VERSION "HIPBNNNYNNNNNNNNNNNNNNNNNNNNNNNNNNYYNNNNNN/4>%%%/4/'%**4NNN///"

NS_ :

BS_:

BU_: ADC CDC DDM VNC Vector_XXX

BO_ 417 AVN1SD6: 32 CDC
 SG_ FRMSID1 : 7|5@0+ (1,0) [0|0] "-"  ADC
 SG_ MAPCNTR : 2|2@0+ (1,0) [0|0] "-"  ADC
 SG_ NAVTYP : 0|3@0+ (1,0) [0|0] "-"  ADC
 SG_ MNAVOPST : 13|3@0+ (1,0) [0|0] "-"  ADC
 SG_ MNAVRGST : 10|2@0+ (1,0) [0|0] "-"  ADC
 SG_ DAYLOCUP : 8|16@0+ (1,0) [0|0] "-"  ADC
 SG_ DAYCENUP : 24|16@0+ (1,0) [0|0] "-"  ADC
 SG_ SUBDIVCD : 40|6@0+ (1,0) [0|0] "-"  ADC
 SG_ SNBINF3 : 50|3@0+ (1,0) [0|0] "-"  ADC
 SG_ SNBINF4 : 63|3@0+ (1,0) [0|0] "-"  ADC
 SG_ SNBUNT3 : 60|1@0+ (1,0) [0|0] "-"  ADC
 SG_ SNBUNT4 : 59|1@0+ (1,0) [0|0] "-"  ADC
 SG_ SNBDIST3 : 58|8@0+ (1,0) [0|0] "m"  ADC
 SG_ SNBDIST4 : 66|8@0+ (1,0) [0|0] "m"  ADC
 SG_ SPLUNT3 : 74|1@0+ (1,0) [0|0] "-"  ADC
 SG_ SPLUNT4 : 73|1@0+ (1,0) [0|0] "-"  ADC
 SG_ SPLDIST3 : 72|8@0+ (1,0) [0|0] "m"  ADC
 SG_ SPLDIST4 : 80|8@0+ (1,0) [0|0] "m"  ADC
 SG_ STINF : 88|2@0+ (1,0) [0|0] "-"  ADC
 SG_ STDU : 102|1@0+ (1,0) [0|0] "-"  ADC
 SG_ STDIST : 101|8@0+ (1,0) [0|0] "m"  ADC
 SG_ TRLUNT3 : 109|1@0+ (1,0) [0|0] "-"  ADC
 SG_ TRLUNT4 : 108|1@0+ (1,0) [0|0] "-"  ADC
 SG_ TRLUNT5 : 107|1@0+ (1,0) [0|0] "-"  ADC
 SG_ TRLUNT6 : 106|1@0+ (1,0) [0|0] "-"  ADC
 SG_ TRLDIST3 : 105|8@0+ (1,0) [0|0] "m"  ADC
 SG_ TRLDIST4 : 113|8@0+ (1,0) [0|0] "m"  ADC
 SG_ TRLDIST5 : 121|8@0+ (1,0) [0|0] "m"  ADC
 SG_ TRLDIST6 : 129|8@0+ (1,0) [0|0] "m"  ADC
 SG_ TRLUNT1 : 137|1@0+ (1,0) [0|0] "-"  ADC
 SG_ TRLUNT2 : 136|1@0+ (1,0) [0|0] "-"  ADC
 SG_ TRLDIST1 : 151|8@0+ (1,0) [0|0] "m"  ADC
 SG_ TRLDIST2 : 159|8@0+ (1,0) [0|0] "m"  ADC
 SG_ SNBINF1 : 167|3@0+ (1,0) [0|0] "-"  ADC
 SG_ SNBUNT1 : 164|1@0+ (1,0) [0|0] "-"  ADC
 SG_ SNBDIST1 : 163|8@0+ (1,0) [0|0] "m"  ADC
 SG_ SNBINF2 : 171|3@0+ (1,0) [0|0] "-"  ADC
 SG_ SNBUNT2 : 168|1@0+ (1,0) [0|0] "-"  ADC
 SG_ SNBDIST2 : 183|8@0+ (1,0) [0|0] "m"  ADC
 SG_ SPLUNT1 : 191|1@0+ (1,0) [0|0] "-"  ADC
 SG_ SPLDIST1 : 190|8@0+ (1,0) [0|0] "m"  ADC
 SG_ SPLUNT2 : 198|1@0+ (1,0) [0|0] "-"  ADC
 SG_ SPLDIST2 : 197|8@0+ (1,0) [0|0] "m"  ADC
 SG_ SENSST : 205|3@0+ (1,0) [0|0] "-"  ADC
 SG_ SENSORF : 202|3@0+ (1,0) [0|0] "-"  ADC
 SG_ RTGUIDST : 215|2@0+ (1,0) [0|0] "-"  ADC
 SG_ MAPMCNFD : 213|8@0+ (1,0) [0|0] "-"  ADC
 SG_ MLTMDST : 221|2@0+ (1,0) [0|0] "-"  ADC
 SG_ MAPCVR : 219|2@0+ (1,0) [0|0] "-"  ADC
 SG_ MAPCNFLG : 217|2@0+ (1,0) [0|0] "-"  ADC
 SG_ MAPTYRO : 231|2@0+ (1,0) [0|0] "-"  ADC
 SG_ RERTCNTR : 229|4@0+ (1,0) [0|0] "-"  ADC
 SG_ CNTRYCD : 225|10@0+ (1,0) [0|0] "-"  ADC

BO_ 418 AVN1SD7: 32 CDC
 SG_ FRMSID2 : 7|5@0+ (1,0) [0|0] "-"  ADC
 SG_ TOLDU2 : 2|1@0+ (1,0) [0|0] "-"  ADC
 SG_ TOLDU3 : 1|1@0+ (1,0) [0|0] "-"  ADC
 SG_ TOLDIST2 : 0|8@0+ (1,0) [0|0] "m"  ADC
 SG_ TOLDIST3 : 8|8@0+ (1,0) [0|0] "m"  ADC
 SG_ TOLSTY2 : 16|8@0+ (1,0) [0|0] "-"  ADC
 SG_ TOLSTY3 : 24|8@0+ (1,0) [0|0] "-"  ADC
 SG_ PAYMT1 : 32|10@0+ (1,0) [0|0] "-"  ADC
 SG_ PAYMT2 : 54|10@0+ (1,0) [0|0] "-"  ADC
 SG_ PAYMT3 : 60|10@0+ (1,0) [0|0] "-"  ADC
 SG_ RLDXUNT3 : 66|1@0+ (1,0) [0|0] "-"  ADC
 SG_ RLDXUNT4 : 65|1@0+ (1,0) [0|0] "-"  ADC
 SG_ RLDXDST3 : 64|8@0+ (1,0) [0|0] "m"  ADC
 SG_ RLDXDST4 : 72|8@0+ (1,0) [0|0] "m"  ADC
 SG_ FWMED1 : 80|2@0+ (1,0) [0|0] "-"  ADC
 SG_ FWMED2 : 94|2@0+ (1,0) [0|0] "-"  ADC
 SG_ FWMED3 : 92|2@0+ (1,0) [0|0] "-"  ADC
 SG_ FWMED4 : 90|2@0+ (1,0) [0|0] "-"  ADC
 SG_ FWMED5 : 88|2@0+ (1,0) [0|0] "-"  ADC
 SG_ MEDDU1 : 102|1@0+ (1,0) [0|0] "-"  ADC
 SG_ MEDDU2 : 101|1@0+ (1,0) [0|0] "-"  ADC
 SG_ MEDDU3 : 100|1@0+ (1,0) [0|0] "-"  ADC
 SG_ MEDDU4 : 99|1@0+ (1,0) [0|0] "-"  ADC
 SG_ MEDDU5 : 98|1@0+ (1,0) [0|0] "-"  ADC
 SG_ MEDDIST1 : 97|8@0+ (1,0) [0|0] "m"  ADC
 SG_ MEDDIST2 : 105|8@0+ (1,0) [0|0] "m"  ADC
 SG_ MEDDIST3 : 113|8@0+ (1,0) [0|0] "m"  ADC
 SG_ MEDDIST4 : 121|8@0+ (1,0) [0|0] "m"  ADC
 SG_ MEDDIST5 : 129|8@0+ (1,0) [0|0] "m"  ADC
 SG_ MPMEDFLG : 137|2@0+ (1,0) [0|0] "-"  ADC
 SG_ MPLNNUM : 151|4@0+ (1,0) [0|0] "-"  ADC
 SG_ LNNUMDU1 : 147|1@0+ (1,0) [0|0] "-"  ADC
 SG_ LNNUMDU2 : 146|1@0+ (1,0) [0|0] "-"  ADC
 SG_ LNNUMDU3 : 145|1@0+ (1,0) [0|0] "-"  ADC
 SG_ LNNUM1 : 144|4@0+ (1,0) [0|0] "-"  ADC
 SG_ LNNUM2 : 156|4@0+ (1,0) [0|0] "-"  ADC
 SG_ LNNUM3 : 152|4@0+ (1,0) [0|0] "-"  ADC
 SG_ LNNUMD1 : 164|8@0+ (1,0) [0|0] "m"  ADC
 SG_ LNNUMD2 : 172|8@0+ (1,0) [0|0] "m"  ADC
 SG_ LNNUMD3 : 180|8@0+ (1,0) [0|0] "m"  ADC
 SG_ DFLGDU1 : 188|1@0+ (1,0) [0|0] "-"  ADC
 SG_ DFLGD1 : 187|8@0+ (1,0) [0|0] "m"  ADC
 SG_ DFLGD2 : 195|8@0+ (1,0) [0|0] "m"  ADC
 SG_ MPOSDFLG : 203|2@0+ (1,0) [0|0] "-"  ADC
 SG_ DWAYFLG1 : 201|2@0+ (1,0) [0|0] "-"  ADC
 SG_ DWAYFLG2 : 215|2@0+ (1,0) [0|0] "-"  ADC
 SG_ DFLGDU2 : 213|1@0+ (1,0) [0|0] "-"  ADC
 SG_ TOLDU1 : 212|1@0+ (1,0) [0|0] "-"  ADC
 SG_ TOLDIST1 : 211|8@0+ (1,0) [0|0] "m"  ADC
 SG_ TOLSTY1 : 219|8@0+ (1,0) [0|0] "-"  ADC
 SG_ RLDXUNT1 : 227|1@0+ (1,0) [0|0] "-"  ADC
 SG_ RLDXUNT2 : 226|1@0+ (1,0) [0|0] "-"  ADC
 SG_ RLDXDST1 : 225|8@0+ (1,0) [0|0] "m"  ADC
 SG_ RLDXDST2 : 233|8@0+ (1,0) [0|0] "m"  ADC

BO_ 440 AVN1SD8: 32 CDC
 SG_ FRMSID3 : 7|5@0+ (1,0) [0|0] "-"  ADC
 SG_ LNKTYP1 : 2|10@0+ (1,0) [0|0] "-"  ADC
 SG_ LNKTYP2 : 8|10@0+ (1,0) [0|0] "-"  ADC
 SG_ LNKTYP3 : 30|10@0+ (1,0) [0|0] "-"  ADC
 SG_ LNKTYP4 : 36|10@0+ (1,0) [0|0] "-"  ADC
 SG_ LNKTYP5 : 42|10@0+ (1,0) [0|0] "-"  ADC
 SG_ LNKTYP6 : 48|10@0+ (1,0) [0|0] "-"  ADC
 SG_ LNKTYP7 : 70|10@0+ (1,0) [0|0] "-"  ADC
 SG_ LNKTYP8 : 76|10@0+ (1,0) [0|0] "-"  ADC
 SG_ LNKTYP9 : 82|10@0+ (1,0) [0|0] "-"  ADC
 SG_ LNKTYP10 : 88|10@0+ (1,0) [0|0] "-"  ADC
 SG_ LNKDU1 : 110|1@0+ (1,0) [0|0] "-"  ADC
 SG_ LNKDU2 : 109|1@0+ (1,0) [0|0] "-"  ADC
 SG_ LNKDU3 : 108|1@0+ (1,0) [0|0] "-"  ADC
 SG_ LNKDU4 : 107|1@0+ (1,0) [0|0] "-"  ADC
 SG_ LNKDU5 : 106|1@0+ (1,0) [0|0] "-"  ADC
 SG_ LNKDU6 : 105|1@0+ (1,0) [0|0] "-"  ADC
 SG_ LNKDU7 : 104|1@0+ (1,0) [0|0] "-"  ADC
 SG_ LNKDU8 : 119|1@0+ (1,0) [0|0] "-"  ADC
 SG_ LNKDU9 : 118|1@0+ (1,0) [0|0] "-"  ADC
 SG_ LNKDU10 : 117|1@0+ (1,0) [0|0] "-"  ADC
 SG_ LNKD1 : 116|8@0+ (1,0) [0|0] "m"  ADC
 SG_ LNKD2 : 124|8@0+ (1,0) [0|0] "m"  ADC
 SG_ LNKD3 : 132|8@0+ (1,0) [0|0] "m"  ADC
 SG_ LNKD4 : 140|8@0+ (1,0) [0|0] "m"  ADC
 SG_ LNKD5 : 148|8@0+ (1,0) [0|0] "m"  ADC
 SG_ LNKD6 : 156|8@0+ (1,0) [0|0] "m"  ADC
 SG_ LNKD7 : 164|8@0+ (1,0) [0|0] "m"  ADC
 SG_ LNKD8 : 172|8@0+ (1,0) [0|0] "m"  ADC
 SG_ LNKD9 : 180|8@0+ (1,0) [0|0] "m"  ADC
 SG_ LNKD10 : 188|8@0+ (1,0) [0|0] "m"  ADC
 SG_ MPLNKTYP : 196|10@0+ (1,0) [0|0] "-"  ADC

BO_ 441 AVN1SD9: 32 CDC
 SG_ FRMSID4 : 7|5@0+ (1,0) [0|0] "-"  ADC
 SG_ MPSPLU : 2|2@0+ (1,0) [0|0] "-"  ADC
 SG_ FWSPD3 : 0|5@0+ (1,0) [0|0] "-"  ADC
 SG_ FWSPD4 : 11|5@0+ (1,0) [0|0] "-"  ADC
 SG_ FWSPD5 : 22|5@0+ (1,0) [0|0] "-"  ADC
 SG_ FWSPD6 : 17|5@0+ (1,0) [0|0] "-"  ADC
 SG_ FWSPD7 : 28|5@0+ (1,0) [0|0] "-"  ADC
 SG_ FWSPTY3 : 39|3@0+ (1,0) [0|0] "-"  ADC
 SG_ FWSPTY4 : 36|3@0+ (1,0) [0|0] "-"  ADC
 SG_ FWSPTY5 : 33|3@0+ (1,0) [0|0] "-"  ADC
 SG_ FWSPTY6 : 46|3@0+ (1,0) [0|0] "-"  ADC
 SG_ FWSPTY7 : 43|3@0+ (1,0) [0|0] "-"  ADC
 SG_ FWSPAU3 : 40|6@0+ (1,0) [0|0] "-"  ADC
 SG_ FWSPAU4 : 50|6@0+ (1,0) [0|0] "-"  ADC
 SG_ FWSPAU5 : 60|6@0+ (1,0) [0|0] "-"  ADC
 SG_ FWSPAU6 : 70|6@0+ (1,0) [0|0] "-"  ADC
 SG_ FWSPAU7 : 64|6@0+ (1,0) [0|0] "-"  ADC
 SG_ FWSPLU1 : 74|2@0+ (1,0) [0|0] "-"  ADC
 SG_ FWSPLU2 : 72|2@0+ (1,0) [0|0] "-"  ADC
 SG_ FWSPLU3 : 86|2@0+ (1,0) [0|0] "-"  ADC
 SG_ FWSPLU4 : 84|2@0+ (1,0) [0|0] "-"  ADC
 SG_ FWSPLU5 : 82|2@0+ (1,0) [0|0] "-"  ADC
 SG_ FWSPLU6 : 80|2@0+ (1,0) [0|0] "-"  ADC
 SG_ FWSPLU7 : 94|2@0+ (1,0) [0|0] "-"  ADC
 SG_ SPDISTU3 : 92|1@0+ (1,0) [0|0] "-"  ADC
 SG_ SPDISTU4 : 91|1@0+ (1,0) [0|0] "-"  ADC
 SG_ SPDISTU5 : 90|1@0+ (1,0) [0|0] "-"  ADC
 SG_ SPDISTU6 : 89|1@0+ (1,0) [0|0] "-"  ADC
 SG_ SPDISTU7 : 88|1@0+ (1,0) [0|0] "-"  ADC
 SG_ SPDIST3 : 103|8@0+ (1,0) [0|0] "m"  ADC
 SG_ SPDIST4 : 111|8@0+ (1,0) [0|0] "m"  ADC
 SG_ SPDIST5 : 119|8@0+ (1,0) [0|0] "m"  ADC
 SG_ SPDIST6 : 127|8@0+ (1,0) [0|0] "m"  ADC
 SG_ SPDIST7 : 135|8@0+ (1,0) [0|0] "m"  ADC
 SG_ MPOWFLG : 143|3@0+ (1,0) [0|0] "-"  ADC
 SG_ FWOWFLG1 : 140|3@0+ (1,0) [0|0] "-"  ADC
 SG_ OWDU1 : 137|1@0+ (1,0) [0|0] "-"  ADC
 SG_ OWDIST1 : 136|8@0+ (1,0) [0|0] "m"  ADC
 SG_ MPRDTYP : 144|5@0+ (1,0) [0|0] "-"  ADC
 SG_ FWRDTYP1 : 155|5@0+ (1,0) [0|0] "-"  ADC
 SG_ RDTYPDU1 : 166|1@0+ (1,0) [0|0] "-"  ADC
 SG_ RDTYPD1 : 165|8@0+ (1,0) [0|0] "m"  ADC
 SG_ FWRDTYP2 : 173|5@0+ (1,0) [0|0] "-"  ADC
 SG_ RDTYPDU2 : 168|1@0+ (1,0) [0|0] "-"  ADC
 SG_ RDTYPD2 : 183|8@0+ (1,0) [0|0] "m"  ADC
 SG_ MPSP1 : 191|5@0+ (1,0) [0|0] "-"  ADC
 SG_ MPSPTY1 : 186|3@0+ (1,0) [0|0] "-"  ADC
 SG_ MPSPAU1 : 199|6@0+ (1,0) [0|0] "-"  ADC
 SG_ FWSPD1 : 193|5@0+ (1,0) [0|0] "-"  ADC
 SG_ FWSPTY1 : 204|3@0+ (1,0) [0|0] "-"  ADC
 SG_ FWSPAU1 : 201|6@0+ (1,0) [0|0] "-"  ADC
 SG_ SPDISTU1 : 211|1@0+ (1,0) [0|0] "-"  ADC
 SG_ SPDIST1 : 210|8@0+ (1,0) [0|0] "m"  ADC
 SG_ FWSPD2 : 218|5@0+ (1,0) [0|0] "-"  ADC
 SG_ FWSPTY2 : 229|3@0+ (1,0) [0|0] "-"  ADC
 SG_ FWSPAU2 : 226|6@0+ (1,0) [0|0] "-"  ADC
 SG_ SPDISTU2 : 236|1@0+ (1,0) [0|0] "-"  ADC
 SG_ SPDIST2 : 235|8@0+ (1,0) [0|0] "m"  ADC

BO_ 439 AVN1SE1: 32 CDC
 SG_ FRMSID5 : 7|5@0+ (1,0) [0|0] "-"  ADC
 SG_ TNENTDU1 : 2|1@0+ (1,0) [0|0] "-"  ADC
 SG_ TNENTDU2 : 1|1@0+ (1,0) [0|0] "-"  ADC
 SG_ TNENTDU3 : 0|1@0+ (1,0) [0|0] "-"  ADC
 SG_ TNENTDU4 : 15|1@0+ (1,0) [0|0] "-"  ADC
 SG_ TNENTDU5 : 14|1@0+ (1,0) [0|0] "-"  ADC
 SG_ TNENTD1 : 13|8@0+ (1,0) [0|0] "m"  ADC
 SG_ TNENTD2 : 21|8@0+ (1,0) [0|0] "m"  ADC
 SG_ TNENTD3 : 29|8@0+ (1,0) [0|0] "m"  ADC
 SG_ TNENTD4 : 37|8@0+ (1,0) [0|0] "m"  ADC
 SG_ TNENTD5 : 45|8@0+ (1,0) [0|0] "m"  ADC
 SG_ TNVFLG1 : 53|1@0+ (1,0) [0|0] "-"  ADC
 SG_ TNVFLG2 : 52|1@0+ (1,0) [0|0] "-"  ADC
 SG_ TNVFLG3 : 51|1@0+ (1,0) [0|0] "-"  ADC
 SG_ TNVFLG4 : 50|1@0+ (1,0) [0|0] "-"  ADC
 SG_ TNVFLG5 : 49|1@0+ (1,0) [0|0] "-"  ADC
 SG_ TNLEN1 : 48|8@0+ (1,0) [0|0] "m"  ADC
 SG_ TNLEN2 : 56|8@0+ (1,0) [0|0] "m"  ADC
 SG_ TNLEN3 : 64|8@0+ (1,0) [0|0] "m"  ADC
 SG_ TNLEN4 : 72|8@0+ (1,0) [0|0] "m"  ADC
 SG_ TNLEN5 : 80|8@0+ (1,0) [0|0] "m"  ADC
 SG_ BRGDU1 : 88|1@0+ (1,0) [0|0] "-"  ADC
 SG_ BRGDU2 : 103|1@0+ (1,0) [0|0] "-"  ADC
 SG_ BRGDU3 : 102|1@0+ (1,0) [0|0] "-"  ADC
 SG_ BRGDIST1 : 101|8@0+ (1,0) [0|0] "m"  ADC
 SG_ BRGDIST2 : 109|8@0+ (1,0) [0|0] "m"  ADC
 SG_ BRGDIST3 : 117|8@0+ (1,0) [0|0] "m"  ADC
 SG_ BRGVFLG1 : 125|1@0+ (1,0) [0|0] "-"  ADC
 SG_ BRGVFLG2 : 124|1@0+ (1,0) [0|0] "-"  ADC
 SG_ BRGVFLG3 : 123|1@0+ (1,0) [0|0] "-"  ADC
 SG_ BRGLEN1 : 122|8@0+ (1,0) [0|0] "m"  ADC
 SG_ BRGLEN2 : 130|8@0+ (1,0) [0|0] "m"  ADC
 SG_ BRGLEN3 : 138|8@0+ (1,0) [0|0] "m"  ADC

BO_ 437 AVN1SE2: 32 CDC
 SG_ FRMSID6 : 7|5@0+ (1,0) [0|0] "-"  ADC
 SG_ MPOSCURV : 2|10@0- (1,0) [0|0] "-"  ADC
 SG_ CURINFO1 : 8|10@0- (1,0) [0|0] "-"  ADC
 SG_ CURINFO3 : 30|10@0- (1,0) [0|0] "-"  ADC
 SG_ CURINFO4 : 36|10@0- (1,0) [0|0] "-"  ADC
 SG_ MPCURACR : 42|2@0+ (1,0) [0|0] "-"  ADC
 SG_ PCURACR1 : 40|2@0+ (1,0) [0|0] "-"  ADC
 SG_ PCURACR2 : 54|2@0+ (1,0) [0|0] "-"  ADC
 SG_ PCURACR3 : 52|2@0+ (1,0) [0|0] "-"  ADC
 SG_ PCURACR4 : 50|2@0+ (1,0) [0|0] "-"  ADC
 SG_ SCURAC1 : 48|2@0+ (1,0) [0|0] "-"  ADC
 SG_ SCURAC2 : 62|2@0+ (1,0) [0|0] "-"  ADC
 SG_ SCURAC3 : 60|2@0+ (1,0) [0|0] "-"  ADC
 SG_ SCURAC4 : 58|2@0+ (1,0) [0|0] "-"  ADC
 SG_ SCURAC5 : 56|2@0+ (1,0) [0|0] "-"  ADC
 SG_ SCURAC6 : 70|2@0+ (1,0) [0|0] "-"  ADC
 SG_ SCURAC7 : 68|2@0+ (1,0) [0|0] "-"  ADC
 SG_ SCURAC8 : 66|2@0+ (1,0) [0|0] "-"  ADC
 SG_ SCURAC9 : 64|2@0+ (1,0) [0|0] "-"  ADC
 SG_ SCURAC10 : 78|2@0+ (1,0) [0|0] "-"  ADC
 SG_ SCURAC11 : 76|2@0+ (1,0) [0|0] "-"  ADC
 SG_ CURD1 : 74|10@0+ (1,0) [0|0] "-"  ADC
 SG_ CURD2 : 80|10@0+ (1,0) [0|0] "-"  ADC
 SG_ CURVAL11 : 102|10@0- (1,0) [0|0] "-"  ADC
 SG_ CURINF11 : 108|3@0+ (1,0) [0|0] "-"  ADC
 SG_ CURVAL9 : 105|10@0- (1,0) [0|0] "-"  ADC
 SG_ CURINF9 : 127|3@0+ (1,0) [0|0] "-"  ADC
 SG_ CURVAL10 : 124|10@0- (1,0) [0|0] "-"  ADC
 SG_ CURINF10 : 130|3@0+ (1,0) [0|0] "-"  ADC
 SG_ CURINFO2 : 143|10@0- (1,0) [0|0] "-"  ADC
 SG_ CURVAL1 : 149|10@0- (1,0) [0|0] "-"  ADC
 SG_ CURINF1 : 155|3@0+ (1,0) [0|0] "-"  ADC
 SG_ CURVAL2 : 152|10@0- (1,0) [0|0] "-"  ADC
 SG_ CURINF2 : 174|3@0+ (1,0) [0|0] "-"  ADC
 SG_ CURVAL3 : 171|10@0- (1,0) [0|0] "-"  ADC
 SG_ CURINF3 : 177|3@0+ (1,0) [0|0] "-"  ADC
 SG_ CURVAL4 : 190|10@0- (1,0) [0|0] "-"  ADC
 SG_ CURINF4 : 196|3@0+ (1,0) [0|0] "-"  ADC
 SG_ CURVAL5 : 193|10@0- (1,0) [0|0] "-"  ADC
 SG_ CURINF5 : 215|3@0+ (1,0) [0|0] "-"  ADC
 SG_ CURVAL6 : 212|10@0- (1,0) [0|0] "-"  ADC
 SG_ CURINF6 : 218|3@0+ (1,0) [0|0] "-"  ADC
 SG_ CURVAL7 : 231|10@0- (1,0) [0|0] "-"  ADC
 SG_ CURINF7 : 237|3@0+ (1,0) [0|0] "-"  ADC
 SG_ CURVAL8 : 234|10@0- (1,0) [0|0] "-"  ADC
 SG_ CURINF8 : 240|3@0+ (1,0) [0|0] "-"  ADC

BO_ 429 AVN1SE3: 32 CDC
 SG_ FRMSID7 : 7|5@0+ (1,0) [0|0] "-"  ADC
 SG_ CURD3 : 2|10@0+ (1,0) [0|0] "-"  ADC
 SG_ CURD4 : 8|10@0+ (1,0) [0|0] "-"  ADC
 SG_ CURD5 : 30|10@0+ (1,0) [0|0] "-"  ADC
 SG_ CURD6 : 36|10@0+ (1,0) [0|0] "-"  ADC
 SG_ CURD7 : 42|10@0+ (1,0) [0|0] "-"  ADC
 SG_ CURD8 : 48|10@0+ (1,0) [0|0] "-"  ADC
 SG_ CURD9 : 70|10@0+ (1,0) [0|0] "-"  ADC
 SG_ CURD10 : 76|10@0+ (1,0) [0|0] "-"  ADC
 SG_ CURD11 : 82|10@0+ (1,0) [0|0] "-"  ADC
 SG_ MPOSLOPE : 88|7@0- (1,0) [0|0] "-"  ADC
 SG_ SLPINF1 : 97|7@0- (1,0) [0|0] "-"  ADC
 SG_ SLPINF2 : 106|7@0- (1,0) [0|0] "-"  ADC
 SG_ SLPINF3 : 115|7@0- (1,0) [0|0] "-"  ADC
 SG_ SLPINF4 : 124|7@0- (1,0) [0|0] "-"  ADC
 SG_ SLPINF5 : 133|7@0- (1,0) [0|0] "-"  ADC
 SG_ MPSLPAC : 142|2@0+ (1,0) [0|0] "-"  ADC
 SG_ PSLPAC1 : 140|2@0+ (1,0) [0|0] "-"  ADC
 SG_ PSLPAC2 : 138|2@0+ (1,0) [0|0] "-"  ADC
 SG_ PSLPAC3 : 136|2@0+ (1,0) [0|0] "-"  ADC
 SG_ PSLPAC4 : 150|2@0+ (1,0) [0|0] "-"  ADC
 SG_ PSLPAC5 : 148|2@0+ (1,0) [0|0] "-"  ADC
 SG_ AVESLP1 : 146|7@0- (1,0) [0|0] "-"  ADC
 SG_ AVESLP2 : 155|7@0- (1,0) [0|0] "-"  ADC
 SG_ AVESLP3 : 164|7@0- (1,0) [0|0] "-"  ADC
 SG_ AVESLP4 : 173|7@0- (1,0) [0|0] "-"  ADC
 SG_ AVESLP5 : 182|7@0- (1,0) [0|0] "-"  ADC
 SG_ AVESLP6 : 191|7@0- (1,0) [0|0] "-"  ADC
 SG_ AVESLP7 : 184|7@0- (1,0) [0|0] "-"  ADC
 SG_ AVESLP8 : 193|7@0- (1,0) [0|0] "-"  ADC
 SG_ AVSLPAC1 : 202|2@0+ (1,0) [0|0] "-"  ADC
 SG_ AVSLPAC2 : 200|2@0+ (1,0) [0|0] "-"  ADC
 SG_ AVSLPAC3 : 214|2@0+ (1,0) [0|0] "-"  ADC
 SG_ AVSLPAC4 : 212|2@0+ (1,0) [0|0] "-"  ADC
 SG_ AVSLPAC5 : 210|2@0+ (1,0) [0|0] "-"  ADC
 SG_ AVSLPAC6 : 208|2@0+ (1,0) [0|0] "-"  ADC
 SG_ AVSLPAC7 : 222|2@0+ (1,0) [0|0] "-"  ADC
 SG_ AVSLPAC8 : 220|2@0+ (1,0) [0|0] "-"  ADC

BO_ 431 AVN1SE4: 32 CDC
 SG_ FRMSID8 : 7|5@0+ (1,0) [0|0] "-"  ADC
 SG_ INTID4 : 2|5@0+ (1,0) [0|0] "-"  ADC
 SG_ INTID5 : 13|5@0+ (1,0) [0|0] "-"  ADC
 SG_ INTID6 : 8|5@0+ (1,0) [0|0] "-"  ADC
 SG_ INTID7 : 19|5@0+ (1,0) [0|0] "-"  ADC
 SG_ INTID8 : 30|5@0+ (1,0) [0|0] "-"  ADC
 SG_ INTID9 : 25|5@0+ (1,0) [0|0] "-"  ADC
 SG_ INTID10 : 36|5@0+ (1,0) [0|0] "-"  ADC
 SG_ INTID11 : 47|5@0+ (1,0) [0|0] "-"  ADC
 SG_ INTID12 : 42|5@0+ (1,0) [0|0] "-"  ADC
 SG_ INTDU1 : 53|1@0+ (1,0) [0|0] "-"  ADC
 SG_ INTDU2 : 52|1@0+ (1,0) [0|0] "-"  ADC
 SG_ INTDU3 : 51|1@0+ (1,0) [0|0] "-"  ADC
 SG_ INTDU4 : 50|1@0+ (1,0) [0|0] "-"  ADC
 SG_ INTDU5 : 49|1@0+ (1,0) [0|0] "-"  ADC
 SG_ INTDU6 : 48|1@0+ (1,0) [0|0] "-"  ADC
 SG_ INTDU7 : 63|1@0+ (1,0) [0|0] "-"  ADC
 SG_ INTDU8 : 62|1@0+ (1,0) [0|0] "-"  ADC
 SG_ INTDU9 : 61|1@0+ (1,0) [0|0] "-"  ADC
 SG_ INTDU10 : 60|1@0+ (1,0) [0|0] "-"  ADC
 SG_ INTDU11 : 59|1@0+ (1,0) [0|0] "-"  ADC
 SG_ INTDU12 : 58|1@0+ (1,0) [0|0] "-"  ADC
 SG_ INTDIS4 : 57|8@0+ (1,0) [0|0] "m"  ADC
 SG_ INTDIS5 : 65|8@0+ (1,0) [0|0] "m"  ADC
 SG_ INTDIS6 : 73|8@0+ (1,0) [0|0] "m"  ADC
 SG_ INTDIS7 : 81|8@0+ (1,0) [0|0] "m"  ADC
 SG_ INTDIS8 : 89|8@0+ (1,0) [0|0] "m"  ADC
 SG_ INTDIS9 : 97|8@0+ (1,0) [0|0] "m"  ADC
 SG_ INTDIS10 : 105|8@0+ (1,0) [0|0] "m"  ADC
 SG_ INTDIS11 : 113|8@0+ (1,0) [0|0] "m"  ADC
 SG_ INTDIS12 : 121|8@0+ (1,0) [0|0] "m"  ADC
 SG_ INTNLN4 : 129|5@0+ (1,0) [0|0] "-"  ADC
 SG_ INTNLN5 : 140|5@0+ (1,0) [0|0] "-"  ADC
 SG_ INTNLN6 : 151|5@0+ (1,0) [0|0] "-"  ADC
 SG_ INTNLN7 : 146|5@0+ (1,0) [0|0] "-"  ADC
 SG_ INTNLN8 : 157|5@0+ (1,0) [0|0] "-"  ADC
 SG_ INTNLN9 : 152|5@0+ (1,0) [0|0] "-"  ADC
 SG_ INTNLN10 : 163|5@0+ (1,0) [0|0] "-"  ADC
 SG_ INTNLN11 : 174|5@0+ (1,0) [0|0] "-"  ADC
 SG_ INTNLN12 : 169|5@0+ (1,0) [0|0] "-"  ADC
 SG_ INTDIS3 : 180|8@0+ (1,0) [0|0] "m"  ADC
 SG_ INTNLN3 : 188|5@0+ (1,0) [0|0] "-"  ADC
 SG_ INTID3 : 199|5@0+ (1,0) [0|0] "-"  ADC
 SG_ INTDIS1 : 194|8@0+ (1,0) [0|0] "m"  ADC
 SG_ INTDIS2 : 202|8@0+ (1,0) [0|0] "m"  ADC
 SG_ INTNLN1 : 210|5@0+ (1,0) [0|0] "-"  ADC
 SG_ INTNLN2 : 221|5@0+ (1,0) [0|0] "-"  ADC
 SG_ INTID1 : 216|5@0+ (1,0) [0|0] "-"  ADC
 SG_ INTID2 : 227|5@0+ (1,0) [0|0] "-"  ADC

BO_ 432 AVN1SE5: 32 CDC
 SG_ FRMSID9 : 7|5@0+ (1,0) [0|0] "-"  ADC
 SG_ ENRDTY4 : 2|5@0+ (1,0) [0|0] "-"  ADC
 SG_ ENRDTY5 : 13|5@0+ (1,0) [0|0] "-"  ADC
 SG_ ENRDTY6 : 8|5@0+ (1,0) [0|0] "-"  ADC
 SG_ ENRDTY7 : 19|5@0+ (1,0) [0|0] "-"  ADC
 SG_ ENRDTY8 : 30|5@0+ (1,0) [0|0] "-"  ADC
 SG_ ENRDTY9 : 25|5@0+ (1,0) [0|0] "-"  ADC
 SG_ ENRDTY10 : 36|5@0+ (1,0) [0|0] "-"  ADC
 SG_ ENRDTY11 : 47|5@0+ (1,0) [0|0] "-"  ADC
 SG_ ENRDTY12 : 42|5@0+ (1,0) [0|0] "-"  ADC
 SG_ ENLNTY4 : 53|10@0+ (1,0) [0|0] "-"  ADC
 SG_ ENLNTY5 : 59|10@0+ (1,0) [0|0] "-"  ADC
 SG_ ENLNTY6 : 65|10@0+ (1,0) [0|0] "-"  ADC
 SG_ ENLNTY7 : 87|10@0+ (1,0) [0|0] "-"  ADC
 SG_ ENLNTY8 : 93|10@0+ (1,0) [0|0] "-"  ADC
 SG_ ENLNTY9 : 99|10@0+ (1,0) [0|0] "-"  ADC
 SG_ ENLNTY10 : 105|10@0+ (1,0) [0|0] "-"  ADC
 SG_ ENLNTY11 : 127|10@0+ (1,0) [0|0] "-"  ADC
 SG_ ENLNTY12 : 133|10@0+ (1,0) [0|0] "-"  ADC
 SG_ ENNMLN1 : 139|4@0+ (1,0) [0|0] "-"  ADC
 SG_ ENNMLN2 : 151|4@0+ (1,0) [0|0] "-"  ADC
 SG_ ENNMLN3 : 147|4@0+ (1,0) [0|0] "-"  ADC
 SG_ ENNMLN4 : 159|4@0+ (1,0) [0|0] "-"  ADC
 SG_ ENNMLN5 : 155|4@0+ (1,0) [0|0] "-"  ADC
 SG_ ENNMLN6 : 167|4@0+ (1,0) [0|0] "-"  ADC
 SG_ ENNMLN7 : 163|4@0+ (1,0) [0|0] "-"  ADC
 SG_ ENNMLN8 : 175|4@0+ (1,0) [0|0] "-"  ADC
 SG_ ENNMLN9 : 171|4@0+ (1,0) [0|0] "-"  ADC
 SG_ ENNMLN10 : 183|4@0+ (1,0) [0|0] "-"  ADC
 SG_ ENNMLN11 : 179|4@0+ (1,0) [0|0] "-"  ADC
 SG_ ENNMLN12 : 191|4@0+ (1,0) [0|0] "-"  ADC
 SG_ ENLNTY3 : 187|10@0+ (1,0) [0|0] "-"  ADC
 SG_ ENRDTY3 : 193|5@0+ (1,0) [0|0] "-"  ADC
 SG_ ENRDTY1 : 204|5@0+ (1,0) [0|0] "-"  ADC
 SG_ ENRDTY2 : 215|5@0+ (1,0) [0|0] "-"  ADC
 SG_ ENLNTY1 : 210|10@0+ (1,0) [0|0] "-"  ADC
 SG_ ENLNTY2 : 216|10@0+ (1,0) [0|0] "-"  ADC

BO_ 435 AVN1SE6: 32 CDC
 SG_ FRMSID10 : 7|5@0+ (1,0) [0|0] "-"  ADC
 SG_ ENSIG4 : 2|2@0+ (1,0) [0|0] "-"  ADC
 SG_ ENSIG5 : 0|2@0+ (1,0) [0|0] "-"  ADC
 SG_ ENSIG6 : 14|2@0+ (1,0) [0|0] "-"  ADC
 SG_ ENSIG7 : 12|2@0+ (1,0) [0|0] "-"  ADC
 SG_ ENSIG8 : 10|2@0+ (1,0) [0|0] "-"  ADC
 SG_ ENSIG9 : 8|2@0+ (1,0) [0|0] "-"  ADC
 SG_ ENSIG10 : 22|2@0+ (1,0) [0|0] "-"  ADC
 SG_ ENSIG11 : 20|2@0+ (1,0) [0|0] "-"  ADC
 SG_ ENSIG12 : 18|2@0+ (1,0) [0|0] "-"  ADC
 SG_ ENSIBD4 : 16|3@0+ (1,0) [0|0] "-"  ADC
 SG_ ENSIBD5 : 29|3@0+ (1,0) [0|0] "-"  ADC
 SG_ ENSIBD6 : 26|3@0+ (1,0) [0|0] "-"  ADC
 SG_ ENSIBD7 : 39|3@0+ (1,0) [0|0] "-"  ADC
 SG_ ENSIBD8 : 36|3@0+ (1,0) [0|0] "-"  ADC
 SG_ ENSIBD9 : 33|3@0+ (1,0) [0|0] "-"  ADC
 SG_ ENSIBD10 : 46|3@0+ (1,0) [0|0] "-"  ADC
 SG_ ENSIBD11 : 43|3@0+ (1,0) [0|0] "-"  ADC
 SG_ ENSIBD12 : 40|3@0+ (1,0) [0|0] "-"  ADC
 SG_ ALRDTY4 : 53|5@0+ (1,0) [0|0] "-"  ADC
 SG_ ALRDTY5 : 48|5@0+ (1,0) [0|0] "-"  ADC
 SG_ ALRDTY6 : 59|5@0+ (1,0) [0|0] "-"  ADC
 SG_ ALRDTY7 : 70|5@0+ (1,0) [0|0] "-"  ADC
 SG_ ALRDTY8 : 65|5@0+ (1,0) [0|0] "-"  ADC
 SG_ ALRDTY9 : 76|5@0+ (1,0) [0|0] "-"  ADC
 SG_ ALRDTY10 : 87|5@0+ (1,0) [0|0] "-"  ADC
 SG_ ALRDTY11 : 82|5@0+ (1,0) [0|0] "-"  ADC
 SG_ ALRDTY12 : 93|5@0+ (1,0) [0|0] "-"  ADC
 SG_ ALTYP4 : 88|10@0+ (1,0) [0|0] "-"  ADC
 SG_ ALTYP5 : 110|10@0+ (1,0) [0|0] "-"  ADC
 SG_ ALTYP6 : 116|10@0+ (1,0) [0|0] "-"  ADC
 SG_ ALTYP7 : 122|10@0+ (1,0) [0|0] "-"  ADC
 SG_ ALTYP8 : 128|10@0+ (1,0) [0|0] "-"  ADC
 SG_ ALTYP9 : 150|10@0+ (1,0) [0|0] "-"  ADC
 SG_ ALTYP10 : 156|10@0+ (1,0) [0|0] "-"  ADC
 SG_ ENPRI1 : 162|2@0+ (1,0) [0|0] "-"  ADC
 SG_ ENPRI2 : 160|2@0+ (1,0) [0|0] "-"  ADC
 SG_ ENPRI3 : 174|2@0+ (1,0) [0|0] "-"  ADC
 SG_ ENPRI4 : 172|2@0+ (1,0) [0|0] "-"  ADC
 SG_ ENPRI5 : 170|2@0+ (1,0) [0|0] "-"  ADC
 SG_ ENPRI6 : 168|2@0+ (1,0) [0|0] "-"  ADC
 SG_ ENPRI7 : 182|2@0+ (1,0) [0|0] "-"  ADC
 SG_ ENPRI8 : 180|2@0+ (1,0) [0|0] "-"  ADC
 SG_ ENPRI9 : 178|2@0+ (1,0) [0|0] "-"  ADC
 SG_ ENPRI10 : 176|2@0+ (1,0) [0|0] "-"  ADC
 SG_ ENPRI11 : 190|2@0+ (1,0) [0|0] "-"  ADC
 SG_ ENPRI12 : 188|2@0+ (1,0) [0|0] "-"  ADC
 SG_ ENSIG3 : 186|2@0+ (1,0) [0|0] "-"  ADC
 SG_ ENSIBD3 : 184|3@0+ (1,0) [0|0] "-"  ADC
 SG_ ENSIG1 : 197|2@0+ (1,0) [0|0] "-"  ADC
 SG_ ENSIG2 : 195|2@0+ (1,0) [0|0] "-"  ADC
 SG_ ALTYP1 : 193|10@0+ (1,0) [0|0] "-"  ADC
 SG_ ALRDTY1 : 215|5@0+ (1,0) [0|0] "-"  ADC
 SG_ ALTYP2 : 210|10@0+ (1,0) [0|0] "-"  ADC
 SG_ ALRDTY2 : 216|5@0+ (1,0) [0|0] "-"  ADC
 SG_ ENSIBD1 : 227|3@0+ (1,0) [0|0] "-"  ADC
 SG_ ENSIBD2 : 224|3@0+ (1,0) [0|0] "-"  ADC
 SG_ ALRDTY3 : 237|5@0+ (1,0) [0|0] "-"  ADC
 SG_ ALTYP3 : 232|10@0+ (1,0) [0|0] "-"  ADC

BO_ 436 AVN1SE7: 32 CDC
 SG_ FRMSID11 : 7|5@0+ (1,0) [0|0] "-"  ADC
 SG_ ALTYP11 : 2|10@0+ (1,0) [0|0] "-"  ADC
 SG_ ALTYP12 : 8|10@0+ (1,0) [0|0] "-"  ADC
 SG_ ALNLN4 : 30|4@0+ (1,0) [0|0] "-"  ADC
 SG_ ALNLN5 : 26|4@0+ (1,0) [0|0] "-"  ADC
 SG_ ALNLN6 : 38|4@0+ (1,0) [0|0] "-"  ADC
 SG_ ALNLN7 : 34|4@0+ (1,0) [0|0] "-"  ADC
 SG_ ALNLN8 : 46|4@0+ (1,0) [0|0] "-"  ADC
 SG_ ALNLN9 : 42|4@0+ (1,0) [0|0] "-"  ADC
 SG_ ALNLN10 : 54|4@0+ (1,0) [0|0] "-"  ADC
 SG_ ALNLN11 : 50|4@0+ (1,0) [0|0] "-"  ADC
 SG_ ALNLN12 : 62|4@0+ (1,0) [0|0] "-"  ADC
 SG_ ALNSIG1 : 58|2@0+ (1,0) [0|0] "-"  ADC
 SG_ ALNSIG2 : 56|2@0+ (1,0) [0|0] "-"  ADC
 SG_ ALNSIG3 : 70|2@0+ (1,0) [0|0] "-"  ADC
 SG_ ALNSIG4 : 68|2@0+ (1,0) [0|0] "-"  ADC
 SG_ ALNSIG5 : 66|2@0+ (1,0) [0|0] "-"  ADC
 SG_ ALNSIG6 : 64|2@0+ (1,0) [0|0] "-"  ADC
 SG_ ALNSIG7 : 78|2@0+ (1,0) [0|0] "-"  ADC
 SG_ ALNSIG8 : 76|2@0+ (1,0) [0|0] "-"  ADC
 SG_ ALNSIG9 : 74|2@0+ (1,0) [0|0] "-"  ADC
 SG_ ALNSIG10 : 72|2@0+ (1,0) [0|0] "-"  ADC
 SG_ ALNSIG11 : 86|2@0+ (1,0) [0|0] "-"  ADC
 SG_ ALNSIG12 : 84|2@0+ (1,0) [0|0] "-"  ADC
 SG_ ALNSBD1 : 82|3@0+ (1,0) [0|0] "-"  ADC
 SG_ ALNSBD2 : 95|3@0+ (1,0) [0|0] "-"  ADC
 SG_ ALNSBD3 : 92|3@0+ (1,0) [0|0] "-"  ADC
 SG_ ALNSBD4 : 89|3@0+ (1,0) [0|0] "-"  ADC
 SG_ ALNSBD5 : 102|3@0+ (1,0) [0|0] "-"  ADC
 SG_ ALNSBD6 : 99|3@0+ (1,0) [0|0] "-"  ADC
 SG_ ALNSBD7 : 96|3@0+ (1,0) [0|0] "-"  ADC
 SG_ ALNSBD8 : 109|3@0+ (1,0) [0|0] "-"  ADC
 SG_ ALNSBD9 : 106|3@0+ (1,0) [0|0] "-"  ADC
 SG_ ALNSBD10 : 119|3@0+ (1,0) [0|0] "-"  ADC
 SG_ ALNSBD11 : 116|3@0+ (1,0) [0|0] "-"  ADC
 SG_ ALNSBD12 : 113|3@0+ (1,0) [0|0] "-"  ADC
 SG_ ALNOW1 : 126|3@0+ (1,0) [0|0] "-"  ADC
 SG_ ALNOW2 : 123|3@0+ (1,0) [0|0] "-"  ADC
 SG_ ALNOW3 : 120|3@0+ (1,0) [0|0] "-"  ADC
 SG_ ALNOW4 : 133|3@0+ (1,0) [0|0] "-"  ADC
 SG_ ALNOW5 : 130|3@0+ (1,0) [0|0] "-"  ADC
 SG_ ALNOW6 : 143|3@0+ (1,0) [0|0] "-"  ADC
 SG_ ALNOW7 : 140|3@0+ (1,0) [0|0] "-"  ADC
 SG_ ALNOW8 : 137|3@0+ (1,0) [0|0] "-"  ADC
 SG_ ALNOW9 : 150|3@0+ (1,0) [0|0] "-"  ADC
 SG_ ALNOW10 : 147|3@0+ (1,0) [0|0] "-"  ADC
 SG_ ALNOW11 : 144|3@0+ (1,0) [0|0] "-"  ADC
 SG_ ALNOW12 : 157|3@0+ (1,0) [0|0] "-"  ADC
 SG_ ALNEN1 : 154|2@0+ (1,0) [0|0] "-"  ADC
 SG_ ALNEN2 : 152|2@0+ (1,0) [0|0] "-"  ADC
 SG_ ALNEN3 : 166|2@0+ (1,0) [0|0] "-"  ADC
 SG_ ALNEN4 : 164|2@0+ (1,0) [0|0] "-"  ADC
 SG_ ALNEN5 : 162|2@0+ (1,0) [0|0] "-"  ADC
 SG_ ALNEN6 : 160|2@0+ (1,0) [0|0] "-"  ADC
 SG_ ALNEN7 : 174|2@0+ (1,0) [0|0] "-"  ADC
 SG_ ALNEN8 : 172|2@0+ (1,0) [0|0] "-"  ADC
 SG_ ALNEN9 : 170|2@0+ (1,0) [0|0] "-"  ADC
 SG_ ALNEN10 : 168|2@0+ (1,0) [0|0] "-"  ADC
 SG_ ALNEN11 : 182|2@0+ (1,0) [0|0] "-"  ADC
 SG_ ALNEN12 : 180|2@0+ (1,0) [0|0] "-"  ADC
 SG_ ALANG4 : 178|5@0+ (1,0) [0|0] "-"  ADC
 SG_ ALANG5 : 189|5@0+ (1,0) [0|0] "-"  ADC
 SG_ ALANG6 : 184|5@0+ (1,0) [0|0] "-"  ADC
 SG_ ALANG7 : 195|5@0+ (1,0) [0|0] "-"  ADC
 SG_ ALANG8 : 206|5@0+ (1,0) [0|0] "-"  ADC
 SG_ ALANG9 : 201|5@0+ (1,0) [0|0] "-"  ADC
 SG_ ALANG10 : 212|5@0+ (1,0) [0|0] "-"  ADC
 SG_ ALANG11 : 223|5@0+ (1,0) [0|0] "-"  ADC
 SG_ ALANG12 : 218|5@0+ (1,0) [0|0] "-"  ADC
 SG_ ALANG1 : 229|5@0+ (1,0) [0|0] "-"  ADC
 SG_ ALANG2 : 224|5@0+ (1,0) [0|0] "-"  ADC
 SG_ ALNLN1 : 235|4@0+ (1,0) [0|0] "-"  ADC
 SG_ ALNLN2 : 247|4@0+ (1,0) [0|0] "-"  ADC
 SG_ ALNLN3 : 243|4@0+ (1,0) [0|0] "-"  ADC
 SG_ ALANG3 : 255|5@0+ (1,0) [0|0] "-"  ADC

BO_ 430 AVN1SE8: 32 CDC
 SG_ FRMSID12 : 7|5@0+ (1,0) [0|0] "-"  ADC
 SG_ ALCINF1 : 2|2@0+ (1,0) [0|0] "-"  ADC
 SG_ ALCINF2 : 0|2@0+ (1,0) [0|0] "-"  ADC
 SG_ ALCINF3 : 14|2@0+ (1,0) [0|0] "-"  ADC
 SG_ ALCINF4 : 12|2@0+ (1,0) [0|0] "-"  ADC
 SG_ ALCINF5 : 10|2@0+ (1,0) [0|0] "-"  ADC
 SG_ ALCINF6 : 8|2@0+ (1,0) [0|0] "-"  ADC
 SG_ ALCINF7 : 22|2@0+ (1,0) [0|0] "-"  ADC
 SG_ ALCINF8 : 20|2@0+ (1,0) [0|0] "-"  ADC
 SG_ ALCINF9 : 18|2@0+ (1,0) [0|0] "-"  ADC
 SG_ ALCINF10 : 16|2@0+ (1,0) [0|0] "-"  ADC
 SG_ ALCINF11 : 30|2@0+ (1,0) [0|0] "-"  ADC
 SG_ ALCINF12 : 28|2@0+ (1,0) [0|0] "-"  ADC
 SG_ NALINT7 : 26|5@0+ (1,0) [0|0] "-"  ADC
 SG_ NALINT8 : 37|5@0+ (1,0) [0|0] "-"  ADC
 SG_ NALINT9 : 32|5@0+ (1,0) [0|0] "-"  ADC
 SG_ NALINT10 : 43|5@0+ (1,0) [0|0] "-"  ADC
 SG_ NALINT11 : 54|5@0+ (1,0) [0|0] "-"  ADC
 SG_ NALINT12 : 49|5@0+ (1,0) [0|0] "-"  ADC
 SG_ NALINT13 : 60|5@0+ (1,0) [0|0] "-"  ADC
 SG_ NALINT14 : 71|5@0+ (1,0) [0|0] "-"  ADC
 SG_ NALINT15 : 66|5@0+ (1,0) [0|0] "-"  ADC
 SG_ NALINT16 : 77|5@0+ (1,0) [0|0] "-"  ADC
 SG_ NALINT17 : 72|5@0+ (1,0) [0|0] "-"  ADC
 SG_ NALINT18 : 83|5@0+ (1,0) [0|0] "-"  ADC
 SG_ NALINT19 : 94|5@0+ (1,0) [0|0] "-"  ADC
 SG_ NALINT20 : 89|5@0+ (1,0) [0|0] "-"  ADC
 SG_ NALINT21 : 100|5@0+ (1,0) [0|0] "-"  ADC
 SG_ NALINT22 : 111|5@0+ (1,0) [0|0] "-"  ADC
 SG_ NALINT23 : 106|5@0+ (1,0) [0|0] "-"  ADC
 SG_ NALINT24 : 117|5@0+ (1,0) [0|0] "-"  ADC
 SG_ NALRDT1 : 112|5@0+ (1,0) [0|0] "-"  ADC
 SG_ NALRDT2 : 123|5@0+ (1,0) [0|0] "-"  ADC
 SG_ NALRDT3 : 134|5@0+ (1,0) [0|0] "-"  ADC
 SG_ NALRDT4 : 129|5@0+ (1,0) [0|0] "-"  ADC
 SG_ NALRDT5 : 140|5@0+ (1,0) [0|0] "-"  ADC
 SG_ NALRDT6 : 151|5@0+ (1,0) [0|0] "-"  ADC
 SG_ NALRDT7 : 146|5@0+ (1,0) [0|0] "-"  ADC
 SG_ NALRDT8 : 157|5@0+ (1,0) [0|0] "-"  ADC
 SG_ NALRDT9 : 152|5@0+ (1,0) [0|0] "-"  ADC
 SG_ NALRDT10 : 163|5@0+ (1,0) [0|0] "-"  ADC
 SG_ NALRDT11 : 174|5@0+ (1,0) [0|0] "-"  ADC
 SG_ ALPRI1 : 169|2@0+ (1,0) [0|0] "-"  ADC
 SG_ ALPRI2 : 183|2@0+ (1,0) [0|0] "-"  ADC
 SG_ ALPRI3 : 181|2@0+ (1,0) [0|0] "-"  ADC
 SG_ ALPRI4 : 179|2@0+ (1,0) [0|0] "-"  ADC
 SG_ ALPRI5 : 177|2@0+ (1,0) [0|0] "-"  ADC
 SG_ ALPRI6 : 191|2@0+ (1,0) [0|0] "-"  ADC
 SG_ ALPRI7 : 189|2@0+ (1,0) [0|0] "-"  ADC
 SG_ ALPRI8 : 187|2@0+ (1,0) [0|0] "-"  ADC
 SG_ ALPRI9 : 185|2@0+ (1,0) [0|0] "-"  ADC
 SG_ ALPRI10 : 199|2@0+ (1,0) [0|0] "-"  ADC
 SG_ ALPRI11 : 197|2@0+ (1,0) [0|0] "-"  ADC
 SG_ ALPRI12 : 195|2@0+ (1,0) [0|0] "-"  ADC
 SG_ ALALF1 : 193|2@0+ (1,0) [0|0] "-"  ADC
 SG_ ALALF2 : 207|2@0+ (1,0) [0|0] "-"  ADC
 SG_ ALALF3 : 205|2@0+ (1,0) [0|0] "-"  ADC
 SG_ ALALF4 : 203|2@0+ (1,0) [0|0] "-"  ADC
 SG_ ALALF5 : 201|2@0+ (1,0) [0|0] "-"  ADC
 SG_ ALALF6 : 215|2@0+ (1,0) [0|0] "-"  ADC
 SG_ ALALF7 : 213|2@0+ (1,0) [0|0] "-"  ADC
 SG_ ALALF8 : 211|2@0+ (1,0) [0|0] "-"  ADC
 SG_ ALALF9 : 209|2@0+ (1,0) [0|0] "-"  ADC
 SG_ ALALF10 : 223|2@0+ (1,0) [0|0] "-"  ADC
 SG_ ALALF11 : 221|2@0+ (1,0) [0|0] "-"  ADC
 SG_ ALALF12 : 219|2@0+ (1,0) [0|0] "-"  ADC
 SG_ NALINT1 : 217|5@0+ (1,0) [0|0] "-"  ADC
 SG_ NALINT2 : 228|5@0+ (1,0) [0|0] "-"  ADC
 SG_ NALINT3 : 239|5@0+ (1,0) [0|0] "-"  ADC
 SG_ NALINT4 : 234|5@0+ (1,0) [0|0] "-"  ADC
 SG_ NALINT5 : 245|5@0+ (1,0) [0|0] "-"  ADC
 SG_ NALINT6 : 240|5@0+ (1,0) [0|0] "-"  ADC

BO_ 424 AVN1SE9: 32 CDC
 SG_ FRMSID13 : 7|5@0+ (1,0) [0|0] "-"  ADC
 SG_ NALRDT12 : 2|5@0+ (1,0) [0|0] "-"  ADC
 SG_ NALRDT13 : 13|5@0+ (1,0) [0|0] "-"  ADC
 SG_ NALRDT14 : 8|5@0+ (1,0) [0|0] "-"  ADC
 SG_ NALRDT15 : 19|5@0+ (1,0) [0|0] "-"  ADC
 SG_ NALRDT16 : 30|5@0+ (1,0) [0|0] "-"  ADC
 SG_ NALRDT17 : 25|5@0+ (1,0) [0|0] "-"  ADC
 SG_ NALRDT18 : 36|5@0+ (1,0) [0|0] "-"  ADC
 SG_ NALRDT19 : 47|5@0+ (1,0) [0|0] "-"  ADC
 SG_ NALRDT20 : 42|5@0+ (1,0) [0|0] "-"  ADC
 SG_ NALRDT21 : 53|5@0+ (1,0) [0|0] "-"  ADC
 SG_ NALRDT22 : 48|5@0+ (1,0) [0|0] "-"  ADC
 SG_ NALRDT23 : 59|5@0+ (1,0) [0|0] "-"  ADC
 SG_ NALRDT24 : 70|5@0+ (1,0) [0|0] "-"  ADC
 SG_ NALTYP7 : 65|10@0+ (1,0) [0|0] "-"  ADC
 SG_ NALTYP8 : 87|10@0+ (1,0) [0|0] "-"  ADC
 SG_ NALTYP9 : 93|10@0+ (1,0) [0|0] "-"  ADC
 SG_ NALTYP10 : 99|10@0+ (1,0) [0|0] "-"  ADC
 SG_ NALTYP11 : 105|10@0+ (1,0) [0|0] "-"  ADC
 SG_ NALTYP12 : 127|10@0+ (1,0) [0|0] "-"  ADC
 SG_ NALTYP13 : 133|10@0+ (1,0) [0|0] "-"  ADC
 SG_ NALTYP14 : 139|10@0+ (1,0) [0|0] "-"  ADC
 SG_ NALTYP15 : 145|10@0+ (1,0) [0|0] "-"  ADC
 SG_ NALTYP16 : 167|10@0+ (1,0) [0|0] "-"  ADC
 SG_ NALTYP17 : 173|10@0+ (1,0) [0|0] "-"  ADC
 SG_ NALTYP18 : 179|10@0+ (1,0) [0|0] "-"  ADC
 SG_ NALTYP1 : 185|10@0+ (1,0) [0|0] "-"  ADC
 SG_ NALTYP2 : 207|10@0+ (1,0) [0|0] "-"  ADC
 SG_ NALTYP3 : 213|10@0+ (1,0) [0|0] "-"  ADC
 SG_ NALTYP4 : 219|10@0+ (1,0) [0|0] "-"  ADC
 SG_ NALTYP5 : 225|10@0+ (1,0) [0|0] "-"  ADC
 SG_ NALTYP6 : 247|10@0+ (1,0) [0|0] "-"  ADC

BO_ 425 AVN1SF1: 32 CDC
 SG_ FRMSID14 : 7|5@0+ (1,0) [0|0] "-"  ADC
 SG_ NALTYP19 : 2|10@0+ (1,0) [0|0] "-"  ADC
 SG_ NALTYP20 : 8|10@0+ (1,0) [0|0] "-"  ADC
 SG_ NALTYP21 : 30|10@0+ (1,0) [0|0] "-"  ADC
 SG_ NALTYP22 : 36|10@0+ (1,0) [0|0] "-"  ADC
 SG_ NALTYP23 : 42|10@0+ (1,0) [0|0] "-"  ADC
 SG_ NALTYP24 : 48|10@0+ (1,0) [0|0] "-"  ADC
 SG_ NALNLN7 : 70|4@0+ (1,0) [0|0] "-"  ADC
 SG_ NALNLN8 : 66|4@0+ (1,0) [0|0] "-"  ADC
 SG_ NALNLN9 : 78|4@0+ (1,0) [0|0] "-"  ADC
 SG_ NALNLN10 : 74|4@0+ (1,0) [0|0] "-"  ADC
 SG_ NALNLN11 : 86|4@0+ (1,0) [0|0] "-"  ADC
 SG_ NALNLN12 : 82|4@0+ (1,0) [0|0] "-"  ADC
 SG_ NALNLN13 : 94|4@0+ (1,0) [0|0] "-"  ADC
 SG_ NALNLN14 : 90|4@0+ (1,0) [0|0] "-"  ADC
 SG_ NALNLN15 : 102|4@0+ (1,0) [0|0] "-"  ADC
 SG_ NALNLN16 : 98|4@0+ (1,0) [0|0] "-"  ADC
 SG_ NALNLN17 : 110|4@0+ (1,0) [0|0] "-"  ADC
 SG_ NALNLN18 : 106|4@0+ (1,0) [0|0] "-"  ADC
 SG_ NALNLN19 : 118|4@0+ (1,0) [0|0] "-"  ADC
 SG_ NALNLN20 : 114|4@0+ (1,0) [0|0] "-"  ADC
 SG_ NALNLN21 : 126|4@0+ (1,0) [0|0] "-"  ADC
 SG_ NALNLN22 : 122|4@0+ (1,0) [0|0] "-"  ADC
 SG_ NALNLN23 : 134|4@0+ (1,0) [0|0] "-"  ADC
 SG_ NALNLN24 : 130|4@0+ (1,0) [0|0] "-"  ADC
 SG_ NALSIG1 : 142|2@0+ (1,0) [0|0] "-"  ADC
 SG_ NALSIG2 : 140|2@0+ (1,0) [0|0] "-"  ADC
 SG_ NALSIG3 : 138|2@0+ (1,0) [0|0] "-"  ADC
 SG_ NALSIG4 : 136|2@0+ (1,0) [0|0] "-"  ADC
 SG_ NALSIG5 : 150|2@0+ (1,0) [0|0] "-"  ADC
 SG_ NALSIG6 : 148|2@0+ (1,0) [0|0] "-"  ADC
 SG_ NALSIG7 : 146|2@0+ (1,0) [0|0] "-"  ADC
 SG_ NALSIG8 : 144|2@0+ (1,0) [0|0] "-"  ADC
 SG_ NALSIG9 : 158|2@0+ (1,0) [0|0] "-"  ADC
 SG_ NALSIG10 : 156|2@0+ (1,0) [0|0] "-"  ADC
 SG_ NALSIG11 : 154|2@0+ (1,0) [0|0] "-"  ADC
 SG_ NALSIG12 : 152|2@0+ (1,0) [0|0] "-"  ADC
 SG_ NALSIG13 : 166|2@0+ (1,0) [0|0] "-"  ADC
 SG_ NALSIG14 : 164|2@0+ (1,0) [0|0] "-"  ADC
 SG_ NALSIG15 : 162|2@0+ (1,0) [0|0] "-"  ADC
 SG_ NALSIG16 : 160|2@0+ (1,0) [0|0] "-"  ADC
 SG_ NALSIG17 : 174|2@0+ (1,0) [0|0] "-"  ADC
 SG_ NALSIG18 : 172|2@0+ (1,0) [0|0] "-"  ADC
 SG_ NALSIG19 : 170|2@0+ (1,0) [0|0] "-"  ADC
 SG_ NALSIG20 : 168|2@0+ (1,0) [0|0] "-"  ADC
 SG_ NALSIG21 : 182|2@0+ (1,0) [0|0] "-"  ADC
 SG_ NALSIG22 : 180|2@0+ (1,0) [0|0] "-"  ADC
 SG_ NALSIG23 : 178|2@0+ (1,0) [0|0] "-"  ADC
 SG_ NALSIG24 : 176|2@0+ (1,0) [0|0] "-"  ADC
 SG_ NALSBD1 : 190|3@0+ (1,0) [0|0] "-"  ADC
 SG_ NALSBD2 : 187|3@0+ (1,0) [0|0] "-"  ADC
 SG_ NALSBD3 : 184|3@0+ (1,0) [0|0] "-"  ADC
 SG_ NALSBD4 : 197|3@0+ (1,0) [0|0] "-"  ADC
 SG_ NALSBD5 : 194|3@0+ (1,0) [0|0] "-"  ADC
 SG_ NALSBD6 : 207|3@0+ (1,0) [0|0] "-"  ADC
 SG_ NALSBD7 : 204|3@0+ (1,0) [0|0] "-"  ADC
 SG_ NALSBD8 : 201|3@0+ (1,0) [0|0] "-"  ADC
 SG_ NALSBD9 : 214|3@0+ (1,0) [0|0] "-"  ADC
 SG_ NALSBD10 : 211|3@0+ (1,0) [0|0] "-"  ADC
 SG_ NALSBD11 : 208|3@0+ (1,0) [0|0] "-"  ADC
 SG_ NALSBD12 : 221|3@0+ (1,0) [0|0] "-"  ADC
 SG_ NALSBD13 : 218|3@0+ (1,0) [0|0] "-"  ADC
 SG_ NALSBD14 : 231|3@0+ (1,0) [0|0] "-"  ADC
 SG_ NALSBD15 : 228|3@0+ (1,0) [0|0] "-"  ADC
 SG_ NALNLN1 : 225|4@0+ (1,0) [0|0] "-"  ADC
 SG_ NALNLN2 : 237|4@0+ (1,0) [0|0] "-"  ADC
 SG_ NALNLN3 : 233|4@0+ (1,0) [0|0] "-"  ADC
 SG_ NALNLN4 : 245|4@0+ (1,0) [0|0] "-"  ADC
 SG_ NALNLN5 : 241|4@0+ (1,0) [0|0] "-"  ADC
 SG_ NALNLN6 : 253|4@0+ (1,0) [0|0] "-"  ADC

BO_ 427 AVN1SF2: 32 CDC
 SG_ FRMSID15 : 7|5@0+ (1,0) [0|0] "-"  ADC
 SG_ NALSBD16 : 2|3@0+ (1,0) [0|0] "-"  ADC
 SG_ NALSBD17 : 15|3@0+ (1,0) [0|0] "-"  ADC
 SG_ NALSBD18 : 12|3@0+ (1,0) [0|0] "-"  ADC
 SG_ NALSBD19 : 9|3@0+ (1,0) [0|0] "-"  ADC
 SG_ NALSBD20 : 22|3@0+ (1,0) [0|0] "-"  ADC
 SG_ NALSBD21 : 19|3@0+ (1,0) [0|0] "-"  ADC
 SG_ NALSBD22 : 16|3@0+ (1,0) [0|0] "-"  ADC
 SG_ NALSBD23 : 29|3@0+ (1,0) [0|0] "-"  ADC
 SG_ NALSBD24 : 26|3@0+ (1,0) [0|0] "-"  ADC
 SG_ NALOW1 : 39|3@0+ (1,0) [0|0] "-"  ADC
 SG_ NALOW2 : 36|3@0+ (1,0) [0|0] "-"  ADC
 SG_ NALOW3 : 33|3@0+ (1,0) [0|0] "-"  ADC
 SG_ NALOW4 : 46|3@0+ (1,0) [0|0] "-"  ADC
 SG_ NALOW5 : 43|3@0+ (1,0) [0|0] "-"  ADC
 SG_ NALOW6 : 40|3@0+ (1,0) [0|0] "-"  ADC
 SG_ NALOW7 : 53|3@0+ (1,0) [0|0] "-"  ADC
 SG_ NALOW8 : 50|3@0+ (1,0) [0|0] "-"  ADC
 SG_ NALOW9 : 63|3@0+ (1,0) [0|0] "-"  ADC
 SG_ NALOW10 : 60|3@0+ (1,0) [0|0] "-"  ADC
 SG_ NALOW11 : 57|3@0+ (1,0) [0|0] "-"  ADC
 SG_ NALOW12 : 70|3@0+ (1,0) [0|0] "-"  ADC
 SG_ NALOW13 : 67|3@0+ (1,0) [0|0] "-"  ADC
 SG_ NALOW14 : 64|3@0+ (1,0) [0|0] "-"  ADC
 SG_ NALOW15 : 77|3@0+ (1,0) [0|0] "-"  ADC
 SG_ NALOW16 : 74|3@0+ (1,0) [0|0] "-"  ADC
 SG_ NALOW17 : 87|3@0+ (1,0) [0|0] "-"  ADC
 SG_ NALOW18 : 84|3@0+ (1,0) [0|0] "-"  ADC
 SG_ NALOW19 : 81|3@0+ (1,0) [0|0] "-"  ADC
 SG_ NALOW20 : 94|3@0+ (1,0) [0|0] "-"  ADC
 SG_ NALOW21 : 91|3@0+ (1,0) [0|0] "-"  ADC
 SG_ NALOW22 : 88|3@0+ (1,0) [0|0] "-"  ADC
 SG_ NALOW23 : 101|3@0+ (1,0) [0|0] "-"  ADC
 SG_ NALOW24 : 98|3@0+ (1,0) [0|0] "-"  ADC
 SG_ NALNEN7 : 111|2@0+ (1,0) [0|0] "-"  ADC
 SG_ NALNEN8 : 109|2@0+ (1,0) [0|0] "-"  ADC
 SG_ NALNEN9 : 107|2@0+ (1,0) [0|0] "-"  ADC
 SG_ NALNEN10 : 105|2@0+ (1,0) [0|0] "-"  ADC
 SG_ NALNEN11 : 119|2@0+ (1,0) [0|0] "-"  ADC
 SG_ NALNEN12 : 117|2@0+ (1,0) [0|0] "-"  ADC
 SG_ NALNEN13 : 115|2@0+ (1,0) [0|0] "-"  ADC
 SG_ NALNEN14 : 113|2@0+ (1,0) [0|0] "-"  ADC
 SG_ NALNEN15 : 127|2@0+ (1,0) [0|0] "-"  ADC
 SG_ NALNEN16 : 125|2@0+ (1,0) [0|0] "-"  ADC
 SG_ NALNEN17 : 123|2@0+ (1,0) [0|0] "-"  ADC
 SG_ NALNEN18 : 121|2@0+ (1,0) [0|0] "-"  ADC
 SG_ NALNEN19 : 135|2@0+ (1,0) [0|0] "-"  ADC
 SG_ NALNEN20 : 133|2@0+ (1,0) [0|0] "-"  ADC
 SG_ NALNEN21 : 131|2@0+ (1,0) [0|0] "-"  ADC
 SG_ NALNEN22 : 129|2@0+ (1,0) [0|0] "-"  ADC
 SG_ NALNEN23 : 143|2@0+ (1,0) [0|0] "-"  ADC
 SG_ NALNEN24 : 141|2@0+ (1,0) [0|0] "-"  ADC
 SG_ NALANG7 : 139|5@0+ (1,0) [0|0] "-"  ADC
 SG_ NALANG8 : 150|5@0+ (1,0) [0|0] "-"  ADC
 SG_ NALANG9 : 145|5@0+ (1,0) [0|0] "-"  ADC
 SG_ NALANG10 : 156|5@0+ (1,0) [0|0] "-"  ADC
 SG_ NALANG11 : 167|5@0+ (1,0) [0|0] "-"  ADC
 SG_ NALANG12 : 162|5@0+ (1,0) [0|0] "-"  ADC
 SG_ NALANG13 : 173|5@0+ (1,0) [0|0] "-"  ADC
 SG_ NALANG14 : 168|5@0+ (1,0) [0|0] "-"  ADC
 SG_ NALANG15 : 179|5@0+ (1,0) [0|0] "-"  ADC
 SG_ NALANG16 : 190|5@0+ (1,0) [0|0] "-"  ADC
 SG_ NALANG17 : 185|5@0+ (1,0) [0|0] "-"  ADC
 SG_ NALANG18 : 196|5@0+ (1,0) [0|0] "-"  ADC
 SG_ NALANG19 : 207|5@0+ (1,0) [0|0] "-"  ADC
 SG_ NALANG20 : 202|5@0+ (1,0) [0|0] "-"  ADC
 SG_ NALNEN1 : 213|2@0+ (1,0) [0|0] "-"  ADC
 SG_ NALANG1 : 211|5@0+ (1,0) [0|0] "-"  ADC
 SG_ NALNEN2 : 222|2@0+ (1,0) [0|0] "-"  ADC
 SG_ NALANG2 : 220|5@0+ (1,0) [0|0] "-"  ADC
 SG_ NALNEN3 : 231|2@0+ (1,0) [0|0] "-"  ADC
 SG_ NALANG3 : 229|5@0+ (1,0) [0|0] "-"  ADC
 SG_ NALNEN4 : 224|2@0+ (1,0) [0|0] "-"  ADC
 SG_ NALANG4 : 238|5@0+ (1,0) [0|0] "-"  ADC
 SG_ NALNEN5 : 233|2@0+ (1,0) [0|0] "-"  ADC
 SG_ NALANG5 : 247|5@0+ (1,0) [0|0] "-"  ADC
 SG_ NALNEN6 : 242|2@0+ (1,0) [0|0] "-"  ADC
 SG_ NALANG6 : 240|5@0+ (1,0) [0|0] "-"  ADC

BO_ 428 AVN1SF3: 32 CDC
 SG_ FRMSID16 : 7|5@0+ (1,0) [0|0] "-"  ADC
 SG_ BRDU1 : 2|1@0+ (1,0) [0|0] "-"  ADC
 SG_ BRDU2 : 1|1@0+ (1,0) [0|0] "-"  ADC
 SG_ BRDU3 : 0|1@0+ (1,0) [0|0] "-"  ADC
 SG_ BRDIST1 : 15|8@0+ (1,0) [0|0] "m"  ADC
 SG_ BRDIST2 : 23|8@0+ (1,0) [0|0] "m"  ADC
 SG_ BRDIST3 : 31|8@0+ (1,0) [0|0] "m"  ADC
 SG_ BRVFLG1 : 39|1@0+ (1,0) [0|0] "-"  ADC
 SG_ BRVFLG2 : 38|1@0+ (1,0) [0|0] "-"  ADC
 SG_ BRVFLG3 : 37|1@0+ (1,0) [0|0] "-"  ADC
 SG_ BRLEN1 : 36|8@0+ (1,0) [0|0] "m"  ADC
 SG_ BRLEN2 : 44|8@0+ (1,0) [0|0] "m"  ADC
 SG_ BRLEN3 : 52|8@0+ (1,0) [0|0] "m"  ADC
 SG_ NALANG21 : 60|5@0+ (1,0) [0|0] "-"  ADC
 SG_ NALANG22 : 71|5@0+ (1,0) [0|0] "-"  ADC
 SG_ NALANG23 : 66|5@0+ (1,0) [0|0] "-"  ADC
 SG_ NALANG24 : 77|5@0+ (1,0) [0|0] "-"  ADC
 SG_ NALCNF1 : 72|2@0+ (1,0) [0|0] "-"  ADC
 SG_ NALCNF2 : 86|2@0+ (1,0) [0|0] "-"  ADC
 SG_ NALCNF3 : 84|2@0+ (1,0) [0|0] "-"  ADC
 SG_ NALCNF4 : 82|2@0+ (1,0) [0|0] "-"  ADC
 SG_ NALCNF5 : 80|2@0+ (1,0) [0|0] "-"  ADC
 SG_ NALCNF6 : 94|2@0+ (1,0) [0|0] "-"  ADC
 SG_ NALCNF7 : 92|2@0+ (1,0) [0|0] "-"  ADC
 SG_ NALCNF8 : 90|2@0+ (1,0) [0|0] "-"  ADC
 SG_ NALCNF9 : 88|2@0+ (1,0) [0|0] "-"  ADC
 SG_ NALCNF10 : 102|2@0+ (1,0) [0|0] "-"  ADC
 SG_ NALCNF11 : 100|2@0+ (1,0) [0|0] "-"  ADC
 SG_ NALCNF12 : 98|2@0+ (1,0) [0|0] "-"  ADC
 SG_ NALCNF13 : 96|2@0+ (1,0) [0|0] "-"  ADC
 SG_ NALCNF14 : 110|2@0+ (1,0) [0|0] "-"  ADC
 SG_ NALCNF15 : 108|2@0+ (1,0) [0|0] "-"  ADC
 SG_ NALCNF16 : 106|2@0+ (1,0) [0|0] "-"  ADC
 SG_ NALCNF17 : 104|2@0+ (1,0) [0|0] "-"  ADC
 SG_ NALCNF18 : 118|2@0+ (1,0) [0|0] "-"  ADC
 SG_ NALCNF19 : 116|2@0+ (1,0) [0|0] "-"  ADC
 SG_ NALCNF20 : 114|2@0+ (1,0) [0|0] "-"  ADC
 SG_ NALCNF21 : 112|2@0+ (1,0) [0|0] "-"  ADC
 SG_ NALCNF22 : 126|2@0+ (1,0) [0|0] "-"  ADC
 SG_ NALCNF23 : 124|2@0+ (1,0) [0|0] "-"  ADC
 SG_ NALCNF24 : 122|2@0+ (1,0) [0|0] "-"  ADC
 SG_ NALDIV1 : 120|3@0+ (1,0) [0|0] "-"  ADC
 SG_ NALDIV2 : 133|3@0+ (1,0) [0|0] "-"  ADC
 SG_ NALDIV3 : 130|3@0+ (1,0) [0|0] "-"  ADC
 SG_ NALDIV4 : 143|3@0+ (1,0) [0|0] "-"  ADC
 SG_ NALDIV5 : 140|3@0+ (1,0) [0|0] "-"  ADC
 SG_ NALDIV6 : 137|3@0+ (1,0) [0|0] "-"  ADC
 SG_ NALDIV7 : 150|3@0+ (1,0) [0|0] "-"  ADC
 SG_ NALDIV8 : 147|3@0+ (1,0) [0|0] "-"  ADC
 SG_ NALDIV9 : 144|3@0+ (1,0) [0|0] "-"  ADC
 SG_ NALDIV10 : 157|3@0+ (1,0) [0|0] "-"  ADC
 SG_ NALDIV11 : 154|3@0+ (1,0) [0|0] "-"  ADC
 SG_ NALDIV12 : 167|3@0+ (1,0) [0|0] "-"  ADC
 SG_ NALDIV13 : 164|3@0+ (1,0) [0|0] "-"  ADC
 SG_ NALDIV14 : 161|3@0+ (1,0) [0|0] "-"  ADC
 SG_ NALDIV15 : 174|3@0+ (1,0) [0|0] "-"  ADC
 SG_ NALDIV16 : 171|3@0+ (1,0) [0|0] "-"  ADC
 SG_ NALDIV17 : 168|3@0+ (1,0) [0|0] "-"  ADC
 SG_ NALDIV18 : 181|3@0+ (1,0) [0|0] "-"  ADC
 SG_ NALDIV19 : 178|3@0+ (1,0) [0|0] "-"  ADC
 SG_ NALDIV20 : 191|3@0+ (1,0) [0|0] "-"  ADC
 SG_ NALDIV21 : 188|3@0+ (1,0) [0|0] "-"  ADC
 SG_ NALDIV22 : 185|3@0+ (1,0) [0|0] "-"  ADC
 SG_ NALDIV23 : 198|3@0+ (1,0) [0|0] "-"  ADC
 SG_ NALDIV24 : 195|3@0+ (1,0) [0|0] "-"  ADC
 SG_ NALPRI1 : 192|2@0+ (1,0) [0|0] "-"  ADC
 SG_ NALPRI2 : 206|2@0+ (1,0) [0|0] "-"  ADC
 SG_ NALPRI3 : 204|2@0+ (1,0) [0|0] "-"  ADC
 SG_ NALPRI4 : 202|2@0+ (1,0) [0|0] "-"  ADC
 SG_ NALPRI5 : 200|2@0+ (1,0) [0|0] "-"  ADC
 SG_ NALPRI6 : 214|2@0+ (1,0) [0|0] "-"  ADC
 SG_ NALPRI7 : 212|2@0+ (1,0) [0|0] "-"  ADC
 SG_ NALPRI8 : 210|2@0+ (1,0) [0|0] "-"  ADC
 SG_ NALPRI9 : 208|2@0+ (1,0) [0|0] "-"  ADC
 SG_ NALPRI10 : 222|2@0+ (1,0) [0|0] "-"  ADC
 SG_ NALPRI11 : 220|2@0+ (1,0) [0|0] "-"  ADC
 SG_ NALPRI12 : 218|2@0+ (1,0) [0|0] "-"  ADC
 SG_ NALPRI13 : 216|2@0+ (1,0) [0|0] "-"  ADC
 SG_ NALPRI14 : 230|2@0+ (1,0) [0|0] "-"  ADC
 SG_ NALPRI15 : 228|2@0+ (1,0) [0|0] "-"  ADC
 SG_ NALPRI16 : 226|2@0+ (1,0) [0|0] "-"  ADC
 SG_ NALPRI17 : 224|2@0+ (1,0) [0|0] "-"  ADC
 SG_ NALPRI18 : 238|2@0+ (1,0) [0|0] "-"  ADC
 SG_ NALPRI19 : 236|2@0+ (1,0) [0|0] "-"  ADC
 SG_ NALPRI20 : 234|2@0+ (1,0) [0|0] "-"  ADC
 SG_ NALPRI21 : 232|2@0+ (1,0) [0|0] "-"  ADC
 SG_ NALPRI22 : 246|2@0+ (1,0) [0|0] "-"  ADC
 SG_ NALPRI23 : 244|2@0+ (1,0) [0|0] "-"  ADC
 SG_ NALPRI24 : 242|2@0+ (1,0) [0|0] "-"  ADC
 SG_ NALALF1 : 240|2@0+ (1,0) [0|0] "-"  ADC
 SG_ NALALF2 : 254|2@0+ (1,0) [0|0] "-"  ADC
 SG_ NALALF3 : 252|2@0+ (1,0) [0|0] "-"  ADC
 SG_ NALALF4 : 250|2@0+ (1,0) [0|0] "-"  ADC

BO_ 421 AVN1SF4: 32 CDC
 SG_ FMMC1 : 7|32@0+ (1,0) [0|0] "-"  ADC
 SG_ FMMC2 : 39|32@0+ (1,0) [0|0] "-"  ADC
 SG_ MPOTJ : 71|3@0+ (1,0) [0|0] "-"  ADC
 SG_ FWTJ1 : 68|3@0+ (1,0) [0|0] "-"  ADC
 SG_ FWTJ2 : 65|3@0+ (1,0) [0|0] "-"  ADC
 SG_ FWTJ3 : 78|3@0+ (1,0) [0|0] "-"  ADC
 SG_ FWTJ4 : 75|3@0+ (1,0) [0|0] "-"  ADC
 SG_ FWTJ5 : 72|3@0+ (1,0) [0|0] "-"  ADC
 SG_ FWTJ6 : 85|3@0+ (1,0) [0|0] "-"  ADC
 SG_ TJDISTU1 : 82|1@0+ (1,0) [0|0] "-"  ADC
 SG_ TJDISTU2 : 81|1@0+ (1,0) [0|0] "-"  ADC
 SG_ TJDISTU3 : 80|1@0+ (1,0) [0|0] "-"  ADC
 SG_ TJDISTU4 : 95|1@0+ (1,0) [0|0] "-"  ADC
 SG_ TJDISTU5 : 94|1@0+ (1,0) [0|0] "-"  ADC
 SG_ TJDISTU6 : 93|1@0+ (1,0) [0|0] "-"  ADC
 SG_ TJDIST1 : 92|8@0+ (1,0) [0|0] "m"  ADC
 SG_ TJDIST2 : 100|8@0+ (1,0) [0|0] "m"  ADC
 SG_ TJDIST3 : 108|8@0+ (1,0) [0|0] "m"  ADC
 SG_ TJDIST4 : 116|8@0+ (1,0) [0|0] "m"  ADC
 SG_ TJDIST5 : 124|8@0+ (1,0) [0|0] "m"  ADC
 SG_ TJDIST6 : 132|8@0+ (1,0) [0|0] "m"  ADC
 SG_ SBSTDTU : 140|1@0+ (1,0) [0|0] "-"  ADC
 SG_ SBSTDT : 139|8@0+ (1,0) [0|0] "m"  ADC
 SG_ SBLENFLG : 147|1@0+ (1,0) [0|0] "-"  ADC
 SG_ SBLEN : 146|8@0+ (1,0) [0|0] "m"  ADC
 SG_ NSPVAL1 : 154|5@0+ (1,0) [0|0] "-"  ADC
 SG_ NSPVAL2 : 165|5@0+ (1,0) [0|0] "-"  ADC
 SG_ NSPVAL3 : 160|5@0+ (1,0) [0|0] "-"  ADC
 SG_ NSPVAL4 : 171|5@0+ (1,0) [0|0] "-"  ADC
 SG_ NSPVAL5 : 182|5@0+ (1,0) [0|0] "-"  ADC
 SG_ NSPVAL6 : 177|5@0+ (1,0) [0|0] "-"  ADC
 SG_ NALALF5 : 188|2@0+ (1,0) [0|0] "-"  ADC
 SG_ NALALF6 : 186|2@0+ (1,0) [0|0] "-"  ADC
 SG_ NALALF7 : 184|2@0+ (1,0) [0|0] "-"  ADC
 SG_ NALALF8 : 198|2@0+ (1,0) [0|0] "-"  ADC
 SG_ NALALF9 : 196|2@0+ (1,0) [0|0] "-"  ADC
 SG_ NALALF10 : 194|2@0+ (1,0) [0|0] "-"  ADC
 SG_ NALALF11 : 192|2@0+ (1,0) [0|0] "-"  ADC
 SG_ NALALF12 : 206|2@0+ (1,0) [0|0] "-"  ADC
 SG_ NALALF13 : 204|2@0+ (1,0) [0|0] "-"  ADC
 SG_ NALALF14 : 202|2@0+ (1,0) [0|0] "-"  ADC
 SG_ NALALF15 : 200|2@0+ (1,0) [0|0] "-"  ADC
 SG_ NALALF16 : 214|2@0+ (1,0) [0|0] "-"  ADC
 SG_ NALALF17 : 212|2@0+ (1,0) [0|0] "-"  ADC
 SG_ NALALF18 : 210|2@0+ (1,0) [0|0] "-"  ADC
 SG_ NALALF19 : 208|2@0+ (1,0) [0|0] "-"  ADC
 SG_ NALALF20 : 222|2@0+ (1,0) [0|0] "-"  ADC
 SG_ NALALF21 : 220|2@0+ (1,0) [0|0] "-"  ADC
 SG_ NALALF22 : 218|2@0+ (1,0) [0|0] "-"  ADC
 SG_ NALALF23 : 216|2@0+ (1,0) [0|0] "-"  ADC
 SG_ NALALF24 : 230|2@0+ (1,0) [0|0] "-"  ADC
 SG_ FRMSID17 : 228|5@0+ (1,0) [0|0] "-"  ADC
 SG_ FNSPLSN1 : 239|4@0+ (1,0) [0|0] "-"  ADC
 SG_ FNSPLSN2 : 235|4@0+ (1,0) [0|0] "-"  ADC
 SG_ FNSPLSN3 : 247|4@0+ (1,0) [0|0] "-"  ADC
 SG_ FNSPLSN4 : 243|4@0+ (1,0) [0|0] "-"  ADC
 SG_ FNSPLSN5 : 255|4@0+ (1,0) [0|0] "-"  ADC
 SG_ FNSPLSN6 : 251|4@0+ (1,0) [0|0] "-"  ADC

BO_ 423 AVN1SF5: 32 CDC
 SG_ FLID : 7|32@0+ (1,0) [0|0] "-"  ADC
 SG_ FDLID : 39|16@0+ (1,0) [0|0] "-"  ADC
 SG_ FRCODE : 55|16@0+ (1,0) [0|0] "-"  ADC
 SG_ FDLINKP : 71|16@0+ (1,0) [0|0] "m"  ADC
 SG_ MPOAVSP : 87|5@0+ (1,0) [0|0] "-"  ADC
 SG_ MPOAVSPU : 82|2@0+ (1,0) [0|0] "-"  ADC
 SG_ FWAVSP1 : 80|5@0+ (1,0) [0|0] "-"  ADC
 SG_ FWAVSP2 : 91|5@0+ (1,0) [0|0] "-"  ADC
 SG_ FWAVSP3 : 102|5@0+ (1,0) [0|0] "-"  ADC
 SG_ FWAVSP4 : 97|5@0+ (1,0) [0|0] "-"  ADC
 SG_ FWAVSP5 : 108|5@0+ (1,0) [0|0] "-"  ADC
 SG_ FWAVSP6 : 119|5@0+ (1,0) [0|0] "-"  ADC
 SG_ FWAVSPU1 : 114|2@0+ (1,0) [0|0] "-"  ADC
 SG_ FWAVSPU2 : 112|2@0+ (1,0) [0|0] "-"  ADC
 SG_ FWAVSPU3 : 126|2@0+ (1,0) [0|0] "-"  ADC
 SG_ FWAVSPU4 : 124|2@0+ (1,0) [0|0] "-"  ADC
 SG_ FWAVSPU5 : 122|2@0+ (1,0) [0|0] "-"  ADC
 SG_ FWAVSPU6 : 120|2@0+ (1,0) [0|0] "-"  ADC
 SG_ AVSPDTU1 : 134|1@0+ (1,0) [0|0] "-"  ADC
 SG_ AVSPDTU2 : 133|1@0+ (1,0) [0|0] "-"  ADC
 SG_ AVSPDTU3 : 132|1@0+ (1,0) [0|0] "-"  ADC
 SG_ AVSPDTU4 : 131|1@0+ (1,0) [0|0] "-"  ADC
 SG_ AVSPDTU5 : 130|1@0+ (1,0) [0|0] "-"  ADC
 SG_ AVSPDTU6 : 129|1@0+ (1,0) [0|0] "-"  ADC
 SG_ AVSPDT1 : 128|8@0+ (1,0) [0|0] "m"  ADC
 SG_ AVSPDT2 : 136|8@0+ (1,0) [0|0] "m"  ADC
 SG_ AVSPDT3 : 144|8@0+ (1,0) [0|0] "m"  ADC
 SG_ AVSPDT4 : 152|8@0+ (1,0) [0|0] "m"  ADC
 SG_ AVSPDT5 : 160|8@0+ (1,0) [0|0] "m"  ADC
 SG_ AVSPDT6 : 168|8@0+ (1,0) [0|0] "m"  ADC
 SG_ FRMSID18 : 176|5@0+ (1,0) [0|0] "-"  ADC
 SG_ NMAPVER : 199|16@0+ (1,0) [0|0] "-"  ADC

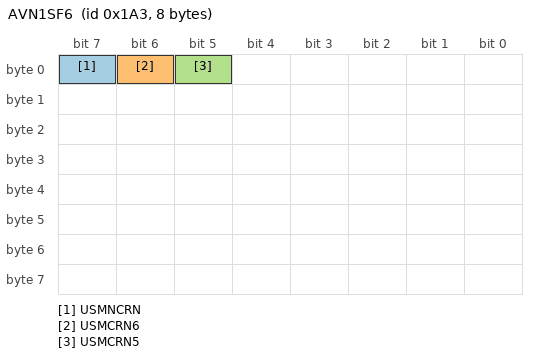
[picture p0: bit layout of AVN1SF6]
BO_ 419 AVN1SF6: 8 CDC
 SG_ USMNCRN : 7|1@0+ (1,0) [0|0] "-"  ADC
 SG_ USMCRN6 : 6|1@0+ (1,0) [0|0] "-"  ADC
 SG_ USMCRN5 : 5|1@0+ (1,0) [0|0] "-"  ADC

BO_ 759 AVN1SF7: 32 CDC
 SG_ BD_CLR_1 : 7|32@0+ (1,0) [0|0] "-"  ADC
 SG_ BD_CLR_2 : 39|32@0+ (1,0) [0|0] "-"  ADC
 SG_ BD_CLR_3 : 71|32@0+ (1,0) [0|0] "-"  ADC
 SG_ BD_CLR_4 : 103|10@0+ (1,0) [0|0] "-"  ADC
 SG_ BD_CLR_5 : 119|32@0+ (1,0) [0|0] "-"  ADC
 SG_ BD_CLR_6 : 151|32@0+ (1,0) [0|0] "-"  ADC
 SG_ BD_CLR_7 : 183|32@0+ (1,0) [0|0] "-"  ADC
 SG_ BD_CLR_8 : 215|10@0+ (1,0) [0|0] "-"  ADC
 SG_ CD_DSPST : 221|4@0+ (1,0) [0|0] "-"  ADC
 SG_ PVM_REQ : 217|2@0+ (1,0) [0|0] "-"  ADC

CM_ BO_ 417 "Reserve";
CM_ SG_ 417 FRMSID1 "Frame sync ID1";
CM_ SG_ 417 MAPCNTR "Map contract state";
CM_ SG_ 417 NAVTYP "Navi type";
CM_ SG_ 417 MNAVOPST "Smartphone navi operating state";
CM_ SG_ 417 MNAVRGST "Smartphone navi route guidance state";
CM_ SG_ 417 DAYLOCUP "Number of days elapsed since the last local map update";
CM_ SG_ 417 DAYCENUP "Number of days elapsed since the last center map update";
CM_ SG_ 417 SUBDIVCD "Subdivision code";
CM_ SG_ 417 SNBINF3 "Signboard info 3";
CM_ SG_ 417 SNBINF4 "Signboard info 4";
CM_ SG_ 417 SNBUNT3 "Distance unit to signboard 3";
CM_ SG_ 417 SNBUNT4 "Distance unit to signboard 4";
CM_ SG_ 417 SNBDIST3 "Distance to signboard 3";
CM_ SG_ 417 SNBDIST4 "Distance to signboard 4";
CM_ SG_ 417 SPLUNT3 "Distance unit to stop line 3";
CM_ SG_ 417 SPLUNT4 "Distance unit to stop line 4";
CM_ SG_ 417 SPLDIST3 "Distance to stop line 3";
CM_ SG_ 417 SPLDIST4 "Distance to stop line 4";
CM_ SG_ 417 STINF "Search termination information";
CM_ SG_ 417 STDU "Distance unit to search termination";
CM_ SG_ 417 STDIST "Distance to search termination";
CM_ SG_ 417 TRLUNT3 "Distance unit to traffic light 3";
CM_ SG_ 417 TRLUNT4 "Distance unit to traffic light 4";
CM_ SG_ 417 TRLUNT5 "Distance unit to traffic light 5";
CM_ SG_ 417 TRLUNT6 "Distance unit to traffic light 6";
CM_ SG_ 417 TRLDIST3 "Distance to traffic light 3";
CM_ SG_ 417 TRLDIST4 "Distance to traffic light 4";
CM_ SG_ 417 TRLDIST5 "Distance to traffic light 5";
CM_ SG_ 417 TRLDIST6 "Distance to traffic light 6";
CM_ SG_ 417 TRLUNT1 "Distance unit to traffic light 1";
CM_ SG_ 417 TRLUNT2 "Distance unit to traffic light 2";
CM_ SG_ 417 TRLDIST1 "Distance to traffic light 1";
CM_ SG_ 417 TRLDIST2 "Distance to traffic light 2";
CM_ SG_ 417 SNBINF1 "Signboard info 1";
CM_ SG_ 417 SNBUNT1 "Distance unit to signboard 1";
CM_ SG_ 417 SNBDIST1 "Distance to signboard 1";
CM_ SG_ 417 SNBINF2 "Signboard info 2";
CM_ SG_ 417 SNBUNT2 "Distance unit to signboard 2";
CM_ SG_ 417 SNBDIST2 "Distance to signboard 2";
CM_ SG_ 417 SPLUNT1 "Distance unit to stop line 1";
CM_ SG_ 417 SPLDIST1 "Distance to stop line 1";
CM_ SG_ 417 SPLUNT2 "Distance unit to stop line 2";
CM_ SG_ 417 SPLDIST2 "Distance to stop line 2";
CM_ SG_ 417 SENSST "Sensor performance";
CM_ SG_ 417 SENSORF "Sensor fail";
CM_ SG_ 417 RTGUIDST "Route guidance state";
CM_ SG_ 417 MAPMCNFD "Map matching confidence";
CM_ SG_ 417 MLTMDST "Multi media state";
CM_ SG_ 417 MAPCVR "Map coverage flag";
CM_ SG_ 417 MAPCNFLG "Online map connection flag";
CM_ SG_ 417 MAPTYRO "Map type along route";
CM_ SG_ 417 RERTCNTR "Reroute counter";
CM_ SG_ 417 CNTRYCD "Country code";
CM_ BO_ 418 "Reserve";
CM_ SG_ 418 FRMSID2 "Frame sync ID2";
CM_ SG_ 418 TOLDU2 "Distance unit to tollgate 2";
CM_ SG_ 418 TOLDU3 "Distance unit to tollgate 3";
CM_ SG_ 418 TOLDIST2 "Distance to tollgate 2";
CM_ SG_ 418 TOLDIST3 "Distance to tollgate 3";
CM_ SG_ 418 TOLSTY2 "Toll Structure Type 2";
CM_ SG_ 418 TOLSTY3 "Toll Structure Type 3";
CM_ SG_ 418 PAYMT1 "Payment Method 1";
CM_ SG_ 418 PAYMT2 "Payment Method 2";
CM_ SG_ 418 PAYMT3 "Payment Method 3";
CM_ SG_ 418 RLDXUNT3 "Distance unit to railroad crossing 3";
CM_ SG_ 418 RLDXUNT4 "Distance unit to railroad crossing 4";
CM_ SG_ 418 RLDXDST3 "Distance to railroad crossing 3";
CM_ SG_ 418 RLDXDST4 "Distance to railroad crossing 4";
CM_ SG_ 418 FWMED1 "Forward median divider flag 1";
CM_ SG_ 418 FWMED2 "Forward median divider flag 2";
CM_ SG_ 418 FWMED3 "Forward median divider flag 3";
CM_ SG_ 418 FWMED4 "Forward median divider flag 4";
CM_ SG_ 418 FWMED5 "Forward median divider flag 5";
CM_ SG_ 418 MEDDU1 "Distance unit to median divider 1";
CM_ SG_ 418 MEDDU2 "Distance unit to median divider 2";
CM_ SG_ 418 MEDDU3 "Distance unit to median divider 3";
CM_ SG_ 418 MEDDU4 "Distance unit to median divider 4";
CM_ SG_ 418 MEDDU5 "Distance unit to median divider 5";
CM_ SG_ 418 MEDDIST1 "Distance to median divider 1";
CM_ SG_ 418 MEDDIST2 "Distance to median divider 2";
CM_ SG_ 418 MEDDIST3 "Distance to median divider 3";
CM_ SG_ 418 MEDDIST4 "Distance to median divider 4";
CM_ SG_ 418 MEDDIST5 "Distance to median divider 5";
CM_ SG_ 418 MPMEDFLG "Map Matching position median divider Flag";
CM_ SG_ 418 MPLNNUM "Map Matching position lane number";
CM_ SG_ 418 LNNUMDU1 "Distance unit to lane number 1";
CM_ SG_ 418 LNNUMDU2 "Distance unit to lane number 2";
CM_ SG_ 418 LNNUMDU3 "Distance unit to lane number 3";
CM_ SG_ 418 LNNUM1 "Lane number 1";
CM_ SG_ 418 LNNUM2 "Lane number 2";
CM_ SG_ 418 LNNUM3 "Lane number 3";
CM_ SG_ 418 LNNUMD1 "Distance to lane number 1";
CM_ SG_ 418 LNNUMD2 "Distance to lane number 2";
CM_ SG_ 418 LNNUMD3 "Distance to lane number 3";
CM_ SG_ 418 DFLGDU1 "Distance unit to drive way flag 1";
CM_ SG_ 418 DFLGD1 "Distance to drive way flag 1";
CM_ SG_ 418 DFLGD2 "Distance to drive way flag 2";
CM_ SG_ 418 MPOSDFLG "Map Matching position drive way flag";
CM_ SG_ 418 DWAYFLG1 "drive way flag 1";
CM_ SG_ 418 DWAYFLG2 "drive way flag 2";
CM_ SG_ 418 DFLGDU2 "Distance unit to drive way flag 2";
CM_ SG_ 418 TOLDU1 "Distance unit to tollgate 1";
CM_ SG_ 418 TOLDIST1 "Distance to tollgate 1";
CM_ SG_ 418 TOLSTY1 "Toll Structure Type 1";
CM_ SG_ 418 RLDXUNT1 "Distance unit to railroad crossing 1";
CM_ SG_ 418 RLDXUNT2 "Distance unit to railroad crossing 2";
CM_ SG_ 418 RLDXDST1 "Distance to railroad crossing 1";
CM_ SG_ 418 RLDXDST2 "Distance to railroad crossing 2";
CM_ BO_ 440 "Reserve";
CM_ SG_ 440 FRMSID3 "Frame sync ID3";
CM_ SG_ 440 LNKTYP1 "Link type 1";
CM_ SG_ 440 LNKTYP2 "Link type 2";
CM_ SG_ 440 LNKTYP3 "Link type 3";
CM_ SG_ 440 LNKTYP4 "Link type 4";
CM_ SG_ 440 LNKTYP5 "Link type 5";
CM_ SG_ 440 LNKTYP6 "Link type 6";
CM_ SG_ 440 LNKTYP7 "Link type 7";
CM_ SG_ 440 LNKTYP8 "Link type 8";
CM_ SG_ 440 LNKTYP9 "Link type 9";
CM_ SG_ 440 LNKTYP10 "Link type 10";
CM_ SG_ 440 LNKDU1 "Distance unit to link type 1";
CM_ SG_ 440 LNKDU2 "Distance unit to link type 2";
CM_ SG_ 440 LNKDU3 "Distance unit to link type 3";
CM_ SG_ 440 LNKDU4 "Distance unit to link type 4";
CM_ SG_ 440 LNKDU5 "Distance unit to link type 5";
CM_ SG_ 440 LNKDU6 "Distance unit to link type 6";
CM_ SG_ 440 LNKDU7 "Distance unit to link type 7";
CM_ SG_ 440 LNKDU8 "Distance unit to link type 8";
CM_ SG_ 440 LNKDU9 "Distance unit to link type 9";
CM_ SG_ 440 LNKDU10 "Distance unit to link type 10";
CM_ SG_ 440 LNKD1 "Distance to link type 1";
CM_ SG_ 440 LNKD2 "Distance to link type 2";
CM_ SG_ 440 LNKD3 "Distance to link type 3";
CM_ SG_ 440 LNKD4 "Distance to link type 4";
CM_ SG_ 440 LNKD5 "Distance to link type 5";
CM_ SG_ 440 LNKD6 "Distance to link type 6";
CM_ SG_ 440 LNKD7 "Distance to link type 7";
CM_ SG_ 440 LNKD8 "Distance to link type 8";
CM_ SG_ 440 LNKD9 "Distance to link type 9";
CM_ SG_ 440 LNKD10 "Distance to link type 10";
CM_ SG_ 440 MPLNKTYP "Map Matching position link type";
CM_ BO_ 441 "Reserve";
CM_ SG_ 441 FRMSID4 "Frame sync ID4";
CM_ SG_ 441 MPSPLU "Map Matching position speed limit unit";
CM_ SG_ 441 FWSPD3 "Forward Speed value 3";
CM_ SG_ 441 FWSPD4 "Forward Speed value 4";
CM_ SG_ 441 FWSPD5 "Forward Speed value 5";
CM_ SG_ 441 FWSPD6 "Forward Speed value 6";
CM_ SG_ 441 FWSPD7 "Forward Speed value 7";
CM_ SG_ 441 FWSPTY3 "Forward Speed type 3";
CM_ SG_ 441 FWSPTY4 "Forward Speed type 4";
CM_ SG_ 441 FWSPTY5 "Forward Speed type 5";
CM_ SG_ 441 FWSPTY6 "Forward Speed type 6";
CM_ SG_ 441 FWSPTY7 "Forward Speed type 7";
CM_ SG_ 441 FWSPAU3 "Forward Additional speed limit information 3";
CM_ SG_ 441 FWSPAU4 "Forward Additional speed limit information 4";
CM_ SG_ 441 FWSPAU5 "Forward Additional speed limit information 5";
CM_ SG_ 441 FWSPAU6 "Forward Additional speed limit information 6";
CM_ SG_ 441 FWSPAU7 "Forward Additional speed limit information 7";
CM_ SG_ 441 FWSPLU1 "Forward speed limit unit 1";
CM_ SG_ 441 FWSPLU2 "Forward speed limit unit 2";
CM_ SG_ 441 FWSPLU3 "Forward speed limit unit 3";
CM_ SG_ 441 FWSPLU4 "Forward speed limit unit 4";
CM_ SG_ 441 FWSPLU5 "Forward speed limit unit 5";
CM_ SG_ 441 FWSPLU6 "Forward speed limit unit 6";
CM_ SG_ 441 FWSPLU7 "Forward speed limit unit 7";
CM_ SG_ 441 SPDISTU3 "Distance unit to Speed 3";
CM_ SG_ 441 SPDISTU4 "Distance unit to Speed 4";
CM_ SG_ 441 SPDISTU5 "Distance unit to Speed 5";
CM_ SG_ 441 SPDISTU6 "Distance unit to Speed 6";
CM_ SG_ 441 SPDISTU7 "Distance unit to Speed 7";
CM_ SG_ 441 SPDIST3 "Distance to Speed 3";
CM_ SG_ 441 SPDIST4 "Distance to Speed 4";
CM_ SG_ 441 SPDIST5 "Distance to Speed 5";
CM_ SG_ 441 SPDIST6 "Distance to Speed 6";
CM_ SG_ 441 SPDIST7 "Distance to Speed 7";
CM_ SG_ 441 MPOWFLG "Map Matching position one-way flag";
CM_ SG_ 441 FWOWFLG1 "Forward one-way flag 1";
CM_ SG_ 441 OWDU1 "Distance unit to one-way 1";
CM_ SG_ 441 OWDIST1 "Distance to one-way 1";
CM_ SG_ 441 MPRDTYP "Map Matching position Road type";
CM_ SG_ 441 FWRDTYP1 "Forward Road type 1";
CM_ SG_ 441 RDTYPDU1 "Distance unit to Road type 1";
CM_ SG_ 441 RDTYPD1 "Distance to Road type 1";
CM_ SG_ 441 FWRDTYP2 "Forward Road type 2";
CM_ SG_ 441 RDTYPDU2 "Distance unit to Road type 2";
CM_ SG_ 441 RDTYPD2 "Distance to Road type 2";
CM_ SG_ 441 MPSP1 "Map Matching position Speed value";
CM_ SG_ 441 MPSPTY1 "Map Matching position Speed type";
CM_ SG_ 441 MPSPAU1 "Map Matching position Additional speed limit information";
CM_ SG_ 441 FWSPD1 "Forward Speed value 1";
CM_ SG_ 441 FWSPTY1 "Forward Speed type 1";
CM_ SG_ 441 FWSPAU1 "Forward Additional speed limit information 1";
CM_ SG_ 441 SPDISTU1 "Distance unit to Speed 1";
CM_ SG_ 441 SPDIST1 "Distance to Speed 1";
CM_ SG_ 441 FWSPD2 "Forward Speed value 2";
CM_ SG_ 441 FWSPTY2 "Forward Speed type 2";
CM_ SG_ 441 FWSPAU2 "Forward Additional speed limit information 2";
CM_ SG_ 441 SPDISTU2 "Distance unit to Speed 2";
CM_ SG_ 441 SPDIST2 "Distance to Speed 2";
CM_ BO_ 439 "Reserve";
CM_ SG_ 439 FRMSID5 "Frame sync ID5";
CM_ SG_ 439 TNENTDU1 "Distance unit to tunnel entrance point 1";
CM_ SG_ 439 TNENTDU2 "Distance unit to tunnel entrance point 2";
CM_ SG_ 439 TNENTDU3 "Distance unit to tunnel entrance point 3";
CM_ SG_ 439 TNENTDU4 "Distance unit to tunnel entrance point 4";
CM_ SG_ 439 TNENTDU5 "Distance unit to tunnel entrance point 5";
CM_ SG_ 439 TNENTD1 "Distance to tunnel entrance point 1";
CM_ SG_ 439 TNENTD2 "Distance to tunnel entrance point 2";
CM_ SG_ 439 TNENTD3 "Distance to tunnel entrance point 3";
CM_ SG_ 439 TNENTD4 "Distance to tunnel entrance point 4";
CM_ SG_ 439 TNENTD5 "Distance to tunnel entrance point 5";
CM_ SG_ 439 TNVFLG1 "Tunnel section length valid flag 1";
CM_ SG_ 439 TNVFLG2 "Tunnel section length valid flag 2";
CM_ SG_ 439 TNVFLG3 "Tunnel section length valid flag 3";
CM_ SG_ 439 TNVFLG4 "Tunnel section length valid flag 4";
CM_ SG_ 439 TNVFLG5 "Tunnel section length valid flag 5";
CM_ SG_ 439 TNLEN1 "Tunnel section length 1";
CM_ SG_ 439 TNLEN2 "Tunnel section length 2";
CM_ SG_ 439 TNLEN3 "Tunnel section length 3";
CM_ SG_ 439 TNLEN4 "Tunnel section length 4";
CM_ SG_ 439 TNLEN5 "Tunnel section length 5";
CM_ SG_ 439 BRGDU1 "Distance unit to bridge entrance point 1";
CM_ SG_ 439 BRGDU2 "Distance unit to bridge entrance point 2";
CM_ SG_ 439 BRGDU3 "Distance unit to bridge entrance point 3";
CM_ SG_ 439 BRGDIST1 "Distance to bridge entrance point 1";
CM_ SG_ 439 BRGDIST2 "Distance to bridge entrance point 2";
CM_ SG_ 439 BRGDIST3 "Distance to bridge entrance point 3";
CM_ SG_ 439 BRGVFLG1 "Bridge section length valid flag 1";
CM_ SG_ 439 BRGVFLG2 "Bridge section length valid flag 2";
CM_ SG_ 439 BRGVFLG3 "Bridge section length valid flag 3";
CM_ SG_ 439 BRGLEN1 "Bridge section length 1";
CM_ SG_ 439 BRGLEN2 "Bridge section length 2";
CM_ SG_ 439 BRGLEN3 "Bridge section length 3";
CM_ BO_ 437 "Reserve";
CM_ SG_ 437 FRMSID6 "Frame sync ID6";
CM_ SG_ 437 MPOSCURV "Map Matching position curvature";
CM_ SG_ 437 CURINFO1 "Curvature information 100m ahead";
CM_ SG_ 437 CURINFO3 "Curvature information 800m ahead";
CM_ SG_ 437 CURINFO4 "Curvature information 1200m ahead";
CM_ SG_ 437 MPCURACR "Map Matching position curvature accuracy";
CM_ SG_ 437 PCURACR1 "Curvature accuracy 100m ahead";
CM_ SG_ 437 PCURACR2 "Curvature accuracy 400m ahead";
CM_ SG_ 437 PCURACR3 "Curvature accuracy 800m ahead";
CM_ SG_ 437 PCURACR4 "Curvature accuracy 1200m ahead";
CM_ SG_ 437 SCURAC1 "Section curvature accuracy 1";
CM_ SG_ 437 SCURAC2 "Section curvature accuracy 2";
CM_ SG_ 437 SCURAC3 "Section curvature accuracy 3";
CM_ SG_ 437 SCURAC4 "Section curvature accuracy 4";
CM_ SG_ 437 SCURAC5 "Section curvature accuracy 5";
CM_ SG_ 437 SCURAC6 "Section curvature accuracy 6";
CM_ SG_ 437 SCURAC7 "Section curvature accuracy 7";
CM_ SG_ 437 SCURAC8 "Section curvature accuracy 8";
CM_ SG_ 437 SCURAC9 "Section curvature accuracy 9";
CM_ SG_ 437 SCURAC10 "Section curvature accuracy 10";
CM_ SG_ 437 SCURAC11 "Section curvature accuracy 11";
CM_ SG_ 437 CURD1 "Curvature distance 1";
CM_ SG_ 437 CURD2 "Curvature distance 2";
CM_ SG_ 437 CURVAL11 "Curvature value 11";
CM_ SG_ 437 CURINF11 "Curvature _ Additional information 11";
CM_ SG_ 437 CURVAL9 "Curvature value 9";
CM_ SG_ 437 CURINF9 "Curvature _ Additional information 9";
CM_ SG_ 437 CURVAL10 "Curvature value 10";
CM_ SG_ 437 CURINF10 "Curvature _ Additional information 10";
CM_ SG_ 437 CURINFO2 "Curvature information 400m ahead";
CM_ SG_ 437 CURVAL1 "Curvature value 1";
CM_ SG_ 437 CURINF1 "Curvature _ Additional information 1";
CM_ SG_ 437 CURVAL2 "Curvature value 2";
CM_ SG_ 437 CURINF2 "Curvature _ Additional information 2";
CM_ SG_ 437 CURVAL3 "Curvature value 3";
CM_ SG_ 437 CURINF3 "Curvature _ Additional information 3";
CM_ SG_ 437 CURVAL4 "Curvature value 4";
CM_ SG_ 437 CURINF4 "Curvature _ Additional information 4";
CM_ SG_ 437 CURVAL5 "Curvature value 5";
CM_ SG_ 437 CURINF5 "Curvature _ Additional information 5";
CM_ SG_ 437 CURVAL6 "Curvature value 6";
CM_ SG_ 437 CURINF6 "Curvature _ Additional information 6";
CM_ SG_ 437 CURVAL7 "Curvature value 7";
CM_ SG_ 437 CURINF7 "Curvature _ Additional information 7";
CM_ SG_ 437 CURVAL8 "Curvature value 8";
CM_ SG_ 437 CURINF8 "Curvature _ Additional information 8";
CM_ BO_ 429 "Reserve";
CM_ SG_ 429 FRMSID7 "Frame sync ID7";
CM_ SG_ 429 CURD3 "Curvature distance 3";
CM_ SG_ 429 CURD4 "Curvature distance 4";
CM_ SG_ 429 CURD5 "Curvature distance 5";
CM_ SG_ 429 CURD6 "Curvature distance 6";
CM_ SG_ 429 CURD7 "Curvature distance 7";
CM_ SG_ 429 CURD8 "Curvature distance 8";
CM_ SG_ 429 CURD9 "Curvature distance 9";
CM_ SG_ 429 CURD10 "Curvature distance 10";
CM_ SG_ 429 CURD11 "Curvature distance 11";
CM_ SG_ 429 MPOSLOPE "Map Matching position slope";
CM_ SG_ 429 SLPINF1 "Slope information 100m ahead";
CM_ SG_ 429 SLPINF2 "Slope information 400m ahead";
CM_ SG_ 429 SLPINF3 "Slope information 800m ahead";
CM_ SG_ 429 SLPINF4 "Slope information 1200m ahead";
CM_ SG_ 429 SLPINF5 "Slope information 2000m ahead";
CM_ SG_ 429 MPSLPAC "Map Matching position slope accuracy";
CM_ SG_ 429 PSLPAC1 "Slope accuracy 100m ahead";
CM_ SG_ 429 PSLPAC2 "Slope accuracy 400m ahead";
CM_ SG_ 429 PSLPAC3 "Slope accuracy 800m ahead";
CM_ SG_ 429 PSLPAC4 "Slope accuracy 1200m ahead";
CM_ SG_ 429 PSLPAC5 "Slope accuracy 2000m ahead";
CM_ SG_ 429 AVESLP1 "Average slope value 1";
CM_ SG_ 429 AVESLP2 "Average slope value 2";
CM_ SG_ 429 AVESLP3 "Average slope value 3";
CM_ SG_ 429 AVESLP4 "Average slope value 4";
CM_ SG_ 429 AVESLP5 "Average slope value 5";
CM_ SG_ 429 AVESLP6 "Average slope value 6";
CM_ SG_ 429 AVESLP7 "Average slope value 7";
CM_ SG_ 429 AVESLP8 "Average slope value 8";
CM_ SG_ 429 AVSLPAC1 "Average slope accuracy 1";
CM_ SG_ 429 AVSLPAC2 "Average slope accuracy 2";
CM_ SG_ 429 AVSLPAC3 "Average slope accuracy 3";
CM_ SG_ 429 AVSLPAC4 "Average slope accuracy 4";
CM_ SG_ 429 AVSLPAC5 "Average slope accuracy 5";
CM_ SG_ 429 AVSLPAC6 "Average slope accuracy 6";
CM_ SG_ 429 AVSLPAC7 "Average slope accuracy 7";
CM_ SG_ 429 AVSLPAC8 "Average slope accuracy 8";
CM_ BO_ 431 "Reserve";
CM_ SG_ 431 FRMSID8 "Frame sync ID8";
CM_ SG_ 431 INTID4 "Entry Link Intersection ID 4";
CM_ SG_ 431 INTID5 "Entry Link Intersection ID 5";
CM_ SG_ 431 INTID6 "Entry Link Intersection ID 6";
CM_ SG_ 431 INTID7 "Entry Link Intersection ID 7";
CM_ SG_ 431 INTID8 "Entry Link Intersection ID 8";
CM_ SG_ 431 INTID9 "Entry Link Intersection ID 9";
CM_ SG_ 431 INTID10 "Entry Link Intersection ID 10";
CM_ SG_ 431 INTID11 "Entry Link Intersection ID 11";
CM_ SG_ 431 INTID12 "Entry Link Intersection ID 12";
CM_ SG_ 431 INTDU1 "Distance unit to Intersection 1";
CM_ SG_ 431 INTDU2 "Distance unit to Intersection 2";
CM_ SG_ 431 INTDU3 "Distance unit to Intersection 3";
CM_ SG_ 431 INTDU4 "Distance unit to Intersection 4";
CM_ SG_ 431 INTDU5 "Distance unit to Intersection 5";
CM_ SG_ 431 INTDU6 "Distance unit to Intersection 6";
CM_ SG_ 431 INTDU7 "Distance unit to Intersection 7";
CM_ SG_ 431 INTDU8 "Distance unit to Intersection 8";
CM_ SG_ 431 INTDU9 "Distance unit to Intersection 9";
CM_ SG_ 431 INTDU10 "Distance unit to Intersection 10";
CM_ SG_ 431 INTDU11 "Distance unit to Intersection 11";
CM_ SG_ 431 INTDU12 "Distance unit to Intersection 12";
CM_ SG_ 431 INTDIS4 "Distance to Intersection 4";
CM_ SG_ 431 INTDIS5 "Distance to Intersection 5";
CM_ SG_ 431 INTDIS6 "Distance to Intersection 6";
CM_ SG_ 431 INTDIS7 "Distance to Intersection 7";
CM_ SG_ 431 INTDIS8 "Distance to Intersection 8";
CM_ SG_ 431 INTDIS9 "Distance to Intersection 9";
CM_ SG_ 431 INTDIS10 "Distance to Intersection 10";
CM_ SG_ 431 INTDIS11 "Distance to Intersection 11";
CM_ SG_ 431 INTDIS12 "Distance to Intersection 12";
CM_ SG_ 431 INTNLN4 "Number of intersecting other links 4";
CM_ SG_ 431 INTNLN5 "Number of intersecting other links 5";
CM_ SG_ 431 INTNLN6 "Number of intersecting other links 6";
CM_ SG_ 431 INTNLN7 "Number of intersecting other links 7";
CM_ SG_ 431 INTNLN8 "Number of intersecting other links 8";
CM_ SG_ 431 INTNLN9 "Number of intersecting other links 9";
CM_ SG_ 431 INTNLN10 "Number of intersecting other links 10";
CM_ SG_ 431 INTNLN11 "Number of intersecting other links 11";
CM_ SG_ 431 INTNLN12 "Number of intersecting other links 12";
CM_ SG_ 431 INTDIS3 "Distance to Intersection 3";
CM_ SG_ 431 INTNLN3 "Number of intersecting other links 3";
CM_ SG_ 431 INTID3 "Entry Link Intersection ID 3";
CM_ SG_ 431 INTDIS1 "Distance to Intersection 1";
CM_ SG_ 431 INTDIS2 "Distance to Intersection 2";
CM_ SG_ 431 INTNLN1 "Number of intersecting other links 1";
CM_ SG_ 431 INTNLN2 "Number of intersecting other links 2";
CM_ SG_ 431 INTID1 "Entry Link Intersection ID 1";
CM_ SG_ 431 INTID2 "Entry Link Intersection ID 2";
CM_ BO_ 432 "Reserve";
CM_ SG_ 432 FRMSID9 "Frame sync ID9";
CM_ SG_ 432 ENRDTY4 "Entry link Road type 4";
CM_ SG_ 432 ENRDTY5 "Entry link Road type 5";
CM_ SG_ 432 ENRDTY6 "Entry link Road type 6";
CM_ SG_ 432 ENRDTY7 "Entry link Road type 7";
CM_ SG_ 432 ENRDTY8 "Entry link Road type 8";
CM_ SG_ 432 ENRDTY9 "Entry link Road type 9";
CM_ SG_ 432 ENRDTY10 "Entry link Road type 10";
CM_ SG_ 432 ENRDTY11 "Entry link Road type 11";
CM_ SG_ 432 ENRDTY12 "Entry link Road type 12";
CM_ SG_ 432 ENLNTY4 "Entry link Link type of 4";
CM_ SG_ 432 ENLNTY5 "Entry link Link type of 5";
CM_ SG_ 432 ENLNTY6 "Entry link Link type of 6";
CM_ SG_ 432 ENLNTY7 "Entry link Link type of 7";
CM_ SG_ 432 ENLNTY8 "Entry link Link type of 8";
CM_ SG_ 432 ENLNTY9 "Entry link Link type of 9";
CM_ SG_ 432 ENLNTY10 "Entry link Link type of 10";
CM_ SG_ 432 ENLNTY11 "Entry link Link type of 11";
CM_ SG_ 432 ENLNTY12 "Entry link Link type of 12";
CM_ SG_ 432 ENNMLN1 "Entry link Number of lanes 1";
CM_ SG_ 432 ENNMLN2 "Entry link Number of lanes 2";
CM_ SG_ 432 ENNMLN3 "Entry link Number of lanes 3";
CM_ SG_ 432 ENNMLN4 "Entry link Number of lanes 4";
CM_ SG_ 432 ENNMLN5 "Entry link Number of lanes 5";
CM_ SG_ 432 ENNMLN6 "Entry link Number of lanes 6";
CM_ SG_ 432 ENNMLN7 "Entry link Number of lanes 7";
CM_ SG_ 432 ENNMLN8 "Entry link Number of lanes 8";
CM_ SG_ 432 ENNMLN9 "Entry link Number of lanes 9";
CM_ SG_ 432 ENNMLN10 "Entry link Number of lanes 10";
CM_ SG_ 432 ENNMLN11 "Entry link Number of lanes 11";
CM_ SG_ 432 ENNMLN12 "Entry link Number of lanes 12";
CM_ SG_ 432 ENLNTY3 "Entry link Link type of 3";
CM_ SG_ 432 ENRDTY3 "Entry link Road type 3";
CM_ SG_ 432 ENRDTY1 "Entry link Road type 1";
CM_ SG_ 432 ENRDTY2 "Entry link Road type 2";
CM_ SG_ 432 ENLNTY1 "Entry link Link type of 1";
CM_ SG_ 432 ENLNTY2 "Entry link Link type of 2";
CM_ BO_ 435 "Reserve";
CM_ SG_ 435 FRMSID10 "Frame sync ID10";
CM_ SG_ 435 ENSIG4 "Entry link Signal 4";
CM_ SG_ 435 ENSIG5 "Entry link Signal 5";
CM_ SG_ 435 ENSIG6 "Entry link Signal 6";
CM_ SG_ 435 ENSIG7 "Entry link Signal 7";
CM_ SG_ 435 ENSIG8 "Entry link Signal 8";
CM_ SG_ 435 ENSIG9 "Entry link Signal 9";
CM_ SG_ 435 ENSIG10 "Entry link Signal 10";
CM_ SG_ 435 ENSIG11 "Entry link Signal 11";
CM_ SG_ 435 ENSIG12 "Entry link Signal 12";
CM_ SG_ 435 ENSIBD4 "Entry link Signboard info 4";
CM_ SG_ 435 ENSIBD5 "Entry link Signboard info 5";
CM_ SG_ 435 ENSIBD6 "Entry link Signboard info 6";
CM_ SG_ 435 ENSIBD7 "Entry link Signboard info 7";
CM_ SG_ 435 ENSIBD8 "Entry link Signboard info 8";
CM_ SG_ 435 ENSIBD9 "Entry link Signboard info 9";
CM_ SG_ 435 ENSIBD10 "Entry link Signboard info 10";
CM_ SG_ 435 ENSIBD11 "Entry link Signboard info 11";
CM_ SG_ 435 ENSIBD12 "Entry link Signboard info 12";
CM_ SG_ 435 ALRDTY4 "Exit link Road type 4";
CM_ SG_ 435 ALRDTY5 "Exit link Road type 5";
CM_ SG_ 435 ALRDTY6 "Exit link Road type 6";
CM_ SG_ 435 ALRDTY7 "Exit link Road type 7";
CM_ SG_ 435 ALRDTY8 "Exit link Road type 8";
CM_ SG_ 435 ALRDTY9 "Exit link Road type 9";
CM_ SG_ 435 ALRDTY10 "Exit link Road type 10";
CM_ SG_ 435 ALRDTY11 "Exit link Road type 11";
CM_ SG_ 435 ALRDTY12 "Exit link Road type 12";
CM_ SG_ 435 ALTYP4 "Exit link Link type of 4";
CM_ SG_ 435 ALTYP5 "Exit link Link type of 5";
CM_ SG_ 435 ALTYP6 "Exit link Link type of 6";
CM_ SG_ 435 ALTYP7 "Exit link Link type of 7";
CM_ SG_ 435 ALTYP8 "Exit link Link type of 8";
CM_ SG_ 435 ALTYP9 "Exit link Link type of 9";
CM_ SG_ 435 ALTYP10 "Exit link Link type of 10";
CM_ SG_ 435 ENPRI1 "Entry link Priority road / Non-priority road information1";
CM_ SG_ 435 ENPRI2 "Entry link Priority road / Non-priority road information2";
CM_ SG_ 435 ENPRI3 "Entry link Priority road / Non-priority road information3";
CM_ SG_ 435 ENPRI4 "Entry link Priority road / Non-priority road information4";
CM_ SG_ 435 ENPRI5 "Entry link Priority road / Non-priority road information5";
CM_ SG_ 435 ENPRI6 "Entry link Priority road / Non-priority road information6";
CM_ SG_ 435 ENPRI7 "Entry link Priority road / Non-priority road information7";
CM_ SG_ 435 ENPRI8 "Entry link Priority road / Non-priority road information8";
CM_ SG_ 435 ENPRI9 "Entry link Priority road / Non-priority road information9";
CM_ SG_ 435 ENPRI10 "Entry link Priority road / Non-priority road information10";
CM_ SG_ 435 ENPRI11 "Entry link Priority road / Non-priority road information11";
CM_ SG_ 435 ENPRI12 "Entry link Priority road / Non-priority road information12";
CM_ SG_ 435 ENSIG3 "Entry link Signal 3";
CM_ SG_ 435 ENSIBD3 "Entry link Signboard info 3";
CM_ SG_ 435 ENSIG1 "Entry link Signal 1";
CM_ SG_ 435 ENSIG2 "Entry link Signal 2";
CM_ SG_ 435 ALTYP1 "Exit link Link type of 1";
CM_ SG_ 435 ALRDTY1 "Exit link Road type 1";
CM_ SG_ 435 ALTYP2 "Exit link Link type of 2";
CM_ SG_ 435 ALRDTY2 "Exit link Road type 2";
CM_ SG_ 435 ENSIBD1 "Entry link Signboard info 1";
CM_ SG_ 435 ENSIBD2 "Entry link Signboard info 2";
CM_ SG_ 435 ALRDTY3 "Exit link Road type 3";
CM_ SG_ 435 ALTYP3 "Exit link Link type of 3";
CM_ BO_ 436 "Reserve";
CM_ SG_ 436 FRMSID11 "Frame sync ID11";
CM_ SG_ 436 ALTYP11 "Exit link Link type of 11";
CM_ SG_ 436 ALTYP12 "Exit link Link type of 12";
CM_ SG_ 436 ALNLN4 "Exit link Number of lanes 4";
CM_ SG_ 436 ALNLN5 "Exit link Number of lanes 5";
CM_ SG_ 436 ALNLN6 "Exit link Number of lanes 6";
CM_ SG_ 436 ALNLN7 "Exit link Number of lanes 7";
CM_ SG_ 436 ALNLN8 "Exit link Number of lanes 8";
CM_ SG_ 436 ALNLN9 "Exit link Number of lanes 9";
CM_ SG_ 436 ALNLN10 "Exit link Number of lanes 10";
CM_ SG_ 436 ALNLN11 "Exit link Number of lanes 11";
CM_ SG_ 436 ALNLN12 "Exit link Number of lanes 12";
CM_ SG_ 436 ALNSIG1 "Exit link Signal 1";
CM_ SG_ 436 ALNSIG2 "Exit link Signal 2";
CM_ SG_ 436 ALNSIG3 "Exit link Signal 3";
CM_ SG_ 436 ALNSIG4 "Exit link Signal 4";
CM_ SG_ 436 ALNSIG5 "Exit link Signal 5";
CM_ SG_ 436 ALNSIG6 "Exit link Signal 6";
CM_ SG_ 436 ALNSIG7 "Exit link Signal 7";
CM_ SG_ 436 ALNSIG8 "Exit link Signal 8";
CM_ SG_ 436 ALNSIG9 "Exit link Signal 9";
CM_ SG_ 436 ALNSIG10 "Exit link Signal 10";
CM_ SG_ 436 ALNSIG11 "Exit link Signal 11";
CM_ SG_ 436 ALNSIG12 "Exit link Signal 12";
CM_ SG_ 436 ALNSBD1 "Ext linlk Signboard info 1";
CM_ SG_ 436 ALNSBD2 "Ext linlk Signboard info 2";
CM_ SG_ 436 ALNSBD3 "Ext linlk Signboard info 3";
CM_ SG_ 436 ALNSBD4 "Ext linlk Signboard info 4";
CM_ SG_ 436 ALNSBD5 "Ext linlk Signboard info 5";
CM_ SG_ 436 ALNSBD6 "Ext linlk Signboard info 6";
CM_ SG_ 436 ALNSBD7 "Ext linlk Signboard info 7";
CM_ SG_ 436 ALNSBD8 "Ext linlk Signboard info 8";
CM_ SG_ 436 ALNSBD9 "Ext linlk Signboard info 9";
CM_ SG_ 436 ALNSBD10 "Ext linlk Signboard info 10";
CM_ SG_ 436 ALNSBD11 "Ext linlk Signboard info 11";
CM_ SG_ 436 ALNSBD12 "Ext linlk Signboard info 12";
CM_ SG_ 436 ALNOW1 "Exit link One way info1";
CM_ SG_ 436 ALNOW2 "Exit link One way info2";
CM_ SG_ 436 ALNOW3 "Exit link One way info3";
CM_ SG_ 436 ALNOW4 "Exit link One way info4";
CM_ SG_ 436 ALNOW5 "Exit link One way info5";
CM_ SG_ 436 ALNOW6 "Exit link One way info6";
CM_ SG_ 436 ALNOW7 "Exit link One way info7";
CM_ SG_ 436 ALNOW8 "Exit link One way info8";
CM_ SG_ 436 ALNOW9 "Exit link One way info9";
CM_ SG_ 436 ALNOW10 "Exit link One way info10";
CM_ SG_ 436 ALNOW11 "Exit link One way info11";
CM_ SG_ 436 ALNOW12 "Exit link One way info12";
CM_ SG_ 436 ALNEN1 "Exit link No entry info 1";
CM_ SG_ 436 ALNEN2 "Exit link No entry info 2";
CM_ SG_ 436 ALNEN3 "Exit link No entry info 3";
CM_ SG_ 436 ALNEN4 "Exit link No entry info 4";
CM_ SG_ 436 ALNEN5 "Exit link No entry info 5";
CM_ SG_ 436 ALNEN6 "Exit link No entry info 6";
CM_ SG_ 436 ALNEN7 "Exit link No entry info 7";
CM_ SG_ 436 ALNEN8 "Exit link No entry info 8";
CM_ SG_ 436 ALNEN9 "Exit link No entry info 9";
CM_ SG_ 436 ALNEN10 "Exit link No entry info 10";
CM_ SG_ 436 ALNEN11 "Exit link No entry info 11";
CM_ SG_ 436 ALNEN12 "Exit link No entry info 12";
CM_ SG_ 436 ALANG4 "Exit link angle 4";
CM_ SG_ 436 ALANG5 "Exit link angle 5";
CM_ SG_ 436 ALANG6 "Exit link angle 6";
CM_ SG_ 436 ALANG7 "Exit link angle 7";
CM_ SG_ 436 ALANG8 "Exit link angle 8";
CM_ SG_ 436 ALANG9 "Exit link angle 9";
CM_ SG_ 436 ALANG10 "Exit link angle 10";
CM_ SG_ 436 ALANG11 "Exit link angle 11";
CM_ SG_ 436 ALANG12 "Exit link angle 12";
CM_ SG_ 436 ALANG1 "Exit link angle 1";
CM_ SG_ 436 ALANG2 "Exit link angle 2";
CM_ SG_ 436 ALNLN1 "Exit link Number of lanes 1";
CM_ SG_ 436 ALNLN2 "Exit link Number of lanes 2";
CM_ SG_ 436 ALNLN3 "Exit link Number of lanes 3";
CM_ SG_ 436 ALANG3 "Exit link angle 3";
CM_ BO_ 430 "Reserve";
CM_ SG_ 430 FRMSID12 "Frame sync ID12";
CM_ SG_ 430 ALCINF1 "Exit link connection information 1";
CM_ SG_ 430 ALCINF2 "Exit link connection information 2";
CM_ SG_ 430 ALCINF3 "Exit link connection information 3";
CM_ SG_ 430 ALCINF4 "Exit link connection information 4";
CM_ SG_ 430 ALCINF5 "Exit link connection information 5";
CM_ SG_ 430 ALCINF6 "Exit link connection information 6";
CM_ SG_ 430 ALCINF7 "Exit link connection information 7";
CM_ SG_ 430 ALCINF8 "Exit link connection information 8";
CM_ SG_ 430 ALCINF9 "Exit link connection information 9";
CM_ SG_ 430 ALCINF10 "Exit link connection information 10";
CM_ SG_ 430 ALCINF11 "Exit link connection information 11";
CM_ SG_ 430 ALCINF12 "Exit link connection information 12";
CM_ SG_ 430 NALINT7 "Other link Intersection index number 7";
CM_ SG_ 430 NALINT8 "Other link Intersection index number 8";
CM_ SG_ 430 NALINT9 "Other link Intersection index number 9";
CM_ SG_ 430 NALINT10 "Other link Intersection index number 10";
CM_ SG_ 430 NALINT11 "Other link Intersection index number 11";
CM_ SG_ 430 NALINT12 "Other link Intersection index number 12";
CM_ SG_ 430 NALINT13 "Other link Intersection index number 13";
CM_ SG_ 430 NALINT14 "Other link Intersection index number 14";
CM_ SG_ 430 NALINT15 "Other link Intersection index number 15";
CM_ SG_ 430 NALINT16 "Other link Intersection index number 16";
CM_ SG_ 430 NALINT17 "Other link Intersection index number 17";
CM_ SG_ 430 NALINT18 "Other link Intersection index number 18";
CM_ SG_ 430 NALINT19 "Other link Intersection index number 19";
CM_ SG_ 430 NALINT20 "Other link Intersection index number 20";
CM_ SG_ 430 NALINT21 "Other link Intersection index number 21";
CM_ SG_ 430 NALINT22 "Other link Intersection index number 22";
CM_ SG_ 430 NALINT23 "Other link Intersection index number 23";
CM_ SG_ 430 NALINT24 "Other link Intersection index number 24";
CM_ SG_ 430 NALRDT1 "Other link Road type 1";
CM_ SG_ 430 NALRDT2 "Other link Road type 2";
CM_ SG_ 430 NALRDT3 "Other link Road type 3";
CM_ SG_ 430 NALRDT4 "Other link Road type 4";
CM_ SG_ 430 NALRDT5 "Other link Road type 5";
CM_ SG_ 430 NALRDT6 "Other link Road type 6";
CM_ SG_ 430 NALRDT7 "Other link Road type 7";
CM_ SG_ 430 NALRDT8 "Other link Road type 8";
CM_ SG_ 430 NALRDT9 "Other link Road type 9";
CM_ SG_ 430 NALRDT10 "Other link Road type 10";
CM_ SG_ 430 NALRDT11 "Other link Road type 11";
CM_ SG_ 430 ALPRI1 "Exit link Priority road / Non-priority road information1";
CM_ SG_ 430 ALPRI2 "Exit link Priority road / Non-priority road information1";
CM_ SG_ 430 ALPRI3 "Exit link Priority road / Non-priority road information1";
CM_ SG_ 430 ALPRI4 "Exit link Priority road / Non-priority road information1";
CM_ SG_ 430 ALPRI5 "Exit link Priority road / Non-priority road information1";
CM_ SG_ 430 ALPRI6 "Exit link Priority road / Non-priority road information1";
CM_ SG_ 430 ALPRI7 "Exit link Priority road / Non-priority road information1";
CM_ SG_ 430 ALPRI8 "Exit link Priority road / Non-priority road information1";
CM_ SG_ 430 ALPRI9 "Exit link Priority road / Non-priority road information1";
CM_ SG_ 430 ALPRI10 "Exit link Priority road / Non-priority road information1";
CM_ SG_ 430 ALPRI11 "Exit link Priority road / Non-priority road information1";
CM_ SG_ 430 ALPRI12 "Exit link Priority road / Non-priority road information1";
CM_ SG_ 430 ALALF1 "Exit link Entry allowed flag by turn signal 1";
CM_ SG_ 430 ALALF2 "Exit link Entry allowed flag by turn signal 2";
CM_ SG_ 430 ALALF3 "Exit link Entry allowed flag by turn signal 3";
CM_ SG_ 430 ALALF4 "Exit link Entry allowed flag by turn signal 4";
CM_ SG_ 430 ALALF5 "Exit link Entry allowed flag by turn signal 5";
CM_ SG_ 430 ALALF6 "Exit link Entry allowed flag by turn signal 6";
CM_ SG_ 430 ALALF7 "Exit link Entry allowed flag by turn signal 7";
CM_ SG_ 430 ALALF8 "Exit link Entry allowed flag by turn signal 8";
CM_ SG_ 430 ALALF9 "Exit link Entry allowed flag by turn signal 9";
CM_ SG_ 430 ALALF10 "Exit link Entry allowed flag by turn signal 10";
CM_ SG_ 430 ALALF11 "Exit link Entry allowed flag by turn signal 11";
CM_ SG_ 430 ALALF12 "Exit link Entry allowed flag by turn signal 12";
CM_ SG_ 430 NALINT1 "Other link Intersection index number 1";
CM_ SG_ 430 NALINT2 "Other link Intersection index number 2";
CM_ SG_ 430 NALINT3 "Other link Intersection index number 3";
CM_ SG_ 430 NALINT4 "Other link Intersection index number 4";
CM_ SG_ 430 NALINT5 "Other link Intersection index number 5";
CM_ SG_ 430 NALINT6 "Other link Intersection index number 6";
CM_ BO_ 424 "Reserve";
CM_ SG_ 424 FRMSID13 "Frame sync ID13";
CM_ SG_ 424 NALRDT12 "Other link Road type 12";
CM_ SG_ 424 NALRDT13 "Other link Road type 13";
CM_ SG_ 424 NALRDT14 "Other link Road type 14";
CM_ SG_ 424 NALRDT15 "Other link Road type 15";
CM_ SG_ 424 NALRDT16 "Other link Road type 16";
CM_ SG_ 424 NALRDT17 "Other link Road type 17";
CM_ SG_ 424 NALRDT18 "Other link Road type 18";
CM_ SG_ 424 NALRDT19 "Other link Road type 19";
CM_ SG_ 424 NALRDT20 "Other link Road type 20";
CM_ SG_ 424 NALRDT21 "Other link Road type 21";
CM_ SG_ 424 NALRDT22 "Other link Road type 22";
CM_ SG_ 424 NALRDT23 "Other link Road type 23";
CM_ SG_ 424 NALRDT24 "Other link Road type 24";
CM_ SG_ 424 NALTYP7 "Other link Link type of 7";
CM_ SG_ 424 NALTYP8 "Other link Link type of 8";
CM_ SG_ 424 NALTYP9 "Other link Link type of 9";
CM_ SG_ 424 NALTYP10 "Other link Link type of 10";
CM_ SG_ 424 NALTYP11 "Other link Link type of 11";
CM_ SG_ 424 NALTYP12 "Other link Link type of 12";
CM_ SG_ 424 NALTYP13 "Other link Link type of 13";
CM_ SG_ 424 NALTYP14 "Other link Link type of 14";
CM_ SG_ 424 NALTYP15 "Other link Link type of 15";
CM_ SG_ 424 NALTYP16 "Other link Link type of 16";
CM_ SG_ 424 NALTYP17 "Other link Link type of 17";
CM_ SG_ 424 NALTYP18 "Other link Link type of 18";
CM_ SG_ 424 NALTYP1 "Other link Link type of 1";
CM_ SG_ 424 NALTYP2 "Other link Link type of 2";
CM_ SG_ 424 NALTYP3 "Other link Link type of 3";
CM_ SG_ 424 NALTYP4 "Other link Link type of 4";
CM_ SG_ 424 NALTYP5 "Other link Link type of 5";
CM_ SG_ 424 NALTYP6 "Other link Link type of 6";
CM_ BO_ 425 "Reserve";
CM_ SG_ 425 FRMSID14 "Frame sync ID14";
CM_ SG_ 425 NALTYP19 "Other link Link type of 19";
CM_ SG_ 425 NALTYP20 "Other link Link type of 20";
CM_ SG_ 425 NALTYP21 "Other link Link type of 21";
CM_ SG_ 425 NALTYP22 "Other link Link type of 22";
CM_ SG_ 425 NALTYP23 "Other link Link type of 23";
CM_ SG_ 425 NALTYP24 "Other link Link type of 24";
CM_ SG_ 425 NALNLN7 "Other link Number of lanes 7";
CM_ SG_ 425 NALNLN8 "Other link Number of lanes 8";
CM_ SG_ 425 NALNLN9 "Other link Number of lanes 9";
CM_ SG_ 425 NALNLN10 "Other link Number of lanes 10";
CM_ SG_ 425 NALNLN11 "Other link Number of lanes 11";
CM_ SG_ 425 NALNLN12 "Other link Number of lanes 12";
CM_ SG_ 425 NALNLN13 "Other link Number of lanes 13";
CM_ SG_ 425 NALNLN14 "Other link Number of lanes 14";
CM_ SG_ 425 NALNLN15 "Other link Number of lanes 15";
CM_ SG_ 425 NALNLN16 "Other link Number of lanes 16";
CM_ SG_ 425 NALNLN17 "Other link Number of lanes 17";
CM_ SG_ 425 NALNLN18 "Other link Number of lanes 18";
CM_ SG_ 425 NALNLN19 "Other link Number of lanes 19";
CM_ SG_ 425 NALNLN20 "Other link Number of lanes 20";
CM_ SG_ 425 NALNLN21 "Other link Number of lanes 21";
CM_ SG_ 425 NALNLN22 "Other link Number of lanes 22";
CM_ SG_ 425 NALNLN23 "Other link Number of lanes 23";
CM_ SG_ 425 NALNLN24 "Other link Number of lanes 24";
CM_ SG_ 425 NALSIG1 "Other link Signal 1";
CM_ SG_ 425 NALSIG2 "Other link Signal 2";
CM_ SG_ 425 NALSIG3 "Other link Signal 3";
CM_ SG_ 425 NALSIG4 "Other link Signal 4";
CM_ SG_ 425 NALSIG5 "Other link Signal 5";
CM_ SG_ 425 NALSIG6 "Other link Signal 6";
CM_ SG_ 425 NALSIG7 "Other link Signal 7";
CM_ SG_ 425 NALSIG8 "Other link Signal 8";
CM_ SG_ 425 NALSIG9 "Other link Signal 9";
CM_ SG_ 425 NALSIG10 "Other link Signal 10";
CM_ SG_ 425 NALSIG11 "Other link Signal 11";
CM_ SG_ 425 NALSIG12 "Other link Signal 12";
CM_ SG_ 425 NALSIG13 "Other link Signal 13";
CM_ SG_ 425 NALSIG14 "Other link Signal 14";
CM_ SG_ 425 NALSIG15 "Other link Signal 15";
CM_ SG_ 425 NALSIG16 "Other link Signal 16";
CM_ SG_ 425 NALSIG17 "Other link Signal 17";
CM_ SG_ 425 NALSIG18 "Other link Signal 18";
CM_ SG_ 425 NALSIG19 "Other link Signal 19";
CM_ SG_ 425 NALSIG20 "Other link Signal 20";
CM_ SG_ 425 NALSIG21 "Other link Signal 21";
CM_ SG_ 425 NALSIG22 "Other link Signal 22";
CM_ SG_ 425 NALSIG23 "Other link Signal 23";
CM_ SG_ 425 NALSIG24 "Other link Signal 24";
CM_ SG_ 425 NALSBD1 "Other link Signboard info 1";
CM_ SG_ 425 NALSBD2 "Other link Signboard info 2";
CM_ SG_ 425 NALSBD3 "Other link Signboard info 3";
CM_ SG_ 425 NALSBD4 "Other link Signboard info 4";
CM_ SG_ 425 NALSBD5 "Other link Signboard info 5";
CM_ SG_ 425 NALSBD6 "Other link Signboard info 6";
CM_ SG_ 425 NALSBD7 "Other link Signboard info 7";
CM_ SG_ 425 NALSBD8 "Other link Signboard info 8";
CM_ SG_ 425 NALSBD9 "Other link Signboard info 9";
CM_ SG_ 425 NALSBD10 "Other link Signboard info 10";
CM_ SG_ 425 NALSBD11 "Other link Signboard info 11";
CM_ SG_ 425 NALSBD12 "Other link Signboard info 12";
CM_ SG_ 425 NALSBD13 "Other link Signboard info 13";
CM_ SG_ 425 NALSBD14 "Other link Signboard info 14";
CM_ SG_ 425 NALSBD15 "Other link Signboard info 15";
CM_ SG_ 425 NALNLN1 "Other link Number of lanes 1";
CM_ SG_ 425 NALNLN2 "Other link Number of lanes 2";
CM_ SG_ 425 NALNLN3 "Other link Number of lanes 3";
CM_ SG_ 425 NALNLN4 "Other link Number of lanes 4";
CM_ SG_ 425 NALNLN5 "Other link Number of lanes 5";
CM_ SG_ 425 NALNLN6 "Other link Number of lanes 6";
CM_ BO_ 427 "Reserve";
CM_ SG_ 427 FRMSID15 "Frame sync ID15";
CM_ SG_ 427 NALSBD16 "Other link Signboard info 16";
CM_ SG_ 427 NALSBD17 "Other link Signboard info 17";
CM_ SG_ 427 NALSBD18 "Other link Signboard info 18";
CM_ SG_ 427 NALSBD19 "Other link Signboard info 19";
CM_ SG_ 427 NALSBD20 "Other link Signboard info 20";
CM_ SG_ 427 NALSBD21 "Other link Signboard info 21";
CM_ SG_ 427 NALSBD22 "Other link Signboard info 22";
CM_ SG_ 427 NALSBD23 "Other link Signboard info 23";
CM_ SG_ 427 NALSBD24 "Other link Signboard info 24";
CM_ SG_ 427 NALOW1 "Other link One way info1";
CM_ SG_ 427 NALOW2 "Other link One way info2";
CM_ SG_ 427 NALOW3 "Other link One way info3";
CM_ SG_ 427 NALOW4 "Other link One way info4";
CM_ SG_ 427 NALOW5 "Other link One way info5";
CM_ SG_ 427 NALOW6 "Other link One way info6";
CM_ SG_ 427 NALOW7 "Other link One way info7";
CM_ SG_ 427 NALOW8 "Other link One way info8";
CM_ SG_ 427 NALOW9 "Other link One way info9";
CM_ SG_ 427 NALOW10 "Other link One way info10";
CM_ SG_ 427 NALOW11 "Other link One way info11";
CM_ SG_ 427 NALOW12 "Other link One way info12";
CM_ SG_ 427 NALOW13 "Other link One way info13";
CM_ SG_ 427 NALOW14 "Other link One way info14";
CM_ SG_ 427 NALOW15 "Other link One way info15";
CM_ SG_ 427 NALOW16 "Other link One way info16";
CM_ SG_ 427 NALOW17 "Other link One way info17";
CM_ SG_ 427 NALOW18 "Other link One way info18";
CM_ SG_ 427 NALOW19 "Other link One way info19";
CM_ SG_ 427 NALOW20 "Other link One way info20";
CM_ SG_ 427 NALOW21 "Other link One way info21";
CM_ SG_ 427 NALOW22 "Other link One way info22";
CM_ SG_ 427 NALOW23 "Other link One way info23";
CM_ SG_ 427 NALOW24 "Other link One way info24";
CM_ SG_ 427 NALNEN7 "Other link No entry info 7";
CM_ SG_ 427 NALNEN8 "Other link No entry info 8";
CM_ SG_ 427 NALNEN9 "Other link No entry info 9";
CM_ SG_ 427 NALNEN10 "Other link No entry info 10";
CM_ SG_ 427 NALNEN11 "Other link No entry info 11";
CM_ SG_ 427 NALNEN12 "Other link No entry info 12";
CM_ SG_ 427 NALNEN13 "Other link No entry info 13";
CM_ SG_ 427 NALNEN14 "Other link No entry info 14";
CM_ SG_ 427 NALNEN15 "Other link No entry info 15";
CM_ SG_ 427 NALNEN16 "Other link No entry info 16";
CM_ SG_ 427 NALNEN17 "Other link No entry info 17";
CM_ SG_ 427 NALNEN18 "Other link No entry info 18";
CM_ SG_ 427 NALNEN19 "Other link No entry info 19";
CM_ SG_ 427 NALNEN20 "Other link No entry info 20";
CM_ SG_ 427 NALNEN21 "Other link No entry info 21";
CM_ SG_ 427 NALNEN22 "Other link No entry info 22";
CM_ SG_ 427 NALNEN23 "Other link No entry info 23";
CM_ SG_ 427 NALNEN24 "Other link No entry info 24";
CM_ SG_ 427 NALANG7 "Other link angle 7";
CM_ SG_ 427 NALANG8 "Other link angle 8";
CM_ SG_ 427 NALANG9 "Other link angle 9";
CM_ SG_ 427 NALANG10 "Other link angle 10";
CM_ SG_ 427 NALANG11 "Other link angle 11";
CM_ SG_ 427 NALANG12 "Other link angle 12";
CM_ SG_ 427 NALANG13 "Other link angle 13";
CM_ SG_ 427 NALANG14 "Other link angle 14";
CM_ SG_ 427 NALANG15 "Other link angle 15";
CM_ SG_ 427 NALANG16 "Other link angle 16";
CM_ SG_ 427 NALANG17 "Other link angle 17";
CM_ SG_ 427 NALANG18 "Other link angle 18";
CM_ SG_ 427 NALANG19 "Other link angle 19";
CM_ SG_ 427 NALANG20 "Other link angle 20";
CM_ SG_ 427 NALNEN1 "Other link No entry info 1";
CM_ SG_ 427 NALANG1 "Other link angle 1";
CM_ SG_ 427 NALNEN2 "Other link No entry info 2";
CM_ SG_ 427 NALANG2 "Other link angle 2";
CM_ SG_ 427 NALNEN3 "Other link No entry info 3";
CM_ SG_ 427 NALANG3 "Other link angle 3";
CM_ SG_ 427 NALNEN4 "Other link No entry info 4";
CM_ SG_ 427 NALANG4 "Other link angle 4";
CM_ SG_ 427 NALNEN5 "Other link No entry info 5";
CM_ SG_ 427 NALANG5 "Other link angle 5";
CM_ SG_ 427 NALNEN6 "Other link No entry info 6";
CM_ SG_ 427 NALANG6 "Other link angle 6";
CM_ BO_ 428 "Reserve";
CM_ SG_ 428 FRMSID16 "Frame sync ID16";
CM_ SG_ 428 BRDU1 "Distance unit to branch entrance point 1";
CM_ SG_ 428 BRDU2 "Distance unit to branch entrance point 2";
CM_ SG_ 428 BRDU3 "Distance unit to branch entrance point 3";
CM_ SG_ 428 BRDIST1 "Distance to branch entrance point 1";
CM_ SG_ 428 BRDIST2 "Distance to branch entrance point 2";
CM_ SG_ 428 BRDIST3 "Distance to branch entrance point 3";
CM_ SG_ 428 BRVFLG1 "Branch section length valid flag 1";
CM_ SG_ 428 BRVFLG2 "Branch section length valid flag 2";
CM_ SG_ 428 BRVFLG3 "Branch section length valid flag 3";
CM_ SG_ 428 BRLEN1 "Branch section length 1";
CM_ SG_ 428 BRLEN2 "Branch section length 2";
CM_ SG_ 428 BRLEN3 "Branch section length 3";
CM_ SG_ 428 NALANG21 "Other link angle 21";
CM_ SG_ 428 NALANG22 "Other link angle 22";
CM_ SG_ 428 NALANG23 "Other link angle 23";
CM_ SG_ 428 NALANG24 "Other link angle 24";
CM_ SG_ 428 NALCNF1 "Other link connection information 1";
CM_ SG_ 428 NALCNF2 "Other link connection information 2";
CM_ SG_ 428 NALCNF3 "Other link connection information 3";
CM_ SG_ 428 NALCNF4 "Other link connection information 4";
CM_ SG_ 428 NALCNF5 "Other link connection information 5";
CM_ SG_ 428 NALCNF6 "Other link connection information 6";
CM_ SG_ 428 NALCNF7 "Other link connection information 7";
CM_ SG_ 428 NALCNF8 "Other link connection information 8";
CM_ SG_ 428 NALCNF9 "Other link connection information 9";
CM_ SG_ 428 NALCNF10 "Other link connection information 10";
CM_ SG_ 428 NALCNF11 "Other link connection information 11";
CM_ SG_ 428 NALCNF12 "Other link connection information 12";
CM_ SG_ 428 NALCNF13 "Other link connection information 13";
CM_ SG_ 428 NALCNF14 "Other link connection information 14";
CM_ SG_ 428 NALCNF15 "Other link connection information 15";
CM_ SG_ 428 NALCNF16 "Other link connection information 16";
CM_ SG_ 428 NALCNF17 "Other link connection information 17";
CM_ SG_ 428 NALCNF18 "Other link connection information 18";
CM_ SG_ 428 NALCNF19 "Other link connection information 19";
CM_ SG_ 428 NALCNF20 "Other link connection information 20";
CM_ SG_ 428 NALCNF21 "Other link connection information 21";
CM_ SG_ 428 NALCNF22 "Other link connection information 22";
CM_ SG_ 428 NALCNF23 "Other link connection information 23";
CM_ SG_ 428 NALCNF24 "Other link connection information 24";
CM_ SG_ 428 NALDIV1 "Other link Divider info 1";
CM_ SG_ 428 NALDIV2 "Other link Divider info 2";
CM_ SG_ 428 NALDIV3 "Other link Divider info 3";
CM_ SG_ 428 NALDIV4 "Other link Divider info 4";
CM_ SG_ 428 NALDIV5 "Other link Divider info 5";
CM_ SG_ 428 NALDIV6 "Other link Divider info 6";
CM_ SG_ 428 NALDIV7 "Other link Divider info 7";
CM_ SG_ 428 NALDIV8 "Other link Divider info 8";
CM_ SG_ 428 NALDIV9 "Other link Divider info 9";
CM_ SG_ 428 NALDIV10 "Other link Divider info 10";
CM_ SG_ 428 NALDIV11 "Other link Divider info 11";
CM_ SG_ 428 NALDIV12 "Other link Divider info 12";
CM_ SG_ 428 NALDIV13 "Other link Divider info 13";
CM_ SG_ 428 NALDIV14 "Other link Divider info 14";
CM_ SG_ 428 NALDIV15 "Other link Divider info 15";
CM_ SG_ 428 NALDIV16 "Other link Divider info 16";
CM_ SG_ 428 NALDIV17 "Other link Divider info 17";
CM_ SG_ 428 NALDIV18 "Other link Divider info 18";
CM_ SG_ 428 NALDIV19 "Other link Divider info 19";
CM_ SG_ 428 NALDIV20 "Other link Divider info 20";
CM_ SG_ 428 NALDIV21 "Other link Divider info 21";
CM_ SG_ 428 NALDIV22 "Other link Divider info 22";
CM_ SG_ 428 NALDIV23 "Other link Divider info 23";
CM_ SG_ 428 NALDIV24 "Other link Divider info 24";
CM_ SG_ 428 NALPRI1 "Other link Priority road / Non-priority road information1";
CM_ SG_ 428 NALPRI2 "Other link Priority road / Non-priority road information2";
CM_ SG_ 428 NALPRI3 "Other link Priority road / Non-priority road information3";
CM_ SG_ 428 NALPRI4 "Other link Priority road / Non-priority road information4";
CM_ SG_ 428 NALPRI5 "Other link Priority road / Non-priority road information5";
CM_ SG_ 428 NALPRI6 "Other link Priority road / Non-priority road information6";
CM_ SG_ 428 NALPRI7 "Other link Priority road / Non-priority road information7";
CM_ SG_ 428 NALPRI8 "Other link Priority road / Non-priority road information8";
CM_ SG_ 428 NALPRI9 "Other link Priority road / Non-priority road information9";
CM_ SG_ 428 NALPRI10 "Other link Priority road / Non-priority road information10";
CM_ SG_ 428 NALPRI11 "Other link Priority road / Non-priority road information11";
CM_ SG_ 428 NALPRI12 "Other link Priority road / Non-priority road information12";
CM_ SG_ 428 NALPRI13 "Other link Priority road / Non-priority road information13";
CM_ SG_ 428 NALPRI14 "Other link Priority road / Non-priority road information14";
CM_ SG_ 428 NALPRI15 "Other link Priority road / Non-priority road information15";
CM_ SG_ 428 NALPRI16 "Other link Priority road / Non-priority road information16";
CM_ SG_ 428 NALPRI17 "Other link Priority road / Non-priority road information17";
CM_ SG_ 428 NALPRI18 "Other link Priority road / Non-priority road information18";
CM_ SG_ 428 NALPRI19 "Other link Priority road / Non-priority road information19";
CM_ SG_ 428 NALPRI20 "Other link Priority road / Non-priority road information20";
CM_ SG_ 428 NALPRI21 "Other link Priority road / Non-priority road information21";
CM_ SG_ 428 NALPRI22 "Other link Priority road / Non-priority road information22";
CM_ SG_ 428 NALPRI23 "Other link Priority road / Non-priority road information23";
CM_ SG_ 428 NALPRI24 "Other link Priority road / Non-priority road information24";
CM_ SG_ 428 NALALF1 "Other link Entry allowed flag by turn signal 1";
CM_ SG_ 428 NALALF2 "Other link Entry allowed flag by turn signal 2";
CM_ SG_ 428 NALALF3 "Other link Entry allowed flag by turn signal 3";
CM_ SG_ 428 NALALF4 "Other link Entry allowed flag by turn signal 4";
CM_ BO_ 421 "Reserve";
CM_ SG_ 421 FMMC1 "Map Matching Latitude";
CM_ SG_ 421 FMMC2 "Map matching longitude";
CM_ SG_ 421 MPOTJ "Map Matching position Traffic jam level";
CM_ SG_ 421 FWTJ1 "Forward Traffic jam level1";
CM_ SG_ 421 FWTJ2 "Forward Traffic jam level2";
CM_ SG_ 421 FWTJ3 "Forward Traffic jam level3";
CM_ SG_ 421 FWTJ4 "Forward Traffic jam level4";
CM_ SG_ 421 FWTJ5 "Forward Traffic jam level5";
CM_ SG_ 421 FWTJ6 "Forward Traffic jam level6";
CM_ SG_ 421 TJDISTU1 "Distance unit to Traffic jam1";
CM_ SG_ 421 TJDISTU2 "Distance unit to Traffic jam2";
CM_ SG_ 421 TJDISTU3 "Distance unit to Traffic jam3";
CM_ SG_ 421 TJDISTU4 "Distance unit to Traffic jam4";
CM_ SG_ 421 TJDISTU5 "Distance unit to Traffic jam5";
CM_ SG_ 421 TJDISTU6 "Distance unit to Traffic jam6";
CM_ SG_ 421 TJDIST1 "Distance to Traffic jam1";
CM_ SG_ 421 TJDIST2 "Distance to Traffic jam2";
CM_ SG_ 421 TJDIST3 "Distance to Traffic jam3";
CM_ SG_ 421 TJDIST4 "Distance to Traffic jam4";
CM_ SG_ 421 TJDIST5 "Distance to Traffic jam5";
CM_ SG_ 421 TJDIST6 "Distance to Traffic jam6";
CM_ SG_ 421 SBSTDTU "Distance unit to Speedbump entrance point";
CM_ SG_ 421 SBSTDT "Distance to Speedbump entrance point";
CM_ SG_ 421 SBLENFLG "Speedbump section length valid flag";
CM_ SG_ 421 SBLEN "Speedbump section length";
CM_ SG_ 421 NSPVAL1 "Navigation speed value 1";
CM_ SG_ 421 NSPVAL2 "Navigation speed value 2";
CM_ SG_ 421 NSPVAL3 "Navigation speed value 3";
CM_ SG_ 421 NSPVAL4 "Navigation speed value 4";
CM_ SG_ 421 NSPVAL5 "Navigation speed value 5";
CM_ SG_ 421 NSPVAL6 "Navigation speed value 6";
CM_ SG_ 421 NALALF5 "Other link Entry allowed flag by turn signal 5";
CM_ SG_ 421 NALALF6 "Other link Entry allowed flag by turn signal 6";
CM_ SG_ 421 NALALF7 "Other link Entry allowed flag by turn signal 7";
CM_ SG_ 421 NALALF8 "Other link Entry allowed flag by turn signal 8";
CM_ SG_ 421 NALALF9 "Other link Entry allowed flag by turn signal 9";
CM_ SG_ 421 NALALF10 "Other link Entry allowed flag by turn signal 10";
CM_ SG_ 421 NALALF11 "Other link Entry allowed flag by turn signal 11";
CM_ SG_ 421 NALALF12 "Other link Entry allowed flag by turn signal 12";
CM_ SG_ 421 NALALF13 "Other link Entry allowed flag by turn signal 13";
CM_ SG_ 421 NALALF14 "Other link Entry allowed flag by turn signal 14";
CM_ SG_ 421 NALALF15 "Other link Entry allowed flag by turn signal 15";
CM_ SG_ 421 NALALF16 "Other link Entry allowed flag by turn signal 16";
CM_ SG_ 421 NALALF17 "Other link Entry allowed flag by turn signal 17";
CM_ SG_ 421 NALALF18 "Other link Entry allowed flag by turn signal 18";
CM_ SG_ 421 NALALF19 "Other link Entry allowed flag by turn signal 19";
CM_ SG_ 421 NALALF20 "Other link Entry allowed flag by turn signal 20";
CM_ SG_ 421 NALALF21 "Other link Entry allowed flag by turn signal 21";
CM_ SG_ 421 NALALF22 "Other link Entry allowed flag by turn signal 22";
CM_ SG_ 421 NALALF23 "Other link Entry allowed flag by turn signal 23";
CM_ SG_ 421 NALALF24 "Other link Entry allowed flag by turn signal 24";
CM_ SG_ 421 FRMSID17 "Frame sync ID17";
CM_ SG_ 421 FNSPLSN1 "Navigation supplemental sign 1";
CM_ SG_ 421 FNSPLSN2 "Navigation supplemental sign 2";
CM_ SG_ 421 FNSPLSN3 "Navigation supplemental sign 3";
CM_ SG_ 421 FNSPLSN4 "Navigation supplemental sign 4";
CM_ SG_ 421 FNSPLSN5 "Navigation supplemental sign 5";
CM_ SG_ 421 FNSPLSN6 "Navigation supplemental sign 6";
CM_ BO_ 423 "Reserve";
CM_ SG_ 423 FLID "Link ID";
CM_ SG_ 423 FDLID "Link ID difference";
CM_ SG_ 423 FRCODE "Region Code";
CM_ SG_ 423 FDLINKP "Distance from link entry point";
CM_ SG_ 423 MPOAVSP "Map Matching position Average speed";
CM_ SG_ 423 MPOAVSPU "Map Matching position Average speed unit";
CM_ SG_ 423 FWAVSP1 "Forward Average speed1";
CM_ SG_ 423 FWAVSP2 "Forward Average speed2";
CM_ SG_ 423 FWAVSP3 "Forward Average speed3";
CM_ SG_ 423 FWAVSP4 "Forward Average speed4";
CM_ SG_ 423 FWAVSP5 "Forward Average speed5";
CM_ SG_ 423 FWAVSP6 "Forward Average speed6";
CM_ SG_ 423 FWAVSPU1 "Forward Average speed unit1";
CM_ SG_ 423 FWAVSPU2 "Forward Average speed unit2";
CM_ SG_ 423 FWAVSPU3 "Forward Average speed unit3";
CM_ SG_ 423 FWAVSPU4 "Forward Average speed unit4";
CM_ SG_ 423 FWAVSPU5 "Forward Average speed unit5";
CM_ SG_ 423 FWAVSPU6 "Forward Average speed unit6";
CM_ SG_ 423 AVSPDTU1 "Distance unit to Average speed1";
CM_ SG_ 423 AVSPDTU2 "Distance unit to Average speed2";
CM_ SG_ 423 AVSPDTU3 "Distance unit to Average speed3";
CM_ SG_ 423 AVSPDTU4 "Distance unit to Average speed4";
CM_ SG_ 423 AVSPDTU5 "Distance unit to Average speed5";
CM_ SG_ 423 AVSPDTU6 "Distance unit to Average speed6";
CM_ SG_ 423 AVSPDT1 "Distance to Average speed1";
CM_ SG_ 423 AVSPDT2 "Distance to Average speed2";
CM_ SG_ 423 AVSPDT3 "Distance to Average speed3";
CM_ SG_ 423 AVSPDT4 "Distance to Average speed4";
CM_ SG_ 423 AVSPDT5 "Distance to Average speed5";
CM_ SG_ 423 AVSPDT6 "Distance to Average speed6";
CM_ SG_ 423 FRMSID18 "Frame sync ID18";
CM_ SG_ 423 NMAPVER "Navi map version";
CM_ BO_ 419 "Reserve";
CM_ SG_ 419 USMNCRN "DA Sharp curve";
CM_ SG_ 419 USMCRN6 "DA Middle curve";
CM_ SG_ 419 USMCRN5 "DA Gentle curve";
CM_ BO_ 759 "Reserve";
CM_ SG_ 759 BD_CLR_1 "Body color information1(Ambient)";
CM_ SG_ 759 BD_CLR_2 "Body color information1(Diffuse)";
CM_ SG_ 759 BD_CLR_3 "Body color information1(Specular)";
CM_ SG_ 759 BD_CLR_4 "Body color information1(Shininess)";
CM_ SG_ 759 BD_CLR_5 "Body color information2(Ambient)";
CM_ SG_ 759 BD_CLR_6 "Body color information2(Diffuse)";
CM_ SG_ 759 BD_CLR_7 "Body color information2(Specular)";
CM_ SG_ 759 BD_CLR_8 "Body color information2(Shininess)";
CM_ SG_ 759 CD_DSPST "Center display status";
CM_ SG_ 759 PVM_REQ "PVM switching request";
BA_DEF_ BO_  "GenMsgILSupport" ENUM  "No","Yes";
BA_DEF_ BO_  "GenMsgSendType" ENUM  "Cyclic","NotUsed","NotUsed","NotUsed","NotUsed","NotUsed","NotUsed","NotUsed","NoMsgSendType";
BA_DEF_ SG_  "GenSigSendType" ENUM  "Cyclic","OnWrite","OnWriteWithRepetition","OnChange","OnChangeWithRepetition","NotUsed","NotUsed","NoSigSendType";
BA_DEF_ BO_  "GenMsgCycleTime" INT 0 65535;
BA_DEF_ SG_  "GenSigStartValue" FLOAT 0 100000000000;
BA_DEF_ BO_  "GenMsgStartDelayTime" INT 0 100000;
BA_DEF_ BO_  "VFrameFormat" ENUM  "StandardCAN","ExtendedCAN","reserved","reserved","reserved","reserved","reserved","reserved","reserved","reserved","reserved","reserved","reserved","reserved","StandardCAN_FD","ExtendedCAN_FD";
BA_DEF_ BO_  "CANFD_BRS" ENUM  "0","1";
BA_DEF_ BO_  "DiagConnection" HEX 0 65535;
BA_DEF_DEF_  "GenMsgILSupport" "No";
BA_DEF_DEF_  "GenMsgSendType" "NoMsgSendType";
BA_DEF_DEF_  "GenSigSendType" "NoSigSendType";
BA_DEF_DEF_  "GenMsgCycleTime" 0;
BA_DEF_DEF_  "GenSigStartValue" 0;
BA_DEF_DEF_  "GenMsgStartDelayTime" 0;
BA_DEF_DEF_  "VFrameFormat" "";
BA_DEF_DEF_  "CANFD_BRS" "1";
BA_DEF_DEF_  "DiagConnection" 3000.00004970533;
BA_ "GenMsgCycleTime" BO_ 417 200;
BA_ "GenMsgSendType" BO_ 417 0;
BA_ "GenMsgILSupport" BO_ 417 1;
BA_ "GenMsgStartDelayTime" BO_ 417 104;
BA_ "VFrameFormat" BO_ 417 14;
BA_ "GenMsgCycleTime" BO_ 418 200;
BA_ "GenMsgSendType" BO_ 418 0;
BA_ "GenMsgILSupport" BO_ 418 1;
BA_ "GenMsgStartDelayTime" BO_ 418 108;
BA_ "VFrameFormat" BO_ 418 14;
BA_ "GenMsgCycleTime" BO_ 440 200;
BA_ "GenMsgSendType" BO_ 440 0;
BA_ "GenMsgILSupport" BO_ 440 1;
BA_ "GenMsgStartDelayTime" BO_ 440 112;
BA_ "VFrameFormat" BO_ 440 14;
BA_ "GenMsgCycleTime" BO_ 441 200;
BA_ "GenMsgSendType" BO_ 441 0;
BA_ "GenMsgILSupport" BO_ 441 1;
BA_ "GenMsgStartDelayTime" BO_ 441 116;
BA_ "VFrameFormat" BO_ 441 14;
BA_ "GenMsgCycleTime" BO_ 439 200;
BA_ "GenMsgSendType" BO_ 439 0;
BA_ "GenMsgILSupport" BO_ 439 1;
BA_ "GenMsgStartDelayTime" BO_ 439 120;
BA_ "VFrameFormat" BO_ 439 14;
BA_ "GenMsgCycleTime" BO_ 437 200;
BA_ "GenMsgSendType" BO_ 437 0;
BA_ "GenMsgILSupport" BO_ 437 1;
BA_ "GenMsgStartDelayTime" BO_ 437 124;
BA_ "VFrameFormat" BO_ 437 14;
BA_ "GenMsgCycleTime" BO_ 429 200;
BA_ "GenMsgSendType" BO_ 429 0;
BA_ "GenMsgILSupport" BO_ 429 1;
BA_ "GenMsgStartDelayTime" BO_ 429 128;
BA_ "VFrameFormat" BO_ 429 14;
BA_ "GenMsgCycleTime" BO_ 431 200;
BA_ "GenMsgSendType" BO_ 431 0;
BA_ "GenMsgILSupport" BO_ 431 1;
BA_ "GenMsgStartDelayTime" BO_ 431 132;
BA_ "VFrameFormat" BO_ 431 14;
BA_ "GenMsgCycleTime" BO_ 432 200;
BA_ "GenMsgSendType" BO_ 432 0;
BA_ "GenMsgILSupport" BO_ 432 1;
BA_ "GenMsgStartDelayTime" BO_ 432 136;
BA_ "VFrameFormat" BO_ 432 14;
BA_ "GenMsgCycleTime" BO_ 435 200;
BA_ "GenMsgSendType" BO_ 435 0;
BA_ "GenMsgILSupport" BO_ 435 1;
BA_ "GenMsgStartDelayTime" BO_ 435 140;
BA_ "VFrameFormat" BO_ 435 14;
BA_ "GenMsgCycleTime" BO_ 436 200;
BA_ "GenMsgSendType" BO_ 436 0;
BA_ "GenMsgILSupport" BO_ 436 1;
BA_ "GenMsgStartDelayTime" BO_ 436 144;
BA_ "VFrameFormat" BO_ 436 14;
BA_ "GenMsgCycleTime" BO_ 430 200;
BA_ "GenMsgSendType" BO_ 430 0;
BA_ "GenMsgILSupport" BO_ 430 1;
BA_ "GenMsgStartDelayTime" BO_ 430 148;
BA_ "VFrameFormat" BO_ 430 14;
BA_ "GenMsgCycleTime" BO_ 424 200;
BA_ "GenMsgSendType" BO_ 424 0;
BA_ "GenMsgILSupport" BO_ 424 1;
BA_ "GenMsgStartDelayTime" BO_ 424 152;
BA_ "VFrameFormat" BO_ 424 14;
BA_ "GenMsgCycleTime" BO_ 425 200;
BA_ "GenMsgSendType" BO_ 425 0;
BA_ "GenMsgILSupport" BO_ 425 1;
BA_ "GenMsgStartDelayTime" BO_ 425 156;
BA_ "VFrameFormat" BO_ 425 14;
BA_ "GenMsgCycleTime" BO_ 427 200;
BA_ "GenMsgSendType" BO_ 427 0;
BA_ "GenMsgILSupport" BO_ 427 1;
BA_ "GenMsgStartDelayTime" BO_ 427 160;
BA_ "VFrameFormat" BO_ 427 14;
BA_ "GenMsgCycleTime" BO_ 428 200;
BA_ "GenMsgSendType" BO_ 428 0;
BA_ "GenMsgILSupport" BO_ 428 1;
BA_ "GenMsgStartDelayTime" BO_ 428 164;
BA_ "VFrameFormat" BO_ 428 14;
BA_ "GenMsgCycleTime" BO_ 421 200;
BA_ "GenMsgSendType" BO_ 421 0;
BA_ "GenMsgILSupport" BO_ 421 1;
BA_ "GenMsgStartDelayTime" BO_ 421 168;
BA_ "VFrameFormat" BO_ 421 14;
BA_ "GenMsgCycleTime" BO_ 423 200;
BA_ "GenMsgSendType" BO_ 423 0;
BA_ "GenMsgILSupport" BO_ 423 1;
BA_ "GenMsgStartDelayTime" BO_ 423 172;
BA_ "VFrameFormat" BO_ 423 14;
BA_ "GenMsgCycleTime" BO_ 419 200;
BA_ "GenMsgSendType" BO_ 419 0;
BA_ "GenMsgILSupport" BO_ 419 1;
BA_ "GenMsgStartDelayTime" BO_ 419 176;
BA_ "VFrameFormat" BO_ 419 14;
BA_ "GenMsgCycleTime" BO_ 759 1000;
BA_ "GenMsgSendType" BO_ 759 0;
BA_ "GenMsgILSupport" BO_ 759 1;
BA_ "GenMsgStartDelayTime" BO_ 759 180;
BA_ "VFrameFormat" BO_ 759 14;
BA_ "GenSigStartValue" SG_ 417 FRMSID1 31;
BA_ "GenSigStartValue" SG_ 417 MAPCNTR 3;
BA_ "GenSigStartValue" SG_ 417 DAYLOCUP 65535;
BA_ "GenSigStartValue" SG_ 417 DAYCENUP 65535;
BA_ "GenSigStartValue" SG_ 417 SUBDIVCD 63;
BA_ "GenSigStartValue" SG_ 417 SNBINF3 7;
BA_ "GenSigStartValue" SG_ 417 SNBINF4 7;
BA_ "GenSigStartValue" SG_ 417 SNBDIST3 255;
BA_ "GenSigStartValue" SG_ 417 SNBDIST4 255;
BA_ "GenSigStartValue" SG_ 417 SPLDIST3 255;
BA_ "GenSigStartValue" SG_ 417 SPLDIST4 255;
BA_ "GenSigStartValue" SG_ 417 STINF 3;
BA_ "GenSigStartValue" SG_ 417 STDIST 255;
BA_ "GenSigStartValue" SG_ 417 TRLDIST3 255;
BA_ "GenSigStartValue" SG_ 417 TRLDIST4 255;
BA_ "GenSigStartValue" SG_ 417 TRLDIST5 255;
BA_ "GenSigStartValue" SG_ 417 TRLDIST6 255;
BA_ "GenSigStartValue" SG_ 417 TRLDIST1 255;
BA_ "GenSigStartValue" SG_ 417 TRLDIST2 255;
BA_ "GenSigStartValue" SG_ 417 SNBINF1 7;
BA_ "GenSigStartValue" SG_ 417 SNBDIST1 255;
BA_ "GenSigStartValue" SG_ 417 SNBINF2 7;
BA_ "GenSigStartValue" SG_ 417 SNBDIST2 255;
BA_ "GenSigStartValue" SG_ 417 SPLDIST1 255;
BA_ "GenSigStartValue" SG_ 417 SPLDIST2 255;
BA_ "GenSigStartValue" SG_ 417 SENSST 7;
BA_ "GenSigStartValue" SG_ 417 SENSORF 7;
BA_ "GenSigStartValue" SG_ 417 RTGUIDST 3;
BA_ "GenSigStartValue" SG_ 417 MAPMCNFD 255;
BA_ "GenSigStartValue" SG_ 417 MLTMDST 3;
BA_ "GenSigStartValue" SG_ 417 MAPCVR 3;
BA_ "GenSigStartValue" SG_ 417 RERTCNTR 15;
BA_ "GenSigStartValue" SG_ 417 CNTRYCD 1023;
BA_ "GenSigStartValue" SG_ 418 FRMSID2 31;
BA_ "GenSigStartValue" SG_ 418 TOLDIST2 255;
BA_ "GenSigStartValue" SG_ 418 TOLDIST3 255;
BA_ "GenSigStartValue" SG_ 418 TOLSTY2 255;
BA_ "GenSigStartValue" SG_ 418 TOLSTY3 255;
BA_ "GenSigStartValue" SG_ 418 PAYMT1 1023;
BA_ "GenSigStartValue" SG_ 418 PAYMT2 1023;
BA_ "GenSigStartValue" SG_ 418 PAYMT3 1023;
BA_ "GenSigStartValue" SG_ 418 RLDXDST3 255;
BA_ "GenSigStartValue" SG_ 418 RLDXDST4 255;
BA_ "GenSigStartValue" SG_ 418 FWMED1 3;
BA_ "GenSigStartValue" SG_ 418 FWMED2 3;
BA_ "GenSigStartValue" SG_ 418 FWMED3 3;
BA_ "GenSigStartValue" SG_ 418 FWMED4 3;
BA_ "GenSigStartValue" SG_ 418 FWMED5 3;
BA_ "GenSigStartValue" SG_ 418 MEDDIST1 255;
BA_ "GenSigStartValue" SG_ 418 MEDDIST2 255;
BA_ "GenSigStartValue" SG_ 418 MEDDIST3 255;
BA_ "GenSigStartValue" SG_ 418 MEDDIST4 255;
BA_ "GenSigStartValue" SG_ 418 MEDDIST5 255;
BA_ "GenSigStartValue" SG_ 418 MPMEDFLG 3;
BA_ "GenSigStartValue" SG_ 418 MPLNNUM 15;
BA_ "GenSigStartValue" SG_ 418 LNNUM1 15;
BA_ "GenSigStartValue" SG_ 418 LNNUM2 15;
BA_ "GenSigStartValue" SG_ 418 LNNUM3 15;
BA_ "GenSigStartValue" SG_ 418 LNNUMD1 255;
BA_ "GenSigStartValue" SG_ 418 LNNUMD2 255;
BA_ "GenSigStartValue" SG_ 418 LNNUMD3 255;
BA_ "GenSigStartValue" SG_ 418 DFLGD1 255;
BA_ "GenSigStartValue" SG_ 418 DFLGD2 255;
BA_ "GenSigStartValue" SG_ 418 MPOSDFLG 3;
BA_ "GenSigStartValue" SG_ 418 DWAYFLG1 3;
BA_ "GenSigStartValue" SG_ 418 DWAYFLG2 3;
BA_ "GenSigStartValue" SG_ 418 TOLDIST1 255;
BA_ "GenSigStartValue" SG_ 418 TOLSTY1 255;
BA_ "GenSigStartValue" SG_ 418 RLDXDST1 255;
BA_ "GenSigStartValue" SG_ 418 RLDXDST2 255;
BA_ "GenSigStartValue" SG_ 440 FRMSID3 31;
BA_ "GenSigStartValue" SG_ 440 LNKTYP1 1023;
BA_ "GenSigStartValue" SG_ 440 LNKTYP2 1023;
BA_ "GenSigStartValue" SG_ 440 LNKTYP3 1023;
BA_ "GenSigStartValue" SG_ 440 LNKTYP4 1023;
BA_ "GenSigStartValue" SG_ 440 LNKTYP5 1023;
BA_ "GenSigStartValue" SG_ 440 LNKTYP6 1023;
BA_ "GenSigStartValue" SG_ 440 LNKTYP7 1023;
BA_ "GenSigStartValue" SG_ 440 LNKTYP8 1023;
BA_ "GenSigStartValue" SG_ 440 LNKTYP9 1023;
BA_ "GenSigStartValue" SG_ 440 LNKTYP10 1023;
BA_ "GenSigStartValue" SG_ 440 LNKD1 255;
BA_ "GenSigStartValue" SG_ 440 LNKD2 255;
BA_ "GenSigStartValue" SG_ 440 LNKD3 255;
BA_ "GenSigStartValue" SG_ 440 LNKD4 255;
BA_ "GenSigStartValue" SG_ 440 LNKD5 255;
BA_ "GenSigStartValue" SG_ 440 LNKD6 255;
BA_ "GenSigStartValue" SG_ 440 LNKD7 255;
BA_ "GenSigStartValue" SG_ 440 LNKD8 255;
BA_ "GenSigStartValue" SG_ 440 LNKD9 255;
BA_ "GenSigStartValue" SG_ 440 LNKD10 255;
BA_ "GenSigStartValue" SG_ 440 MPLNKTYP 1023;
BA_ "GenSigStartValue" SG_ 441 FRMSID4 31;
BA_ "GenSigStartValue" SG_ 441 MPSPLU 3;
BA_ "GenSigStartValue" SG_ 441 FWSPD3 31;
BA_ "GenSigStartValue" SG_ 441 FWSPD4 31;
BA_ "GenSigStartValue" SG_ 441 FWSPD5 31;
BA_ "GenSigStartValue" SG_ 441 FWSPD6 31;
BA_ "GenSigStartValue" SG_ 441 FWSPD7 31;
BA_ "GenSigStartValue" SG_ 441 FWSPTY3 7;
BA_ "GenSigStartValue" SG_ 441 FWSPTY4 7;
BA_ "GenSigStartValue" SG_ 441 FWSPTY5 7;
BA_ "GenSigStartValue" SG_ 441 FWSPTY6 7;
BA_ "GenSigStartValue" SG_ 441 FWSPTY7 7;
BA_ "GenSigStartValue" SG_ 441 FWSPAU3 63;
BA_ "GenSigStartValue" SG_ 441 FWSPAU4 63;
BA_ "GenSigStartValue" SG_ 441 FWSPAU5 63;
BA_ "GenSigStartValue" SG_ 441 FWSPAU6 63;
BA_ "GenSigStartValue" SG_ 441 FWSPAU7 63;
BA_ "GenSigStartValue" SG_ 441 FWSPLU1 3;
BA_ "GenSigStartValue" SG_ 441 FWSPLU2 3;
BA_ "GenSigStartValue" SG_ 441 FWSPLU3 3;
BA_ "GenSigStartValue" SG_ 441 FWSPLU4 3;
BA_ "GenSigStartValue" SG_ 441 FWSPLU5 3;
BA_ "GenSigStartValue" SG_ 441 FWSPLU6 3;
BA_ "GenSigStartValue" SG_ 441 FWSPLU7 3;
BA_ "GenSigStartValue" SG_ 441 SPDIST3 255;
BA_ "GenSigStartValue" SG_ 441 SPDIST4 255;
BA_ "GenSigStartValue" SG_ 441 SPDIST5 255;
BA_ "GenSigStartValue" SG_ 441 SPDIST6 255;
BA_ "GenSigStartValue" SG_ 441 SPDIST7 255;
BA_ "GenSigStartValue" SG_ 441 MPOWFLG 7;
BA_ "GenSigStartValue" SG_ 441 FWOWFLG1 7;
BA_ "GenSigStartValue" SG_ 441 OWDIST1 255;
BA_ "GenSigStartValue" SG_ 441 MPRDTYP 31;
BA_ "GenSigStartValue" SG_ 441 FWRDTYP1 31;
BA_ "GenSigStartValue" SG_ 441 RDTYPD1 255;
BA_ "GenSigStartValue" SG_ 441 FWRDTYP2 31;
BA_ "GenSigStartValue" SG_ 441 RDTYPD2 255;
BA_ "GenSigStartValue" SG_ 441 MPSP1 31;
BA_ "GenSigStartValue" SG_ 441 MPSPTY1 7;
BA_ "GenSigStartValue" SG_ 441 MPSPAU1 63;
BA_ "GenSigStartValue" SG_ 441 FWSPD1 31;
BA_ "GenSigStartValue" SG_ 441 FWSPTY1 7;
BA_ "GenSigStartValue" SG_ 441 FWSPAU1 63;
BA_ "GenSigStartValue" SG_ 441 SPDIST1 255;
BA_ "GenSigStartValue" SG_ 441 FWSPD2 31;
BA_ "GenSigStartValue" SG_ 441 FWSPTY2 7;
BA_ "GenSigStartValue" SG_ 441 FWSPAU2 63;
BA_ "GenSigStartValue" SG_ 441 SPDIST2 255;
BA_ "GenSigStartValue" SG_ 439 FRMSID5 31;
BA_ "GenSigStartValue" SG_ 439 TNENTD1 255;
BA_ "GenSigStartValue" SG_ 439 TNENTD2 255;
BA_ "GenSigStartValue" SG_ 439 TNENTD3 255;
BA_ "GenSigStartValue" SG_ 439 TNENTD4 255;
BA_ "GenSigStartValue" SG_ 439 TNENTD5 255;
BA_ "GenSigStartValue" SG_ 439 TNLEN1 255;
BA_ "GenSigStartValue" SG_ 439 TNLEN2 255;
BA_ "GenSigStartValue" SG_ 439 TNLEN3 255;
BA_ "GenSigStartValue" SG_ 439 TNLEN4 255;
BA_ "GenSigStartValue" SG_ 439 TNLEN5 255;
BA_ "GenSigStartValue" SG_ 439 BRGDIST1 255;
BA_ "GenSigStartValue" SG_ 439 BRGDIST2 255;
BA_ "GenSigStartValue" SG_ 439 BRGDIST3 255;
BA_ "GenSigStartValue" SG_ 439 BRGLEN1 255;
BA_ "GenSigStartValue" SG_ 439 BRGLEN2 255;
BA_ "GenSigStartValue" SG_ 439 BRGLEN3 255;
BA_ "GenSigStartValue" SG_ 437 FRMSID6 31;
BA_ "GenSigStartValue" SG_ 437 MPOSCURV 511;
BA_ "GenSigStartValue" SG_ 437 CURINFO1 511;
BA_ "GenSigStartValue" SG_ 437 CURINFO3 511;
BA_ "GenSigStartValue" SG_ 437 CURINFO4 511;
BA_ "GenSigStartValue" SG_ 437 MPCURACR 3;
BA_ "GenSigStartValue" SG_ 437 PCURACR1 3;
BA_ "GenSigStartValue" SG_ 437 PCURACR2 3;
BA_ "GenSigStartValue" SG_ 437 PCURACR3 3;
BA_ "GenSigStartValue" SG_ 437 PCURACR4 3;
BA_ "GenSigStartValue" SG_ 437 SCURAC1 3;
BA_ "GenSigStartValue" SG_ 437 SCURAC2 3;
BA_ "GenSigStartValue" SG_ 437 SCURAC3 3;
BA_ "GenSigStartValue" SG_ 437 SCURAC4 3;
BA_ "GenSigStartValue" SG_ 437 SCURAC5 3;
BA_ "GenSigStartValue" SG_ 437 SCURAC6 3;
BA_ "GenSigStartValue" SG_ 437 SCURAC7 3;
BA_ "GenSigStartValue" SG_ 437 SCURAC8 3;
BA_ "GenSigStartValue" SG_ 437 SCURAC9 3;
BA_ "GenSigStartValue" SG_ 437 SCURAC10 3;
BA_ "GenSigStartValue" SG_ 437 SCURAC11 3;
BA_ "GenSigStartValue" SG_ 437 CURD1 1023;
BA_ "GenSigStartValue" SG_ 437 CURD2 1023;
BA_ "GenSigStartValue" SG_ 437 CURVAL11 511;
BA_ "GenSigStartValue" SG_ 437 CURINF11 7;
BA_ "GenSigStartValue" SG_ 437 CURVAL9 511;
BA_ "GenSigStartValue" SG_ 437 CURINF9 7;
BA_ "GenSigStartValue" SG_ 437 CURVAL10 511;
BA_ "GenSigStartValue" SG_ 437 CURINF10 7;
BA_ "GenSigStartValue" SG_ 437 CURINFO2 511;
BA_ "GenSigStartValue" SG_ 437 CURVAL1 511;
BA_ "GenSigStartValue" SG_ 437 CURINF1 7;
BA_ "GenSigStartValue" SG_ 437 CURVAL2 511;
BA_ "GenSigStartValue" SG_ 437 CURINF2 7;
BA_ "GenSigStartValue" SG_ 437 CURVAL3 511;
BA_ "GenSigStartValue" SG_ 437 CURINF3 7;
BA_ "GenSigStartValue" SG_ 437 CURVAL4 511;
BA_ "GenSigStartValue" SG_ 437 CURINF4 7;
BA_ "GenSigStartValue" SG_ 437 CURVAL5 511;
BA_ "GenSigStartValue" SG_ 437 CURINF5 7;
BA_ "GenSigStartValue" SG_ 437 CURVAL6 511;
BA_ "GenSigStartValue" SG_ 437 CURINF6 7;
BA_ "GenSigStartValue" SG_ 437 CURVAL7 511;
BA_ "GenSigStartValue" SG_ 437 CURINF7 7;
BA_ "GenSigStartValue" SG_ 437 CURVAL8 511;
BA_ "GenSigStartValue" SG_ 437 CURINF8 7;
BA_ "GenSigStartValue" SG_ 429 FRMSID7 31;
BA_ "GenSigStartValue" SG_ 429 CURD3 1023;
BA_ "GenSigStartValue" SG_ 429 CURD4 1023;
BA_ "GenSigStartValue" SG_ 429 CURD5 1023;
BA_ "GenSigStartValue" SG_ 429 CURD6 1023;
BA_ "GenSigStartValue" SG_ 429 CURD7 1023;
BA_ "GenSigStartValue" SG_ 429 CURD8 1023;
BA_ "GenSigStartValue" SG_ 429 CURD9 1023;
BA_ "GenSigStartValue" SG_ 429 CURD10 1023;
BA_ "GenSigStartValue" SG_ 429 CURD11 1023;
BA_ "GenSigStartValue" SG_ 429 MPOSLOPE 63;
BA_ "GenSigStartValue" SG_ 429 SLPINF1 63;
BA_ "GenSigStartValue" SG_ 429 SLPINF2 63;
BA_ "GenSigStartValue" SG_ 429 SLPINF3 63;
BA_ "GenSigStartValue" SG_ 429 SLPINF4 63;
BA_ "GenSigStartValue" SG_ 429 SLPINF5 63;
BA_ "GenSigStartValue" SG_ 429 MPSLPAC 3;
BA_ "GenSigStartValue" SG_ 429 PSLPAC1 3;
BA_ "GenSigStartValue" SG_ 429 PSLPAC2 3;
BA_ "GenSigStartValue" SG_ 429 PSLPAC3 3;
BA_ "GenSigStartValue" SG_ 429 PSLPAC4 3;
BA_ "GenSigStartValue" SG_ 429 PSLPAC5 3;
BA_ "GenSigStartValue" SG_ 429 AVESLP1 63;
BA_ "GenSigStartValue" SG_ 429 AVESLP2 63;
BA_ "GenSigStartValue" SG_ 429 AVESLP3 63;
BA_ "GenSigStartValue" SG_ 429 AVESLP4 63;
BA_ "GenSigStartValue" SG_ 429 AVESLP5 63;
BA_ "GenSigStartValue" SG_ 429 AVESLP6 63;
BA_ "GenSigStartValue" SG_ 429 AVESLP7 63;
BA_ "GenSigStartValue" SG_ 429 AVESLP8 63;
BA_ "GenSigStartValue" SG_ 429 AVSLPAC1 3;
BA_ "GenSigStartValue" SG_ 429 AVSLPAC2 3;
BA_ "GenSigStartValue" SG_ 429 AVSLPAC3 3;
BA_ "GenSigStartValue" SG_ 429 AVSLPAC4 3;
BA_ "GenSigStartValue" SG_ 429 AVSLPAC5 3;
BA_ "GenSigStartValue" SG_ 429 AVSLPAC6 3;
BA_ "GenSigStartValue" SG_ 429 AVSLPAC7 3;
BA_ "GenSigStartValue" SG_ 429 AVSLPAC8 3;
BA_ "GenSigStartValue" SG_ 431 FRMSID8 31;
BA_ "GenSigStartValue" SG_ 431 INTID4 31;
BA_ "GenSigStartValue" SG_ 431 INTID5 31;
BA_ "GenSigStartValue" SG_ 431 INTID6 31;
BA_ "GenSigStartValue" SG_ 431 INTID7 31;
BA_ "GenSigStartValue" SG_ 431 INTID8 31;
BA_ "GenSigStartValue" SG_ 431 INTID9 31;
BA_ "GenSigStartValue" SG_ 431 INTID10 31;
BA_ "GenSigStartValue" SG_ 431 INTID11 31;
BA_ "GenSigStartValue" SG_ 431 INTID12 31;
BA_ "GenSigStartValue" SG_ 431 INTDIS4 255;
BA_ "GenSigStartValue" SG_ 431 INTDIS5 255;
BA_ "GenSigStartValue" SG_ 431 INTDIS6 255;
BA_ "GenSigStartValue" SG_ 431 INTDIS7 255;
BA_ "GenSigStartValue" SG_ 431 INTDIS8 255;
BA_ "GenSigStartValue" SG_ 431 INTDIS9 255;
BA_ "GenSigStartValue" SG_ 431 INTDIS10 255;
BA_ "GenSigStartValue" SG_ 431 INTDIS11 255;
BA_ "GenSigStartValue" SG_ 431 INTDIS12 255;
BA_ "GenSigStartValue" SG_ 431 INTNLN4 31;
BA_ "GenSigStartValue" SG_ 431 INTNLN5 31;
BA_ "GenSigStartValue" SG_ 431 INTNLN6 31;
BA_ "GenSigStartValue" SG_ 431 INTNLN7 31;
BA_ "GenSigStartValue" SG_ 431 INTNLN8 31;
BA_ "GenSigStartValue" SG_ 431 INTNLN9 31;
BA_ "GenSigStartValue" SG_ 431 INTNLN10 31;
BA_ "GenSigStartValue" SG_ 431 INTNLN11 31;
BA_ "GenSigStartValue" SG_ 431 INTNLN12 31;
BA_ "GenSigStartValue" SG_ 431 INTDIS3 255;
BA_ "GenSigStartValue" SG_ 431 INTNLN3 31;
BA_ "GenSigStartValue" SG_ 431 INTID3 31;
BA_ "GenSigStartValue" SG_ 431 INTDIS1 255;
BA_ "GenSigStartValue" SG_ 431 INTDIS2 255;
BA_ "GenSigStartValue" SG_ 431 INTNLN1 31;
BA_ "GenSigStartValue" SG_ 431 INTNLN2 31;
BA_ "GenSigStartValue" SG_ 431 INTID1 31;
BA_ "GenSigStartValue" SG_ 431 INTID2 31;
BA_ "GenSigStartValue" SG_ 432 FRMSID9 31;
BA_ "GenSigStartValue" SG_ 432 ENRDTY4 31;
BA_ "GenSigStartValue" SG_ 432 ENRDTY5 31;
BA_ "GenSigStartValue" SG_ 432 ENRDTY6 31;
BA_ "GenSigStartValue" SG_ 432 ENRDTY7 31;
BA_ "GenSigStartValue" SG_ 432 ENRDTY8 31;
BA_ "GenSigStartValue" SG_ 432 ENRDTY9 31;
BA_ "GenSigStartValue" SG_ 432 ENRDTY10 31;
BA_ "GenSigStartValue" SG_ 432 ENRDTY11 31;
BA_ "GenSigStartValue" SG_ 432 ENRDTY12 31;
BA_ "GenSigStartValue" SG_ 432 ENLNTY4 1023;
BA_ "GenSigStartValue" SG_ 432 ENLNTY5 1023;
BA_ "GenSigStartValue" SG_ 432 ENLNTY6 1023;
BA_ "GenSigStartValue" SG_ 432 ENLNTY7 1023;
BA_ "GenSigStartValue" SG_ 432 ENLNTY8 1023;
BA_ "GenSigStartValue" SG_ 432 ENLNTY9 1023;
BA_ "GenSigStartValue" SG_ 432 ENLNTY10 1023;
BA_ "GenSigStartValue" SG_ 432 ENLNTY11 1023;
BA_ "GenSigStartValue" SG_ 432 ENLNTY12 1023;
BA_ "GenSigStartValue" SG_ 432 ENNMLN1 15;
BA_ "GenSigStartValue" SG_ 432 ENNMLN2 15;
BA_ "GenSigStartValue" SG_ 432 ENNMLN3 15;
BA_ "GenSigStartValue" SG_ 432 ENNMLN4 15;
BA_ "GenSigStartValue" SG_ 432 ENNMLN5 15;
BA_ "GenSigStartValue" SG_ 432 ENNMLN6 15;
BA_ "GenSigStartValue" SG_ 432 ENNMLN7 15;
BA_ "GenSigStartValue" SG_ 432 ENNMLN8 15;
BA_ "GenSigStartValue" SG_ 432 ENNMLN9 15;
BA_ "GenSigStartValue" SG_ 432 ENNMLN10 15;
BA_ "GenSigStartValue" SG_ 432 ENNMLN11 15;
BA_ "GenSigStartValue" SG_ 432 ENNMLN12 15;
BA_ "GenSigStartValue" SG_ 432 ENLNTY3 1023;
BA_ "GenSigStartValue" SG_ 432 ENRDTY3 31;
BA_ "GenSigStartValue" SG_ 432 ENRDTY1 31;
BA_ "GenSigStartValue" SG_ 432 ENRDTY2 31;
BA_ "GenSigStartValue" SG_ 432 ENLNTY1 1023;
BA_ "GenSigStartValue" SG_ 432 ENLNTY2 1023;
BA_ "GenSigStartValue" SG_ 435 FRMSID10 31;
BA_ "GenSigStartValue" SG_ 435 ENSIG4 3;
BA_ "GenSigStartValue" SG_ 435 ENSIG5 3;
BA_ "GenSigStartValue" SG_ 435 ENSIG6 3;
BA_ "GenSigStartValue" SG_ 435 ENSIG7 3;
BA_ "GenSigStartValue" SG_ 435 ENSIG8 3;
BA_ "GenSigStartValue" SG_ 435 ENSIG9 3;
BA_ "GenSigStartValue" SG_ 435 ENSIG10 3;
BA_ "GenSigStartValue" SG_ 435 ENSIG11 3;
BA_ "GenSigStartValue" SG_ 435 ENSIG12 3;
BA_ "GenSigStartValue" SG_ 435 ENSIBD4 7;
BA_ "GenSigStartValue" SG_ 435 ENSIBD5 7;
BA_ "GenSigStartValue" SG_ 435 ENSIBD6 7;
BA_ "GenSigStartValue" SG_ 435 ENSIBD7 7;
BA_ "GenSigStartValue" SG_ 435 ENSIBD8 7;
BA_ "GenSigStartValue" SG_ 435 ENSIBD9 7;
BA_ "GenSigStartValue" SG_ 435 ENSIBD10 7;
BA_ "GenSigStartValue" SG_ 435 ENSIBD11 7;
BA_ "GenSigStartValue" SG_ 435 ENSIBD12 7;
BA_ "GenSigStartValue" SG_ 435 ALRDTY4 31;
BA_ "GenSigStartValue" SG_ 435 ALRDTY5 31;
BA_ "GenSigStartValue" SG_ 435 ALRDTY6 31;
BA_ "GenSigStartValue" SG_ 435 ALRDTY7 31;
BA_ "GenSigStartValue" SG_ 435 ALRDTY8 31;
BA_ "GenSigStartValue" SG_ 435 ALRDTY9 31;
BA_ "GenSigStartValue" SG_ 435 ALRDTY10 31;
BA_ "GenSigStartValue" SG_ 435 ALRDTY11 31;
BA_ "GenSigStartValue" SG_ 435 ALRDTY12 31;
BA_ "GenSigStartValue" SG_ 435 ALTYP4 1023;
BA_ "GenSigStartValue" SG_ 435 ALTYP5 1023;
BA_ "GenSigStartValue" SG_ 435 ALTYP6 1023;
BA_ "GenSigStartValue" SG_ 435 ALTYP7 1023;
BA_ "GenSigStartValue" SG_ 435 ALTYP8 1023;
BA_ "GenSigStartValue" SG_ 435 ALTYP9 1023;
BA_ "GenSigStartValue" SG_ 435 ALTYP10 1023;
BA_ "GenSigStartValue" SG_ 435 ENPRI1 3;
BA_ "GenSigStartValue" SG_ 435 ENPRI2 3;
BA_ "GenSigStartValue" SG_ 435 ENPRI3 3;
BA_ "GenSigStartValue" SG_ 435 ENPRI4 3;
BA_ "GenSigStartValue" SG_ 435 ENPRI5 3;
BA_ "GenSigStartValue" SG_ 435 ENPRI6 3;
BA_ "GenSigStartValue" SG_ 435 ENPRI7 3;
BA_ "GenSigStartValue" SG_ 435 ENPRI8 3;
BA_ "GenSigStartValue" SG_ 435 ENPRI9 3;
BA_ "GenSigStartValue" SG_ 435 ENPRI10 3;
BA_ "GenSigStartValue" SG_ 435 ENPRI11 3;
BA_ "GenSigStartValue" SG_ 435 ENPRI12 3;
BA_ "GenSigStartValue" SG_ 435 ENSIG3 3;
BA_ "GenSigStartValue" SG_ 435 ENSIBD3 7;
BA_ "GenSigStartValue" SG_ 435 ENSIG1 3;
BA_ "GenSigStartValue" SG_ 435 ENSIG2 3;
BA_ "GenSigStartValue" SG_ 435 ALTYP1 1023;
BA_ "GenSigStartValue" SG_ 435 ALRDTY1 31;
BA_ "GenSigStartValue" SG_ 435 ALTYP2 1023;
BA_ "GenSigStartValue" SG_ 435 ALRDTY2 31;
BA_ "GenSigStartValue" SG_ 435 ENSIBD1 7;
BA_ "GenSigStartValue" SG_ 435 ENSIBD2 7;
BA_ "GenSigStartValue" SG_ 435 ALRDTY3 31;
BA_ "GenSigStartValue" SG_ 435 ALTYP3 1023;
BA_ "GenSigStartValue" SG_ 436 FRMSID11 31;
BA_ "GenSigStartValue" SG_ 436 ALTYP11 1023;
BA_ "GenSigStartValue" SG_ 436 ALTYP12 1023;
BA_ "GenSigStartValue" SG_ 436 ALNLN4 15;
BA_ "GenSigStartValue" SG_ 436 ALNLN5 15;
BA_ "GenSigStartValue" SG_ 436 ALNLN6 15;
BA_ "GenSigStartValue" SG_ 436 ALNLN7 15;
BA_ "GenSigStartValue" SG_ 436 ALNLN8 15;
BA_ "GenSigStartValue" SG_ 436 ALNLN9 15;
BA_ "GenSigStartValue" SG_ 436 ALNLN10 15;
BA_ "GenSigStartValue" SG_ 436 ALNLN11 15;
BA_ "GenSigStartValue" SG_ 436 ALNLN12 15;
BA_ "GenSigStartValue" SG_ 436 ALNSIG1 3;
BA_ "GenSigStartValue" SG_ 436 ALNSIG2 3;
BA_ "GenSigStartValue" SG_ 436 ALNSIG3 3;
BA_ "GenSigStartValue" SG_ 436 ALNSIG4 3;
BA_ "GenSigStartValue" SG_ 436 ALNSIG5 3;
BA_ "GenSigStartValue" SG_ 436 ALNSIG6 3;
BA_ "GenSigStartValue" SG_ 436 ALNSIG7 3;
BA_ "GenSigStartValue" SG_ 436 ALNSIG8 3;
BA_ "GenSigStartValue" SG_ 436 ALNSIG9 3;
BA_ "GenSigStartValue" SG_ 436 ALNSIG10 3;
BA_ "GenSigStartValue" SG_ 436 ALNSIG11 3;
BA_ "GenSigStartValue" SG_ 436 ALNSIG12 3;
BA_ "GenSigStartValue" SG_ 436 ALNSBD1 7;
BA_ "GenSigStartValue" SG_ 436 ALNSBD2 7;
BA_ "GenSigStartValue" SG_ 436 ALNSBD3 7;
BA_ "GenSigStartValue" SG_ 436 ALNSBD4 7;
BA_ "GenSigStartValue" SG_ 436 ALNSBD5 7;
BA_ "GenSigStartValue" SG_ 436 ALNSBD6 7;
BA_ "GenSigStartValue" SG_ 436 ALNSBD7 7;
BA_ "GenSigStartValue" SG_ 436 ALNSBD8 7;
BA_ "GenSigStartValue" SG_ 436 ALNSBD9 7;
BA_ "GenSigStartValue" SG_ 436 ALNSBD10 7;
BA_ "GenSigStartValue" SG_ 436 ALNSBD11 7;
BA_ "GenSigStartValue" SG_ 436 ALNSBD12 7;
BA_ "GenSigStartValue" SG_ 436 ALNOW1 7;
BA_ "GenSigStartValue" SG_ 436 ALNOW2 7;
BA_ "GenSigStartValue" SG_ 436 ALNOW3 7;
BA_ "GenSigStartValue" SG_ 436 ALNOW4 7;
BA_ "GenSigStartValue" SG_ 436 ALNOW5 7;
BA_ "GenSigStartValue" SG_ 436 ALNOW6 7;
BA_ "GenSigStartValue" SG_ 436 ALNOW7 7;
BA_ "GenSigStartValue" SG_ 436 ALNOW8 7;
BA_ "GenSigStartValue" SG_ 436 ALNOW9 7;
BA_ "GenSigStartValue" SG_ 436 ALNOW10 7;
BA_ "GenSigStartValue" SG_ 436 ALNOW11 7;
BA_ "GenSigStartValue" SG_ 436 ALNOW12 7;
BA_ "GenSigStartValue" SG_ 436 ALNEN1 3;
BA_ "GenSigStartValue" SG_ 436 ALNEN2 3;
BA_ "GenSigStartValue" SG_ 436 ALNEN3 3;
BA_ "GenSigStartValue" SG_ 436 ALNEN4 3;
BA_ "GenSigStartValue" SG_ 436 ALNEN5 3;
BA_ "GenSigStartValue" SG_ 436 ALNEN6 3;
BA_ "GenSigStartValue" SG_ 436 ALNEN7 3;
BA_ "GenSigStartValue" SG_ 436 ALNEN8 3;
BA_ "GenSigStartValue" SG_ 436 ALNEN9 3;
BA_ "GenSigStartValue" SG_ 436 ALNEN10 3;
BA_ "GenSigStartValue" SG_ 436 ALNEN11 3;
BA_ "GenSigStartValue" SG_ 436 ALNEN12 3;
BA_ "GenSigStartValue" SG_ 436 ALANG4 31;
BA_ "GenSigStartValue" SG_ 436 ALANG5 31;
BA_ "GenSigStartValue" SG_ 436 ALANG6 31;
BA_ "GenSigStartValue" SG_ 436 ALANG7 31;
BA_ "GenSigStartValue" SG_ 436 ALANG8 31;
BA_ "GenSigStartValue" SG_ 436 ALANG9 31;
BA_ "GenSigStartValue" SG_ 436 ALANG10 31;
BA_ "GenSigStartValue" SG_ 436 ALANG11 31;
BA_ "GenSigStartValue" SG_ 436 ALANG12 31;
BA_ "GenSigStartValue" SG_ 436 ALANG1 31;
BA_ "GenSigStartValue" SG_ 436 ALANG2 31;
BA_ "GenSigStartValue" SG_ 436 ALNLN1 15;
BA_ "GenSigStartValue" SG_ 436 ALNLN2 15;
BA_ "GenSigStartValue" SG_ 436 ALNLN3 15;
BA_ "GenSigStartValue" SG_ 436 ALANG3 31;
BA_ "GenSigStartValue" SG_ 430 FRMSID12 31;
BA_ "GenSigStartValue" SG_ 430 ALCINF1 3;
BA_ "GenSigStartValue" SG_ 430 ALCINF2 3;
BA_ "GenSigStartValue" SG_ 430 ALCINF3 3;
BA_ "GenSigStartValue" SG_ 430 ALCINF4 3;
BA_ "GenSigStartValue" SG_ 430 ALCINF5 3;
BA_ "GenSigStartValue" SG_ 430 ALCINF6 3;
BA_ "GenSigStartValue" SG_ 430 ALCINF7 3;
BA_ "GenSigStartValue" SG_ 430 ALCINF8 3;
BA_ "GenSigStartValue" SG_ 430 ALCINF9 3;
BA_ "GenSigStartValue" SG_ 430 ALCINF10 3;
BA_ "GenSigStartValue" SG_ 430 ALCINF11 3;
BA_ "GenSigStartValue" SG_ 430 ALCINF12 3;
BA_ "GenSigStartValue" SG_ 430 NALINT7 31;
BA_ "GenSigStartValue" SG_ 430 NALINT8 31;
BA_ "GenSigStartValue" SG_ 430 NALINT9 31;
BA_ "GenSigStartValue" SG_ 430 NALINT10 31;
BA_ "GenSigStartValue" SG_ 430 NALINT11 31;
BA_ "GenSigStartValue" SG_ 430 NALINT12 31;
BA_ "GenSigStartValue" SG_ 430 NALINT13 31;
BA_ "GenSigStartValue" SG_ 430 NALINT14 31;
BA_ "GenSigStartValue" SG_ 430 NALINT15 31;
BA_ "GenSigStartValue" SG_ 430 NALINT16 31;
BA_ "GenSigStartValue" SG_ 430 NALINT17 31;
BA_ "GenSigStartValue" SG_ 430 NALINT18 31;
BA_ "GenSigStartValue" SG_ 430 NALINT19 31;
BA_ "GenSigStartValue" SG_ 430 NALINT20 31;
BA_ "GenSigStartValue" SG_ 430 NALINT21 31;
BA_ "GenSigStartValue" SG_ 430 NALINT22 31;
BA_ "GenSigStartValue" SG_ 430 NALINT23 31;
BA_ "GenSigStartValue" SG_ 430 NALINT24 31;
BA_ "GenSigStartValue" SG_ 430 NALRDT1 31;
BA_ "GenSigStartValue" SG_ 430 NALRDT2 31;
BA_ "GenSigStartValue" SG_ 430 NALRDT3 31;
BA_ "GenSigStartValue" SG_ 430 NALRDT4 31;
BA_ "GenSigStartValue" SG_ 430 NALRDT5 31;
BA_ "GenSigStartValue" SG_ 430 NALRDT6 31;
BA_ "GenSigStartValue" SG_ 430 NALRDT7 31;
BA_ "GenSigStartValue" SG_ 430 NALRDT8 31;
BA_ "GenSigStartValue" SG_ 430 NALRDT9 31;
BA_ "GenSigStartValue" SG_ 430 NALRDT10 31;
BA_ "GenSigStartValue" SG_ 430 NALRDT11 31;
BA_ "GenSigStartValue" SG_ 430 ALPRI1 3;
BA_ "GenSigStartValue" SG_ 430 ALPRI2 3;
BA_ "GenSigStartValue" SG_ 430 ALPRI3 3;
BA_ "GenSigStartValue" SG_ 430 ALPRI4 3;
BA_ "GenSigStartValue" SG_ 430 ALPRI5 3;
BA_ "GenSigStartValue" SG_ 430 ALPRI6 3;
BA_ "GenSigStartValue" SG_ 430 ALPRI7 3;
BA_ "GenSigStartValue" SG_ 430 ALPRI8 3;
BA_ "GenSigStartValue" SG_ 430 ALPRI9 3;
BA_ "GenSigStartValue" SG_ 430 ALPRI10 3;
BA_ "GenSigStartValue" SG_ 430 ALPRI11 3;
BA_ "GenSigStartValue" SG_ 430 ALPRI12 3;
BA_ "GenSigStartValue" SG_ 430 ALALF1 3;
BA_ "GenSigStartValue" SG_ 430 ALALF2 3;
BA_ "GenSigStartValue" SG_ 430 ALALF3 3;
BA_ "GenSigStartValue" SG_ 430 ALALF4 3;
BA_ "GenSigStartValue" SG_ 430 ALALF5 3;
BA_ "GenSigStartValue" SG_ 430 ALALF6 3;
BA_ "GenSigStartValue" SG_ 430 ALALF7 3;
BA_ "GenSigStartValue" SG_ 430 ALALF8 3;
BA_ "GenSigStartValue" SG_ 430 ALALF9 3;
BA_ "GenSigStartValue" SG_ 430 ALALF10 3;
BA_ "GenSigStartValue" SG_ 430 ALALF11 3;
BA_ "GenSigStartValue" SG_ 430 ALALF12 3;
BA_ "GenSigStartValue" SG_ 430 NALINT1 31;
BA_ "GenSigStartValue" SG_ 430 NALINT2 31;
BA_ "GenSigStartValue" SG_ 430 NALINT3 31;
BA_ "GenSigStartValue" SG_ 430 NALINT4 31;
BA_ "GenSigStartValue" SG_ 430 NALINT5 31;
BA_ "GenSigStartValue" SG_ 430 NALINT6 31;
BA_ "GenSigStartValue" SG_ 424 FRMSID13 31;
BA_ "GenSigStartValue" SG_ 424 NALRDT12 31;
BA_ "GenSigStartValue" SG_ 424 NALRDT13 31;
BA_ "GenSigStartValue" SG_ 424 NALRDT14 31;
BA_ "GenSigStartValue" SG_ 424 NALRDT15 31;
BA_ "GenSigStartValue" SG_ 424 NALRDT16 31;
BA_ "GenSigStartValue" SG_ 424 NALRDT17 31;
BA_ "GenSigStartValue" SG_ 424 NALRDT18 31;
BA_ "GenSigStartValue" SG_ 424 NALRDT19 31;
BA_ "GenSigStartValue" SG_ 424 NALRDT20 31;
BA_ "GenSigStartValue" SG_ 424 NALRDT21 31;
BA_ "GenSigStartValue" SG_ 424 NALRDT22 31;
BA_ "GenSigStartValue" SG_ 424 NALRDT23 31;
BA_ "GenSigStartValue" SG_ 424 NALRDT24 31;
BA_ "GenSigStartValue" SG_ 424 NALTYP7 1023;
BA_ "GenSigStartValue" SG_ 424 NALTYP8 1023;
BA_ "GenSigStartValue" SG_ 424 NALTYP9 1023;
BA_ "GenSigStartValue" SG_ 424 NALTYP10 1023;
BA_ "GenSigStartValue" SG_ 424 NALTYP11 1023;
BA_ "GenSigStartValue" SG_ 424 NALTYP12 1023;
BA_ "GenSigStartValue" SG_ 424 NALTYP13 1023;
BA_ "GenSigStartValue" SG_ 424 NALTYP14 1023;
BA_ "GenSigStartValue" SG_ 424 NALTYP15 1023;
BA_ "GenSigStartValue" SG_ 424 NALTYP16 1023;
BA_ "GenSigStartValue" SG_ 424 NALTYP17 1023;
BA_ "GenSigStartValue" SG_ 424 NALTYP18 1023;
BA_ "GenSigStartValue" SG_ 424 NALTYP1 1023;
BA_ "GenSigStartValue" SG_ 424 NALTYP2 1023;
BA_ "GenSigStartValue" SG_ 424 NALTYP3 1023;
BA_ "GenSigStartValue" SG_ 424 NALTYP4 1023;
BA_ "GenSigStartValue" SG_ 424 NALTYP5 1023;
BA_ "GenSigStartValue" SG_ 424 NALTYP6 1023;
BA_ "GenSigStartValue" SG_ 425 FRMSID14 31;
BA_ "GenSigStartValue" SG_ 425 NALTYP19 1023;
BA_ "GenSigStartValue" SG_ 425 NALTYP20 1023;
BA_ "GenSigStartValue" SG_ 425 NALTYP21 1023;
BA_ "GenSigStartValue" SG_ 425 NALTYP22 1023;
BA_ "GenSigStartValue" SG_ 425 NALTYP23 1023;
BA_ "GenSigStartValue" SG_ 425 NALTYP24 1023;
BA_ "GenSigStartValue" SG_ 425 NALNLN7 15;
BA_ "GenSigStartValue" SG_ 425 NALNLN8 15;
BA_ "GenSigStartValue" SG_ 425 NALNLN9 15;
BA_ "GenSigStartValue" SG_ 425 NALNLN10 15;
BA_ "GenSigStartValue" SG_ 425 NALNLN11 15;
BA_ "GenSigStartValue" SG_ 425 NALNLN12 15;
BA_ "GenSigStartValue" SG_ 425 NALNLN13 15;
BA_ "GenSigStartValue" SG_ 425 NALNLN14 15;
BA_ "GenSigStartValue" SG_ 425 NALNLN15 15;
BA_ "GenSigStartValue" SG_ 425 NALNLN16 15;
BA_ "GenSigStartValue" SG_ 425 NALNLN17 15;
BA_ "GenSigStartValue" SG_ 425 NALNLN18 15;
BA_ "GenSigStartValue" SG_ 425 NALNLN19 15;
BA_ "GenSigStartValue" SG_ 425 NALNLN20 15;
BA_ "GenSigStartValue" SG_ 425 NALNLN21 15;
BA_ "GenSigStartValue" SG_ 425 NALNLN22 15;
BA_ "GenSigStartValue" SG_ 425 NALNLN23 15;
BA_ "GenSigStartValue" SG_ 425 NALNLN24 15;
BA_ "GenSigStartValue" SG_ 425 NALSIG1 3;
BA_ "GenSigStartValue" SG_ 425 NALSIG2 3;
BA_ "GenSigStartValue" SG_ 425 NALSIG3 3;
BA_ "GenSigStartValue" SG_ 425 NALSIG4 3;
BA_ "GenSigStartValue" SG_ 425 NALSIG5 3;
BA_ "GenSigStartValue" SG_ 425 NALSIG6 3;
BA_ "GenSigStartValue" SG_ 425 NALSIG7 3;
BA_ "GenSigStartValue" SG_ 425 NALSIG8 3;
BA_ "GenSigStartValue" SG_ 425 NALSIG9 3;
BA_ "GenSigStartValue" SG_ 425 NALSIG10 3;
BA_ "GenSigStartValue" SG_ 425 NALSIG11 3;
BA_ "GenSigStartValue" SG_ 425 NALSIG12 3;
BA_ "GenSigStartValue" SG_ 425 NALSIG13 3;
BA_ "GenSigStartValue" SG_ 425 NALSIG14 3;
BA_ "GenSigStartValue" SG_ 425 NALSIG15 3;
BA_ "GenSigStartValue" SG_ 425 NALSIG16 3;
BA_ "GenSigStartValue" SG_ 425 NALSIG17 3;
BA_ "GenSigStartValue" SG_ 425 NALSIG18 3;
BA_ "GenSigStartValue" SG_ 425 NALSIG19 3;
BA_ "GenSigStartValue" SG_ 425 NALSIG20 3;
BA_ "GenSigStartValue" SG_ 425 NALSIG21 3;
BA_ "GenSigStartValue" SG_ 425 NALSIG22 3;
BA_ "GenSigStartValue" SG_ 425 NALSIG23 3;
BA_ "GenSigStartValue" SG_ 425 NALSIG24 3;
BA_ "GenSigStartValue" SG_ 425 NALSBD1 7;
BA_ "GenSigStartValue" SG_ 425 NALSBD2 7;
BA_ "GenSigStartValue" SG_ 425 NALSBD3 7;
BA_ "GenSigStartValue" SG_ 425 NALSBD4 7;
BA_ "GenSigStartValue" SG_ 425 NALSBD5 7;
BA_ "GenSigStartValue" SG_ 425 NALSBD6 7;
BA_ "GenSigStartValue" SG_ 425 NALSBD7 7;
BA_ "GenSigStartValue" SG_ 425 NALSBD8 7;
BA_ "GenSigStartValue" SG_ 425 NALSBD9 7;
BA_ "GenSigStartValue" SG_ 425 NALSBD10 7;
BA_ "GenSigStartValue" SG_ 425 NALSBD11 7;
BA_ "GenSigStartValue" SG_ 425 NALSBD12 7;
BA_ "GenSigStartValue" SG_ 425 NALSBD13 7;
BA_ "GenSigStartValue" SG_ 425 NALSBD14 7;
BA_ "GenSigStartValue" SG_ 425 NALSBD15 7;
BA_ "GenSigStartValue" SG_ 425 NALNLN1 15;
BA_ "GenSigStartValue" SG_ 425 NALNLN2 15;
BA_ "GenSigStartValue" SG_ 425 NALNLN3 15;
BA_ "GenSigStartValue" SG_ 425 NALNLN4 15;
BA_ "GenSigStartValue" SG_ 425 NALNLN5 15;
BA_ "GenSigStartValue" SG_ 425 NALNLN6 15;
BA_ "GenSigStartValue" SG_ 427 FRMSID15 31;
BA_ "GenSigStartValue" SG_ 427 NALSBD16 7;
BA_ "GenSigStartValue" SG_ 427 NALSBD17 7;
BA_ "GenSigStartValue" SG_ 427 NALSBD18 7;
BA_ "GenSigStartValue" SG_ 427 NALSBD19 7;
BA_ "GenSigStartValue" SG_ 427 NALSBD20 7;
BA_ "GenSigStartValue" SG_ 427 NALSBD21 7;
BA_ "GenSigStartValue" SG_ 427 NALSBD22 7;
BA_ "GenSigStartValue" SG_ 427 NALSBD23 7;
BA_ "GenSigStartValue" SG_ 427 NALSBD24 7;
BA_ "GenSigStartValue" SG_ 427 NALOW1 7;
BA_ "GenSigStartValue" SG_ 427 NALOW2 7;
BA_ "GenSigStartValue" SG_ 427 NALOW3 7;
BA_ "GenSigStartValue" SG_ 427 NALOW4 7;
BA_ "GenSigStartValue" SG_ 427 NALOW5 7;
BA_ "GenSigStartValue" SG_ 427 NALOW6 7;
BA_ "GenSigStartValue" SG_ 427 NALOW7 7;
BA_ "GenSigStartValue" SG_ 427 NALOW8 7;
BA_ "GenSigStartValue" SG_ 427 NALOW9 7;
BA_ "GenSigStartValue" SG_ 427 NALOW10 7;
BA_ "GenSigStartValue" SG_ 427 NALOW11 7;
BA_ "GenSigStartValue" SG_ 427 NALOW12 7;
BA_ "GenSigStartValue" SG_ 427 NALOW13 7;
BA_ "GenSigStartValue" SG_ 427 NALOW14 7;
BA_ "GenSigStartValue" SG_ 427 NALOW15 7;
BA_ "GenSigStartValue" SG_ 427 NALOW16 7;
BA_ "GenSigStartValue" SG_ 427 NALOW17 7;
BA_ "GenSigStartValue" SG_ 427 NALOW18 7;
BA_ "GenSigStartValue" SG_ 427 NALOW19 7;
BA_ "GenSigStartValue" SG_ 427 NALOW20 7;
BA_ "GenSigStartValue" SG_ 427 NALOW21 7;
BA_ "GenSigStartValue" SG_ 427 NALOW22 7;
BA_ "GenSigStartValue" SG_ 427 NALOW23 7;
BA_ "GenSigStartValue" SG_ 427 NALOW24 7;
BA_ "GenSigStartValue" SG_ 427 NALNEN7 3;
BA_ "GenSigStartValue" SG_ 427 NALNEN8 3;
BA_ "GenSigStartValue" SG_ 427 NALNEN9 3;
BA_ "GenSigStartValue" SG_ 427 NALNEN10 3;
BA_ "GenSigStartValue" SG_ 427 NALNEN11 3;
BA_ "GenSigStartValue" SG_ 427 NALNEN12 3;
BA_ "GenSigStartValue" SG_ 427 NALNEN13 3;
BA_ "GenSigStartValue" SG_ 427 NALNEN14 3;
BA_ "GenSigStartValue" SG_ 427 NALNEN15 3;
BA_ "GenSigStartValue" SG_ 427 NALNEN16 3;
BA_ "GenSigStartValue" SG_ 427 NALNEN17 3;
BA_ "GenSigStartValue" SG_ 427 NALNEN18 3;
BA_ "GenSigStartValue" SG_ 427 NALNEN19 3;
BA_ "GenSigStartValue" SG_ 427 NALNEN20 3;
BA_ "GenSigStartValue" SG_ 427 NALNEN21 3;
BA_ "GenSigStartValue" SG_ 427 NALNEN22 3;
BA_ "GenSigStartValue" SG_ 427 NALNEN23 3;
BA_ "GenSigStartValue" SG_ 427 NALNEN24 3;
BA_ "GenSigStartValue" SG_ 427 NALANG7 31;
BA_ "GenSigStartValue" SG_ 427 NALANG8 31;
BA_ "GenSigStartValue" SG_ 427 NALANG9 31;
BA_ "GenSigStartValue" SG_ 427 NALANG10 31;
BA_ "GenSigStartValue" SG_ 427 NALANG11 31;
BA_ "GenSigStartValue" SG_ 427 NALANG12 31;
BA_ "GenSigStartValue" SG_ 427 NALANG13 31;
BA_ "GenSigStartValue" SG_ 427 NALANG14 31;
BA_ "GenSigStartValue" SG_ 427 NALANG15 31;
BA_ "GenSigStartValue" SG_ 427 NALANG16 31;
BA_ "GenSigStartValue" SG_ 427 NALANG17 31;
BA_ "GenSigStartValue" SG_ 427 NALANG18 31;
BA_ "GenSigStartValue" SG_ 427 NALANG19 31;
BA_ "GenSigStartValue" SG_ 427 NALANG20 31;
BA_ "GenSigStartValue" SG_ 427 NALNEN1 3;
BA_ "GenSigStartValue" SG_ 427 NALANG1 31;
BA_ "GenSigStartValue" SG_ 427 NALNEN2 3;
BA_ "GenSigStartValue" SG_ 427 NALANG2 31;
BA_ "GenSigStartValue" SG_ 427 NALNEN3 3;
BA_ "GenSigStartValue" SG_ 427 NALANG3 31;
BA_ "GenSigStartValue" SG_ 427 NALNEN4 3;
BA_ "GenSigStartValue" SG_ 427 NALANG4 31;
BA_ "GenSigStartValue" SG_ 427 NALNEN5 3;
BA_ "GenSigStartValue" SG_ 427 NALANG5 31;
BA_ "GenSigStartValue" SG_ 427 NALNEN6 3;
BA_ "GenSigStartValue" SG_ 427 NALANG6 31;
BA_ "GenSigStartValue" SG_ 428 FRMSID16 31;
BA_ "GenSigStartValue" SG_ 428 BRDIST1 255;
BA_ "GenSigStartValue" SG_ 428 BRDIST2 255;
BA_ "GenSigStartValue" SG_ 428 BRDIST3 255;
BA_ "GenSigStartValue" SG_ 428 BRLEN1 255;
BA_ "GenSigStartValue" SG_ 428 BRLEN2 255;
BA_ "GenSigStartValue" SG_ 428 BRLEN3 255;
BA_ "GenSigStartValue" SG_ 428 NALANG21 31;
BA_ "GenSigStartValue" SG_ 428 NALANG22 31;
BA_ "GenSigStartValue" SG_ 428 NALANG23 31;
BA_ "GenSigStartValue" SG_ 428 NALANG24 31;
BA_ "GenSigStartValue" SG_ 428 NALCNF1 3;
BA_ "GenSigStartValue" SG_ 428 NALCNF2 3;
BA_ "GenSigStartValue" SG_ 428 NALCNF3 3;
BA_ "GenSigStartValue" SG_ 428 NALCNF4 3;
BA_ "GenSigStartValue" SG_ 428 NALCNF5 3;
BA_ "GenSigStartValue" SG_ 428 NALCNF6 3;
BA_ "GenSigStartValue" SG_ 428 NALCNF7 3;
BA_ "GenSigStartValue" SG_ 428 NALCNF8 3;
BA_ "GenSigStartValue" SG_ 428 NALCNF9 3;
BA_ "GenSigStartValue" SG_ 428 NALCNF10 3;
BA_ "GenSigStartValue" SG_ 428 NALCNF11 3;
BA_ "GenSigStartValue" SG_ 428 NALCNF12 3;
BA_ "GenSigStartValue" SG_ 428 NALCNF13 3;
BA_ "GenSigStartValue" SG_ 428 NALCNF14 3;
BA_ "GenSigStartValue" SG_ 428 NALCNF15 3;
BA_ "GenSigStartValue" SG_ 428 NALCNF16 3;
BA_ "GenSigStartValue" SG_ 428 NALCNF17 3;
BA_ "GenSigStartValue" SG_ 428 NALCNF18 3;
BA_ "GenSigStartValue" SG_ 428 NALCNF19 3;
BA_ "GenSigStartValue" SG_ 428 NALCNF20 3;
BA_ "GenSigStartValue" SG_ 428 NALCNF21 3;
BA_ "GenSigStartValue" SG_ 428 NALCNF22 3;
BA_ "GenSigStartValue" SG_ 428 NALCNF23 3;
BA_ "GenSigStartValue" SG_ 428 NALCNF24 3;
BA_ "GenSigStartValue" SG_ 428 NALDIV1 7;
BA_ "GenSigStartValue" SG_ 428 NALDIV2 7;
BA_ "GenSigStartValue" SG_ 428 NALDIV3 7;
BA_ "GenSigStartValue" SG_ 428 NALDIV4 7;
BA_ "GenSigStartValue" SG_ 428 NALDIV5 7;
BA_ "GenSigStartValue" SG_ 428 NALDIV6 7;
BA_ "GenSigStartValue" SG_ 428 NALDIV7 7;
BA_ "GenSigStartValue" SG_ 428 NALDIV8 7;
BA_ "GenSigStartValue" SG_ 428 NALDIV9 7;
BA_ "GenSigStartValue" SG_ 428 NALDIV10 7;
BA_ "GenSigStartValue" SG_ 428 NALDIV11 7;
BA_ "GenSigStartValue" SG_ 428 NALDIV12 7;
BA_ "GenSigStartValue" SG_ 428 NALDIV13 7;
BA_ "GenSigStartValue" SG_ 428 NALDIV14 7;
BA_ "GenSigStartValue" SG_ 428 NALDIV15 7;
BA_ "GenSigStartValue" SG_ 428 NALDIV16 7;
BA_ "GenSigStartValue" SG_ 428 NALDIV17 7;
BA_ "GenSigStartValue" SG_ 428 NALDIV18 7;
BA_ "GenSigStartValue" SG_ 428 NALDIV19 7;
BA_ "GenSigStartValue" SG_ 428 NALDIV20 7;
BA_ "GenSigStartValue" SG_ 428 NALDIV21 7;
BA_ "GenSigStartValue" SG_ 428 NALDIV22 7;
BA_ "GenSigStartValue" SG_ 428 NALDIV23 7;
BA_ "GenSigStartValue" SG_ 428 NALDIV24 7;
BA_ "GenSigStartValue" SG_ 428 NALPRI1 3;
BA_ "GenSigStartValue" SG_ 428 NALPRI2 3;
BA_ "GenSigStartValue" SG_ 428 NALPRI3 3;
BA_ "GenSigStartValue" SG_ 428 NALPRI4 3;
BA_ "GenSigStartValue" SG_ 428 NALPRI5 3;
BA_ "GenSigStartValue" SG_ 428 NALPRI6 3;
BA_ "GenSigStartValue" SG_ 428 NALPRI7 3;
BA_ "GenSigStartValue" SG_ 428 NALPRI8 3;
BA_ "GenSigStartValue" SG_ 428 NALPRI9 3;
BA_ "GenSigStartValue" SG_ 428 NALPRI10 3;
BA_ "GenSigStartValue" SG_ 428 NALPRI11 3;
BA_ "GenSigStartValue" SG_ 428 NALPRI12 3;
BA_ "GenSigStartValue" SG_ 428 NALPRI13 3;
BA_ "GenSigStartValue" SG_ 428 NALPRI14 3;
BA_ "GenSigStartValue" SG_ 428 NALPRI15 3;
BA_ "GenSigStartValue" SG_ 428 NALPRI16 3;
BA_ "GenSigStartValue" SG_ 428 NALPRI17 3;
BA_ "GenSigStartValue" SG_ 428 NALPRI18 3;
BA_ "GenSigStartValue" SG_ 428 NALPRI19 3;
BA_ "GenSigStartValue" SG_ 428 NALPRI20 3;
BA_ "GenSigStartValue" SG_ 428 NALPRI21 3;
BA_ "GenSigStartValue" SG_ 428 NALPRI22 3;
BA_ "GenSigStartValue" SG_ 428 NALPRI23 3;
BA_ "GenSigStartValue" SG_ 428 NALPRI24 3;
BA_ "GenSigStartValue" SG_ 428 NALALF1 3;
BA_ "GenSigStartValue" SG_ 428 NALALF2 3;
BA_ "GenSigStartValue" SG_ 428 NALALF3 3;
BA_ "GenSigStartValue" SG_ 428 NALALF4 3;
BA_ "GenSigStartValue" SG_ 421 FMMC1 2147483647;
BA_ "GenSigStartValue" SG_ 421 FMMC2 2147483647;
BA_ "GenSigStartValue" SG_ 421 MPOTJ 7;
BA_ "GenSigStartValue" SG_ 421 FWTJ1 7;
BA_ "GenSigStartValue" SG_ 421 FWTJ2 7;
BA_ "GenSigStartValue" SG_ 421 FWTJ3 7;
BA_ "GenSigStartValue" SG_ 421 FWTJ4 7;
BA_ "GenSigStartValue" SG_ 421 FWTJ5 7;
BA_ "GenSigStartValue" SG_ 421 FWTJ6 7;
BA_ "GenSigStartValue" SG_ 421 TJDIST1 255;
BA_ "GenSigStartValue" SG_ 421 TJDIST2 255;
BA_ "GenSigStartValue" SG_ 421 TJDIST3 255;
BA_ "GenSigStartValue" SG_ 421 TJDIST4 255;
BA_ "GenSigStartValue" SG_ 421 TJDIST5 255;
BA_ "GenSigStartValue" SG_ 421 TJDIST6 255;
BA_ "GenSigStartValue" SG_ 421 SBSTDT 255;
BA_ "GenSigStartValue" SG_ 421 SBLEN 255;
BA_ "GenSigStartValue" SG_ 421 NALALF5 3;
BA_ "GenSigStartValue" SG_ 421 NALALF6 3;
BA_ "GenSigStartValue" SG_ 421 NALALF7 3;
BA_ "GenSigStartValue" SG_ 421 NALALF8 3;
BA_ "GenSigStartValue" SG_ 421 NALALF9 3;
BA_ "GenSigStartValue" SG_ 421 NALALF10 3;
BA_ "GenSigStartValue" SG_ 421 NALALF11 3;
BA_ "GenSigStartValue" SG_ 421 NALALF12 3;
BA_ "GenSigStartValue" SG_ 421 NALALF13 3;
BA_ "GenSigStartValue" SG_ 421 NALALF14 3;
BA_ "GenSigStartValue" SG_ 421 NALALF15 3;
BA_ "GenSigStartValue" SG_ 421 NALALF16 3;
BA_ "GenSigStartValue" SG_ 421 NALALF17 3;
BA_ "GenSigStartValue" SG_ 421 NALALF18 3;
BA_ "GenSigStartValue" SG_ 421 NALALF19 3;
BA_ "GenSigStartValue" SG_ 421 NALALF20 3;
BA_ "GenSigStartValue" SG_ 421 NALALF21 3;
BA_ "GenSigStartValue" SG_ 421 NALALF22 3;
BA_ "GenSigStartValue" SG_ 421 NALALF23 3;
BA_ "GenSigStartValue" SG_ 421 NALALF24 3;
BA_ "GenSigStartValue" SG_ 421 FRMSID17 31;
BA_ "GenSigStartValue" SG_ 423 FLID 4294967295;
BA_ "GenSigStartValue" SG_ 423 FDLID 65535;
BA_ "GenSigStartValue" SG_ 423 FRCODE 65535;
BA_ "GenSigStartValue" SG_ 423 FDLINKP 65535;
BA_ "GenSigStartValue" SG_ 423 MPOAVSP 31;
BA_ "GenSigStartValue" SG_ 423 MPOAVSPU 3;
BA_ "GenSigStartValue" SG_ 423 FWAVSP1 31;
BA_ "GenSigStartValue" SG_ 423 FWAVSP2 31;
BA_ "GenSigStartValue" SG_ 423 FWAVSP3 31;
BA_ "GenSigStartValue" SG_ 423 FWAVSP4 31;
BA_ "GenSigStartValue" SG_ 423 FWAVSP5 31;
BA_ "GenSigStartValue" SG_ 423 FWAVSP6 31;
BA_ "GenSigStartValue" SG_ 423 FWAVSPU1 3;
BA_ "GenSigStartValue" SG_ 423 FWAVSPU2 3;
BA_ "GenSigStartValue" SG_ 423 FWAVSPU3 3;
BA_ "GenSigStartValue" SG_ 423 FWAVSPU4 3;
BA_ "GenSigStartValue" SG_ 423 FWAVSPU5 3;
BA_ "GenSigStartValue" SG_ 423 FWAVSPU6 3;
BA_ "GenSigStartValue" SG_ 423 AVSPDT1 255;
BA_ "GenSigStartValue" SG_ 423 AVSPDT2 255;
BA_ "GenSigStartValue" SG_ 423 AVSPDT3 255;
BA_ "GenSigStartValue" SG_ 423 AVSPDT4 255;
BA_ "GenSigStartValue" SG_ 423 AVSPDT5 255;
BA_ "GenSigStartValue" SG_ 423 AVSPDT6 255;
BA_ "GenSigStartValue" SG_ 423 FRMSID18 31;
BA_ "GenSigSendType" SG_ 419 USMNCRN 3;
BA_ "GenSigSendType" SG_ 419 USMCRN6 3;
BA_ "GenSigSendType" SG_ 419 USMCRN5 3;
BA_ "GenSigSendType" SG_ 759 BD_CLR_1 3;
BA_ "GenSigSendType" SG_ 759 BD_CLR_2 3;
BA_ "GenSigSendType" SG_ 759 BD_CLR_3 3;
BA_ "GenSigSendType" SG_ 759 BD_CLR_4 3;
BA_ "GenSigSendType" SG_ 759 BD_CLR_5 3;
BA_ "GenSigSendType" SG_ 759 BD_CLR_6 3;
BA_ "GenSigSendType" SG_ 759 BD_CLR_7 3;
BA_ "GenSigSendType" SG_ 759 BD_CLR_8 3;
BA_ "GenSigSendType" SG_ 759 CD_DSPST 3;
BA_ "GenSigSendType" SG_ 759 PVM_REQ 3;
